VERSION ""

NS_ :

BS_:

BU_: Sound_A Ladegeraet_PAG_PF Motor_EDC17_Pirol PSM_Ant_Derivate GW_Routing_Derivate GW_Applikation_Derivate BMS_Hybrid Getriebe_Derivate LEH_Hybrid Motor_MED17_Hybrid Sound_I Tool Airbag Waehlhebel

BO_ 1445 OBC_CALID_CVN: 8 Ladegeraet_PAG_PF
 SG_ OBC_CVN_VLD : 7|1@1+ (1,0) [0|1] ""  BMS_Hybrid
 SG_ OBC_CALID_Index_01 m0 : 8|8@1+ (1,0) [0|255] ""  BMS_Hybrid
 SG_ OBC_CALID_Index_05 m1 : 8|8@1+ (1,0) [0|255] ""  BMS_Hybrid
 SG_ OBC_CALID_Index_09 m2 : 8|8@1+ (1,0) [0|255] ""  BMS_Hybrid
 SG_ OBC_CALID_Index_13 m3 : 8|8@1+ (1,0) [0|255] ""  BMS_Hybrid
 SG_ OBC_CALID_Index_02 m0 : 16|8@1+ (1,0) [0|255] ""  BMS_Hybrid
 SG_ OBC_CALID_Index_06 m1 : 16|8@1+ (1,0) [0|255] ""  BMS_Hybrid
 SG_ OBC_CALID_Index_10 m2 : 16|8@1+ (1,0) [0|255] ""  BMS_Hybrid
 SG_ OBC_CALID_Index_14 m3 : 16|8@1+ (1,0) [0|255] ""  BMS_Hybrid
 SG_ OBC_CALID_Index_03 m0 : 24|8@1+ (1,0) [0|255] ""  BMS_Hybrid
 SG_ OBC_CALID_Index_07 m1 : 24|8@1+ (1,0) [0|255] ""  BMS_Hybrid
 SG_ OBC_CALID_Index_11 m2 : 24|8@1+ (1,0) [0|255] ""  BMS_Hybrid
 SG_ OBC_CALID_Index_15 m3 : 24|8@1+ (1,0) [0|255] ""  BMS_Hybrid
 SG_ OBC_CALID_Index_04 m0 : 32|8@1+ (1,0) [0|255] ""  BMS_Hybrid
 SG_ OBC_CALID_Index_08 m1 : 32|8@1+ (1,0) [0|255] ""  BMS_Hybrid
 SG_ OBC_CALID_Index_12 m2 : 32|8@1+ (1,0) [0|255] ""  BMS_Hybrid
 SG_ OBC_CALID_Index_16 m3 : 32|8@1+ (1,0) [0|255] ""  BMS_Hybrid
 SG_ OBC_CVN_Byte_1 m0 : 40|8@1+ (1,0) [0|255] ""  BMS_Hybrid
 SG_ OBC_CVN_Byte_2 m1 : 40|8@1+ (1,0) [0|255] ""  BMS_Hybrid
 SG_ OBC_CVN_Byte_3 m2 : 40|8@1+ (1,0) [0|255] ""  BMS_Hybrid
 SG_ OBC_CALID_CVN_MUX M : 0|2@1+ (1,0) [0|3] ""  BMS_Hybrid
 SG_ OBC_CVN_Byte_4 m3 : 40|8@1+ (1,0) [0|255] ""  BMS_Hybrid

BO_ 1666 CCP_LE_CRO_01: 8 Tool
 SG_ CCP_LE_CRO_01_Data : 0|64@1+ (1,0) [0|1] ""  LEH_Hybrid

BO_ 2617239041 CCP_EMotor_01_DTO_01: 8 LEH_Hybrid
 SG_ CCP_LE_DTO_01_Data : 0|64@1+ (1,0) [0|1] ""  Tool

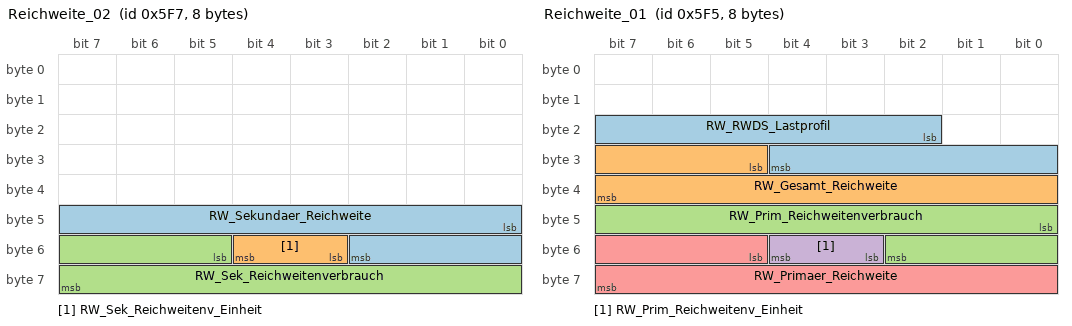
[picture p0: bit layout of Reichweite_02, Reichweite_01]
BO_ 1527 Reichweite_02: 8 BMS_Hybrid
 SG_ RW_Sekundaer_Reichweite : 40|11@1+ (1,0) [0|2044] "Unit_KiloMeter"  GW_Routing_Derivate
 SG_ RW_Sek_Reichweitenv_Einheit : 51|2@1+ (1,0) [0|3] ""  GW_Routing_Derivate
 SG_ RW_Sek_Reichweitenverbrauch : 53|11@1+ (0.1,0) [0|204.4] ""  GW_Routing_Derivate

BO_ 1525 Reichweite_01: 8 BMS_Hybrid
 SG_ RW_RWDS_Lastprofil : 18|11@1+ (1,0) [0|2045] "Unit_Amper"  GW_Routing_Derivate
 SG_ RW_Gesamt_Reichweite : 29|11@1+ (1,0) [0|2044] "Unit_KiloMeter"  GW_Routing_Derivate
 SG_ RW_Prim_Reichweitenverbrauch : 40|11@1+ (0.1,0) [0|204.4] ""  GW_Routing_Derivate
 SG_ RW_Prim_Reichweitenv_Einheit : 51|2@1+ (1,0) [0|3] ""  GW_Routing_Derivate
 SG_ RW_Primaer_Reichweite : 53|11@1+ (1,0) [0|2044] "Unit_KiloMeter"  GW_Routing_Derivate

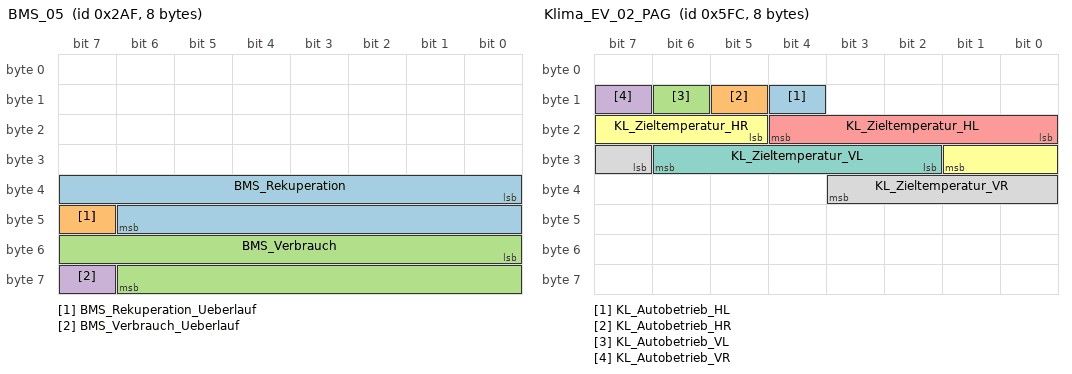
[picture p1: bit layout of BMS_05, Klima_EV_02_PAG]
BO_ 687 BMS_05: 8 BMS_Hybrid
 SG_ BMS_Rekuperation : 32|15@1+ (10,0) [0|327670] "Unit_WattSecond"  GW_Routing_Derivate
 SG_ BMS_Rekuperation_Ueberlauf : 47|1@1+ (1,0) [0|1] ""  GW_Routing_Derivate
 SG_ BMS_Verbrauch : 48|15@1+ (10,0) [0|327670] "Unit_WattSecond"  GW_Routing_Derivate
 SG_ BMS_Verbrauch_Ueberlauf : 63|1@1+ (1,0) [0|1] ""  GW_Routing_Derivate

BO_ 1532 Klima_EV_02_PAG: 8 GW_Routing_Derivate
 SG_ KL_Autobetrieb_HL : 12|1@1+ (1,0) [0|1] ""  BMS_Hybrid
 SG_ KL_Autobetrieb_HR : 13|1@1+ (1,0) [0|1] ""  BMS_Hybrid
 SG_ KL_Autobetrieb_VL : 14|1@1+ (1,0) [0|1] ""  BMS_Hybrid
 SG_ KL_Autobetrieb_VR : 15|1@1+ (1,0) [0|1] ""  BMS_Hybrid
 SG_ KL_Zieltemperatur_HL : 16|5@1+ (0.5,15.5) [16|29.5] "Unit_DegreCelsi"  BMS_Hybrid
 SG_ KL_Zieltemperatur_HR : 21|5@1+ (0.5,15.5) [16|29.5] "Unit_DegreCelsi"  BMS_Hybrid
 SG_ KL_Zieltemperatur_VL : 26|5@1+ (0.5,15.5) [16|29.5] "Unit_DegreCelsi"  BMS_Hybrid
 SG_ KL_Zieltemperatur_VR : 31|5@1+ (0.5,15.5) [16|29.5] "Unit_DegreCelsi"  BMS_Hybrid

BO_ 1788 NMH_Ladegeraet: 7 Ladegeraet_PAG_PF
 SG_ NMH_Ladegeraet_Start_1 : 0|1@1+ (1,0) [0|1] ""  Motor_MED17_Hybrid,GW_Applikation_Derivate,Getriebe_Derivate,LEH_Hybrid,BMS_Hybrid
 SG_ NMH_Ladegeraet_Start_2 : 1|1@1+ (1,0) [0|1] "" Vector__XXX
 SG_ NMH_Ladegeraet_Normal_Mode_1 : 2|1@1+ (1,0) [0|1] "" Vector__XXX
 SG_ NMH_Ladegeraet_Normal_Mode_2 : 3|1@1+ (1,0) [0|1] "" Vector__XXX
 SG_ NMH_Ladegeraet_Car_WakeUp : 6|1@1+ (1,0) [0|1] "" Vector__XXX
 SG_ NMH_Ladegeraet_Per_WakeUp : 8|5@1+ (1,0) [0|31] "" Vector__XXX
 SG_ NMH_Ladegeraet_Fkt_WakeUp : 13|3@1+ (1,0) [0|7] "" Vector__XXX
 SG_ NMH_Ladegeraet_Klemme_15 : 16|1@1+ (1,0) [0|1] "" Vector__XXX
 SG_ NMH_Ladegeraet_Diagnose : 17|1@1+ (1,0) [0|1] "" Vector__XXX
 SG_ NMH_Ladegeraet_MindestAktivZeit : 18|1@1+ (1,0) [0|1] "" Vector__XXX
 SG_ NMH_Ladegeraet_Signalfehler : 32|1@1+ (1,0) [0|1] "" Vector__XXX
 SG_ NMH_Ladegeraet_TimeOut_Fehler : 33|1@1+ (1,0) [0|1] "" Vector__XXX
 SG_ NMH_Ladegeraet_CAN_Diag_deaktiv : 34|1@1+ (1,0) [0|1] "" Vector__XXX
 SG_ NMH_Ladegeraet_KompSchutz : 35|1@1+ (1,0) [0|1] "" Vector__XXX
 SG_ NMH_Ladegeraet_Mute_Mode : 36|1@1+ (1,0) [0|1] "" Vector__XXX
 SG_ NMH_Ladegeraet_Transport_Mode : 37|1@1+ (1,0) [0|1] "" Vector__XXX
 SG_ NMH_Ladegeraet_Abschaltstufe_000 : 38|1@1+ (1,0) [0|1] "" Vector__XXX
 SG_ NMH_Ladegeraet_Eindraht_Fehler : 39|1@1+ (1,0) [0|1] "" Vector__XXX
 SG_ NMH_Ladegeraet_Lokalaktiv : 48|1@1+ (1,0) [0|1] "" Vector__XXX
 SG_ NMH_Ladegeraet_Subsystemaktiv : 49|1@1+ (1,0) [0|1] "" Vector__XXX

BO_ 1966 ISO_Ladegeraet_Resp: 8 Ladegeraet_PAG_PF
 SG_ ISO_Ladegeraet_Resp_Data : 0|64@1+ (1,0) [0|4294967295] ""  GW_Routing_Derivate

BO_ 1860 ISO_Ladegeraet_Req: 8 GW_Routing_Derivate
 SG_ ISO_Ladegeraet_Req_Data : 0|64@1+ (1,0) [0|4294967295] ""  Ladegeraet_PAG_PF

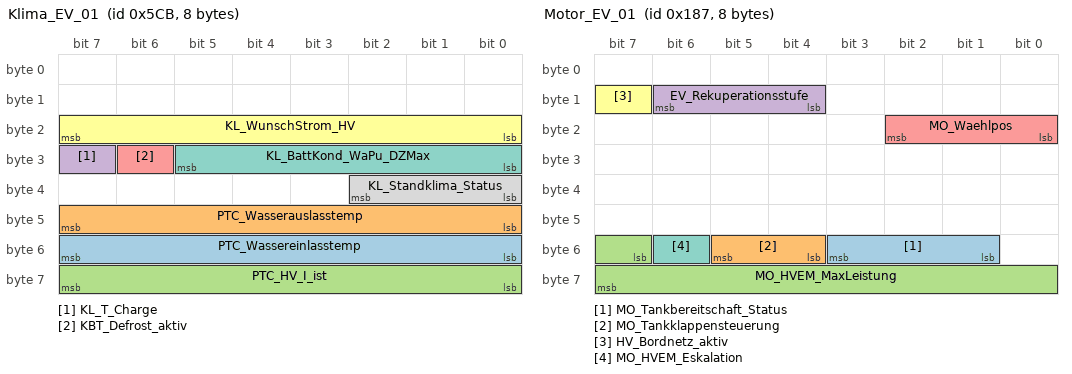
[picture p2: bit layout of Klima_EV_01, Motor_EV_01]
BO_ 1483 Klima_EV_01: 8 GW_Routing_Derivate
 SG_ PTC_Wassereinlasstemp : 48|8@1+ (1,-50) [-50|203] "Unit_DegreCelsi"  BMS_Hybrid
 SG_ PTC_Wasserauslasstemp : 40|8@1+ (1,-50) [-50|203] "Unit_DegreCelsi"  BMS_Hybrid
 SG_ PTC_HV_I_ist : 56|8@1+ (0.25,0) [0|63.25] "Unit_Amper"  Motor_MED17_Hybrid,BMS_Hybrid,Ladegeraet_PAG_PF
 SG_ KL_T_Charge : 31|1@1+ (1,0) [0|1] "" Vector__XXX
 SG_ KBT_Defrost_aktiv : 30|1@1+ (1,0) [0|1] ""  BMS_Hybrid
 SG_ KL_WunschStrom_HV : 16|8@1+ (0.25,0) [0|63.25] "Unit_Amper" Vector__XXX
 SG_ KL_BattKond_WaPu_DZMax : 24|6@1+ (2,0) [0|100] "Unit_PerCent"  BMS_Hybrid
 SG_ KL_Standklima_Status : 32|3@1+ (1,0) [0|7] ""  Ladegeraet_PAG_PF

BO_ 899 Charisma_05: 8 GW_Routing_Derivate
 SG_ CHA_Ziel_FahrPr_BMS : 12|3@1+ (1,0) [0|7] ""  BMS_Hybrid

BO_ 1518 Gateway_31_PAG: 8 GW_Routing_Derivate
 SG_ KL_T_STH : 28|1@1+ (1,0) [0|1] ""  Ladegeraet_PAG_PF
 SG_ Klima_08_PAG_alt : 3|1@1+ (1,0) [0|1] ""  Ladegeraet_PAG_PF

BO_ 391 Motor_EV_01: 8 Motor_MED17_Hybrid
 SG_ MO_Tankbereitschaft_Status : 49|3@1+ (1,0) [0|7] "" Vector__XXX
 SG_ MO_Tankklappensteuerung : 52|2@1+ (1,0) [0|3] "" Vector__XXX
 SG_ MO_HVEM_MaxLeistung : 55|9@1+ (50,0) [0|25450] "Unit_Watt"  GW_Applikation_Derivate
 SG_ EV_Rekuperationsstufe : 12|3@1+ (1,0) [0|7] "" Vector__XXX
 SG_ MO_Waehlpos : 16|3@1+ (1,0) [0|7] "" Vector__XXX
 SG_ HV_Bordnetz_aktiv : 15|1@1+ (1,0) [0|1] ""  Ladegeraet_PAG_PF,GW_Applikation_Derivate
 SG_ MO_HVEM_Eskalation : 54|1@1+ (1,0) [0|1] ""  GW_Applikation_Derivate

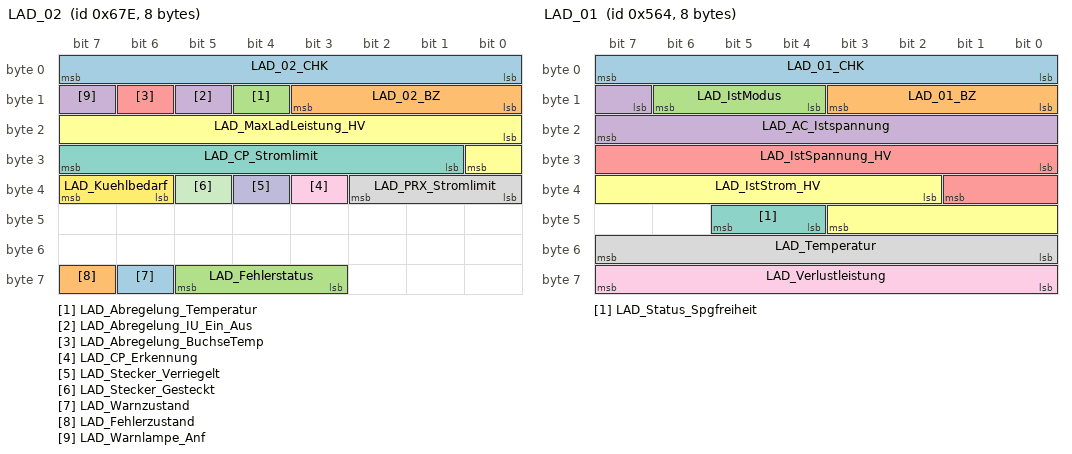
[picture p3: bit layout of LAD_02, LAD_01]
BO_ 1662 LAD_02: 8 Ladegeraet_PAG_PF
 SG_ LAD_02_CHK : 0|8@1+ (1,0) [0|255] ""  GW_Routing_Derivate
 SG_ LAD_02_BZ : 8|4@1+ (1,0) [0|15] ""  GW_Routing_Derivate
 SG_ LAD_Abregelung_Temperatur : 12|1@1+ (1,0) [0|1] ""  GW_Routing_Derivate
 SG_ LAD_Abregelung_IU_Ein_Aus : 13|1@1+ (1,0) [0|1] ""  GW_Routing_Derivate
 SG_ LAD_Abregelung_BuchseTemp : 14|1@1+ (1,0) [0|1] ""  GW_Routing_Derivate
 SG_ LAD_MaxLadLeistung_HV : 16|9@1+ (100,0) [0|50900] "Unit_Watt"  GW_Routing_Derivate,GW_Applikation_Derivate
 SG_ LAD_CP_Stromlimit : 25|7@1+ (0.5,0) [0|62.5] "Unit_Amper"  GW_Routing_Derivate
 SG_ LAD_PRX_Stromlimit : 32|3@1+ (1,0) [0|7] ""  GW_Routing_Derivate
 SG_ LAD_CP_Erkennung : 35|1@1+ (1,0) [0|1] ""  GW_Routing_Derivate
 SG_ LAD_Stecker_Verriegelt : 36|1@1+ (1,0) [0|1] ""  GW_Routing_Derivate
 SG_ LAD_Stecker_Gesteckt : 37|1@1+ (1,0) [0|1] ""  GW_Routing_Derivate
 SG_ LAD_Kuehlbedarf : 38|2@1+ (1,0) [0|3] ""  GW_Routing_Derivate
 SG_ LAD_Warnzustand : 62|1@1+ (1,0) [0|1] ""  GW_Routing_Derivate
 SG_ LAD_Fehlerzustand : 63|1@1+ (1,0) [0|1] ""  GW_Routing_Derivate
 SG_ LAD_Fehlerstatus : 59|3@1+ (1,0) [0|7] ""  GW_Routing_Derivate
 SG_ LAD_Warnlampe_Anf : 15|1@1+ (1,0) [0|1] ""  GW_Routing_Derivate

BO_ 1380 LAD_01: 8 Ladegeraet_PAG_PF
 SG_ LAD_01_CHK : 0|8@1+ (1,0) [0|255] ""  GW_Routing_Derivate
 SG_ LAD_01_BZ : 8|4@1+ (1,0) [0|15] ""  GW_Routing_Derivate
 SG_ LAD_IstModus : 12|3@1+ (1,0) [0|7] ""  GW_Applikation_Derivate,GW_Routing_Derivate
 SG_ LAD_AC_Istspannung : 15|9@1+ (1,0) [0|509] "Unit_Volt"  GW_Routing_Derivate,GW_Applikation_Derivate
 SG_ LAD_IstSpannung_HV : 24|10@1+ (1,0) [0|1021] "Unit_Volt"  GW_Routing_Derivate
 SG_ LAD_IstStrom_HV : 34|10@1+ (0.2,-102) [-102|102.2] "Unit_Amper"  GW_Applikation_Derivate,GW_Routing_Derivate
 SG_ LAD_Status_Spgfreiheit : 44|2@1+ (1,0) [0|3] ""  GW_Routing_Derivate
 SG_ LAD_Temperatur : 48|8@1+ (1,-40) [-40|213] "Unit_DegreCelsi"  GW_Routing_Derivate
 SG_ LAD_Verlustleistung : 56|8@1+ (20,0) [0|5060] "Unit_Watt"  GW_Routing_Derivate

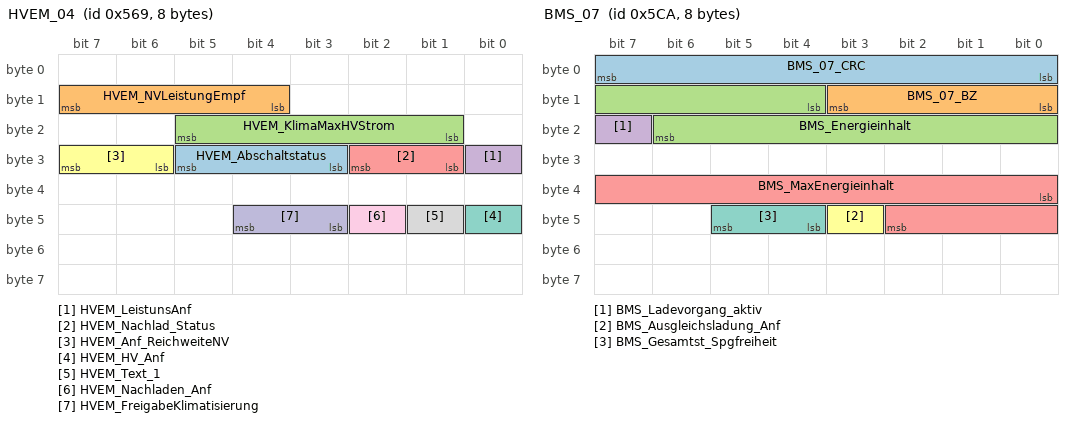
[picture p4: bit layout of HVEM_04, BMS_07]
BO_ 1385 HVEM_04: 8 GW_Applikation_Derivate
 SG_ HVEM_Abschaltstatus : 27|3@1+ (1,0) [0|7] ""  Ladegeraet_PAG_PF
 SG_ HVEM_NVLeistungEmpf : 12|4@1+ (100,0) [0|1500] "Unit_Watt" Vector__XXX
 SG_ HVEM_KlimaMaxHVStrom : 17|5@1+ (1,0) [0|31] "Unit_Amper" Vector__XXX
 SG_ HVEM_LeistunsAnf : 24|1@1+ (1,0) [0|1] "" Vector__XXX
 SG_ HVEM_Nachlad_Status : 25|2@1+ (1,0) [0|3] "" Vector__XXX
 SG_ HVEM_Anf_ReichweiteNV : 30|2@1+ (1,0) [0|3] "" Vector__XXX
 SG_ HVEM_HV_Anf : 40|1@1+ (1,0) [0|1] ""  Motor_MED17_Hybrid
 SG_ HVEM_Text_1 : 41|1@1+ (1,0) [0|1] "" Vector__XXX
 SG_ HVEM_Nachladen_Anf : 42|1@1+ (1,0) [0|1] ""  Ladegeraet_PAG_PF
 SG_ HVEM_FreigabeKlimatisierung : 43|2@1+ (1,0) [0|3] ""  BMS_Hybrid

BO_ 1482 BMS_07: 8 BMS_Hybrid
 SG_ BMS_07_CRC : 0|8@1+ (1,0) [0|255] ""  GW_Routing_Derivate
 SG_ BMS_07_BZ : 8|4@1+ (1,0) [0|15] ""  GW_Routing_Derivate
 SG_ BMS_Energieinhalt : 12|11@1+ (50,0) [0|102250] "Unit_WattHour"  GW_Routing_Derivate
 SG_ BMS_Ladevorgang_aktiv : 23|1@1+ (1,0) [0|1] ""  GW_Routing_Derivate
 SG_ BMS_MaxEnergieinhalt : 32|11@1+ (50,0) [0|102250] ""  GW_Routing_Derivate
 SG_ BMS_Ausgleichsladung_Anf : 43|1@1+ (1,0) [0|1] ""  GW_Routing_Derivate
 SG_ BMS_Gesamtst_Spgfreiheit : 44|2@1+ (1,0) [0|3] ""  GW_Routing_Derivate

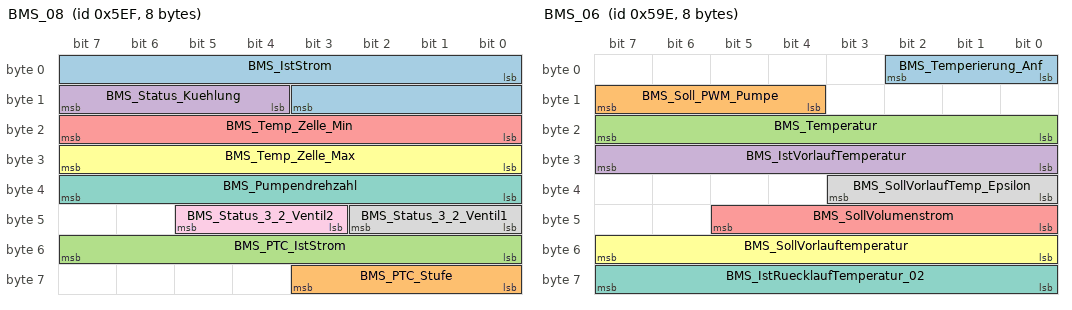
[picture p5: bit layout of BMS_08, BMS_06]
BO_ 1519 BMS_08: 8 BMS_Hybrid
 SG_ BMS_IstStrom : 0|12@1+ (0.25,-511) [-511|512.25] "Unit_Amper"  GW_Applikation_Derivate,GW_Routing_Derivate
 SG_ BMS_PTC_Stufe : 56|4@1+ (10,0) [0|100] "Unit_PerCent"  GW_Routing_Derivate
 SG_ BMS_PTC_IstStrom : 48|8@1+ (0.1,0) [0|25.2] "Unit_Amper"  Motor_MED17_Hybrid,GW_Applikation_Derivate,GW_Routing_Derivate
 SG_ BMS_Status_Kuehlung : 12|4@1+ (1,0) [0|15] ""  GW_Routing_Derivate,GW_Applikation_Derivate
 SG_ BMS_Temp_Zelle_Min : 16|8@1+ (0.5,-40) [-40|86.5] "Unit_DegreCelsi"  GW_Routing_Derivate
 SG_ BMS_Temp_Zelle_Max : 24|8@1+ (0.5,-40) [-40|86.5] "Unit_DegreCelsi"  GW_Routing_Derivate
 SG_ BMS_Pumpendrehzahl : 32|8@1+ (0.5,0) [0|100] "Unit_PerCent"  GW_Routing_Derivate
 SG_ BMS_Status_3_2_Ventil1 : 40|3@1+ (1,0) [0|7] ""  GW_Routing_Derivate
 SG_ BMS_Status_3_2_Ventil2 : 43|3@1+ (1,0) [0|7] ""  GW_Routing_Derivate

BO_ 1438 BMS_06: 8 BMS_Hybrid
 SG_ BMS_Temperierung_Anf : 0|3@1+ (1,0) [0|7] ""  GW_Routing_Derivate
 SG_ BMS_Soll_PWM_Pumpe : 12|4@1+ (10,0) [0|100] "Unit_PerCent"  GW_Routing_Derivate
 SG_ BMS_Temperatur : 16|8@1+ (0.5,-40) [-40|86.5] "Unit_DegreCelsi"  GW_Routing_Derivate
 SG_ BMS_IstVorlaufTemperatur : 24|8@1+ (0.5,-40) [-40|86.5] "Unit_DegreCelsi"  GW_Routing_Derivate
 SG_ BMS_SollVolumenstrom : 40|6@1+ (1,0) [0|61] ""  GW_Routing_Derivate
 SG_ BMS_SollVorlauftemperatur : 48|8@1+ (0.5,-40) [-40|86.5] "Unit_DegreCelsi"  GW_Routing_Derivate
 SG_ BMS_IstRuecklaufTemperatur_02 : 56|8@1+ (0.5,-40) [-40|86.5] "Unit_DegreCelsi"  GW_Routing_Derivate
 SG_ BMS_SollVorlaufTemp_Epsilon : 32|4@1+ (2,0) [0|30] "Unit_DegreCelsi"  GW_Routing_Derivate

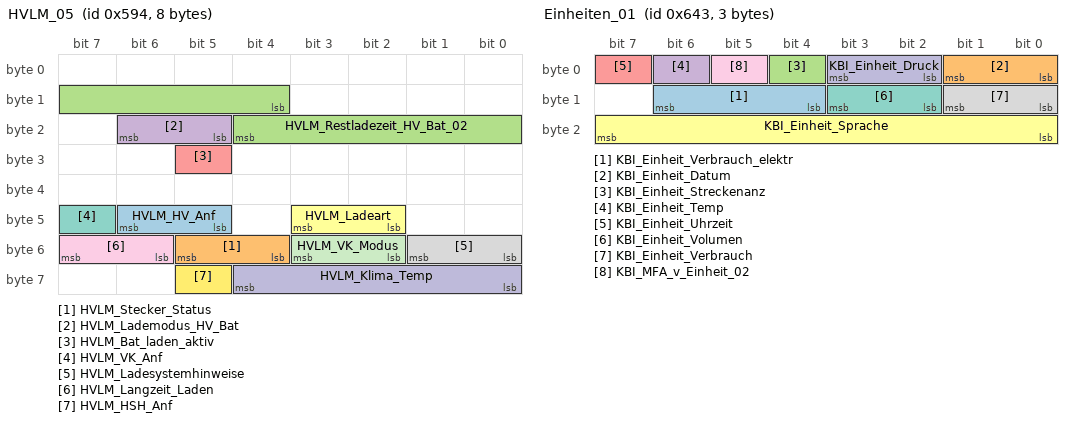
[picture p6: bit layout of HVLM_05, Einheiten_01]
BO_ 1428 HVLM_05: 8 Ladegeraet_PAG_PF
 SG_ HVLM_HV_Anf : 45|2@1+ (1,0) [0|3] ""  GW_Applikation_Derivate,GW_Routing_Derivate
 SG_ HVLM_Stecker_Status : 52|2@1+ (1,0) [0|3] ""  GW_Applikation_Derivate,BMS_Hybrid,GW_Routing_Derivate
 SG_ HVLM_Restladezeit_HV_Bat_02 : 12|9@1+ (5,0) [0|2545] "Unit_Minut"  GW_Routing_Derivate
 SG_ HVLM_Lademodus_HV_Bat : 21|2@1+ (1,0) [0|3] ""  GW_Routing_Derivate
 SG_ HVLM_Bat_laden_aktiv : 29|1@1+ (1,0) [0|1] ""  GW_Applikation_Derivate,GW_Routing_Derivate
 SG_ HVLM_Ladeart : 42|2@1+ (1,0) [0|3] ""  GW_Routing_Derivate
 SG_ HVLM_VK_Anf : 47|1@1+ (1,0) [0|1] ""  GW_Applikation_Derivate,GW_Routing_Derivate
 SG_ HVLM_Ladesystemhinweise : 48|2@1+ (1,0) [0|3] ""  GW_Routing_Derivate
 SG_ HVLM_Langzeit_Laden : 54|2@1+ (1,0) [0|3] ""  GW_Routing_Derivate,BMS_Hybrid
 SG_ HVLM_Klima_Temp : 56|5@1+ (0.5,15.5) [15.5|29.5] "Unit_DegreCelsi"  GW_Routing_Derivate
 SG_ HVLM_VK_Modus : 50|2@1+ (1,0) [0|3] ""  GW_Routing_Derivate
 SG_ HVLM_HSH_Anf : 61|1@1+ (1,0) [0|1] ""  GW_Routing_Derivate

BO_ 24 WFS_MSG4_IMS: 8 LEH_Hybrid
 SG_ WFS_MSG4_IMS : 0|64@1+ (1,0) [0|1.84467440737096E+019] ""  GW_Routing_Derivate

BO_ 25 WFS_IMS_MSG4: 8 GW_Routing_Derivate
 SG_ WFS_IMS_MSG4 : 0|64@1+ (1,0) [0|1.84467440737096E+019] ""  LEH_Hybrid

BO_ 1603 Einheiten_01: 3 GW_Routing_Derivate
 SG_ KBI_Einheit_Verbrauch_elektr : 12|3@1+ (1,0) [0|7] "" Vector__XXX
 SG_ KBI_Einheit_Datum : 0|2@1+ (1,0) [0|3] "" Vector__XXX
 SG_ KBI_Einheit_Streckenanz : 4|1@1+ (1,0) [0|1] ""  Motor_EDC17_Pirol
 SG_ KBI_Einheit_Temp : 6|1@1+ (1,0) [0|1] "" Vector__XXX
 SG_ KBI_Einheit_Uhrzeit : 7|1@1+ (1,0) [0|1] "" Vector__XXX
 SG_ KBI_Einheit_Sprache : 16|8@1+ (1,0) [0|255] "" Vector__XXX
 SG_ KBI_Einheit_Volumen : 10|2@1+ (1,0) [0|3] "" Vector__XXX
 SG_ KBI_Einheit_Verbrauch : 8|2@1+ (1,0) [0|3] "" Vector__XXX
 SG_ KBI_MFA_v_Einheit_02 : 5|1@1+ (1,0) [0|1] "" Vector__XXX
 SG_ KBI_Einheit_Druck : 2|2@1+ (1,0) [0|3] "" Vector__XXX

BO_ 267 LS_01_Derivate: 4 GW_Routing_Derivate
 SG_ MFL_Tip_Up : 23|1@1+ (1,0) [0|1] ""  Getriebe_Derivate
 SG_ MFL_Tip_Down : 22|1@1+ (1,0) [0|1] ""  Getriebe_Derivate
 SG_ LS_Verstellung_Zeitluecke : 20|2@1+ (1,0) [0|3] "" Vector__XXX
 SG_ LS_Typ_Hauptschalter : 14|1@1+ (1,0) [0|1] ""  Motor_EDC17_Pirol,Motor_MED17_Hybrid
 SG_ LS_Tiptronic_Fehler : 24|1@1+ (1,0) [0|1] ""  Getriebe_Derivate
 SG_ LS_Tip_Wiederaufnahme : 19|1@1+ (1,0) [0|1] ""  Motor_EDC17_Pirol,Motor_MED17_Hybrid
 SG_ LS_Tip_Setzen : 16|1@1+ (1,0) [0|1] ""  Motor_EDC17_Pirol,Motor_MED17_Hybrid
 SG_ LS_Tip_Runter : 18|1@1+ (1,0) [0|1] ""  Motor_EDC17_Pirol,Motor_MED17_Hybrid
 SG_ LS_Tip_Hoch : 17|1@1+ (1,0) [0|1] ""  Motor_EDC17_Pirol,Motor_MED17_Hybrid
 SG_ LS_Limiter : 15|1@1+ (1,0) [0|1] ""  Motor_EDC17_Pirol,Motor_MED17_Hybrid
 SG_ LS_Hauptschalter : 12|1@1+ (1,0) [0|1] ""  Motor_EDC17_Pirol,Motor_MED17_Hybrid
 SG_ LS_Fehler : 25|1@1+ (1,0) [0|1] ""  Motor_EDC17_Pirol,Motor_MED17_Hybrid
 SG_ LS_Codierung : 26|3@1+ (1,0) [0|7] ""  Motor_EDC17_Pirol,Motor_MED17_Hybrid
 SG_ LS_Abbrechen : 13|1@1+ (1,0) [0|1] ""  Motor_EDC17_Pirol,Motor_MED17_Hybrid
 SG_ LS_01_CHK : 0|8@1+ (1,0) [0|255] ""  Motor_EDC17_Pirol,Motor_MED17_Hybrid,Getriebe_Derivate
 SG_ LS_01_BZ : 8|4@1+ (1,0) [0|15] ""  Motor_EDC17_Pirol,Motor_MED17_Hybrid,Getriebe_Derivate
 SG_ MFL_M_Taste : 31|1@1+ (1,0) [0|1] ""  Getriebe_Derivate
 SG_ LS_Tip_Stufe_2 : 29|1@1+ (1,0) [0|1] ""  Motor_EDC17_Pirol,Motor_MED17_Hybrid
 SG_ LS_GRA_ACC_2stufig : 30|1@1+ (1,0) [0|1] ""  Motor_EDC17_Pirol,Motor_MED17_Hybrid

BO_ 260 EPB_01: 8 GW_Routing_Derivate
 SG_ EPB_Konsistenz_ACC : 55|1@1+ (1,0) [0|1] "" Vector__XXX
 SG_ EPB_Anfahrwunsch_erkannt : 48|1@1+ (1,0) [0|1] "" Vector__XXX
 SG_ EPB_Pedalweg_Kuppl : 32|8@1+ (0.4,0) [8|92] "%"  Motor_EDC17_Pirol,Motor_MED17_Hybrid
 SG_ EPB_Fehlerstatus : 50|2@1+ (1,0) [0|3] ""  Motor_MED17_Hybrid
 SG_ EPB_Schalterposition : 52|2@1+ (1,0) [0|3] ""  Motor_EDC17_Pirol,Motor_MED17_Hybrid
 SG_ EPB_QBit_Schalterpos : 54|1@1+ (1,0) [0|1] ""  Motor_EDC17_Pirol,Motor_MED17_Hybrid
 SG_ EPB_Spannkraft : 56|5@1+ (1,0) [0|29] "kN" Vector__XXX
 SG_ EPB_Status : 61|2@1+ (1,0) [0|3] ""  Motor_EDC17_Pirol,Getriebe_Derivate,Motor_MED17_Hybrid
 SG_ EPB_KD_Fehler : 63|1@1+ (1,0) [0|1] "" Vector__XXX
 SG_ EPB_01_CHK : 0|8@1+ (1,0) [0|255] ""  Getriebe_Derivate,Motor_EDC17_Pirol,Motor_MED17_Hybrid
 SG_ EPB_01_BZ : 8|4@1+ (1,0) [0|15] ""  Getriebe_Derivate,Motor_EDC17_Pirol,Motor_MED17_Hybrid
 SG_ EPB_QBit_Laengsbeschleunigung : 12|1@1+ (1,0) [0|1] "" Vector__XXX
 SG_ EPB_QBit_Pedalweg_Kuppl : 13|1@1+ (1,0) [0|1] ""  Motor_EDC17_Pirol,Motor_MED17_Hybrid
 SG_ EPB_BCM2_Motor_Wakeup : 14|1@1+ (1,0) [0|1] "" Vector__XXX
 SG_ EPB_Freig_Verzoeg_Anf : 15|1@1+ (1,0) [0|1] ""  Motor_EDC17_Pirol,Motor_MED17_Hybrid
 SG_ EPB_Verzoeg_Anf : 16|8@1+ (0.048,-7.968) [-7.968|4.224] "m/s2" Vector__XXX
 SG_ EPB_Laengsbeschleunigung : 24|8@1+ (1,-128) [-128|126] "%g" Vector__XXX

BO_ 64 Airbag_01: 8 Airbag
 SG_ AB_Deaktivierung_HV : 42|3@1+ (1,0) [0|7] ""  GW_Routing_Derivate
 SG_ AB_RGS_Anst : 12|4@1+ (1,0) [0|15] ""  GW_Routing_Derivate
 SG_ AB_Texte_AKS : 36|2@1+ (1,0) [0|3] ""  GW_Routing_Derivate
 SG_ Airbag_01_CHK : 0|8@1+ (1,0) [0|255] ""  GW_Routing_Derivate,Motor_EDC17_Pirol,Getriebe_Derivate,Motor_MED17_Hybrid,LEH_Hybrid,BMS_Hybrid
 SG_ Airbag_01_BZ : 8|4@1+ (1,0) [0|15] ""  GW_Routing_Derivate,Motor_EDC17_Pirol,Getriebe_Derivate,Motor_MED17_Hybrid,LEH_Hybrid,BMS_Hybrid
 SG_ AB_Front_Crash : 16|1@1+ (1,0) [0|1] ""  GW_Routing_Derivate,GW_Applikation_Derivate
 SG_ AB_Heck_Crash : 17|1@1+ (1,0) [0|1] ""  GW_Routing_Derivate,GW_Applikation_Derivate
 SG_ AB_SF_Crash : 18|1@1+ (1,0) [0|1] ""  GW_Routing_Derivate,GW_Applikation_Derivate
 SG_ AB_SB_Crash : 19|1@1+ (1,0) [0|1] ""  GW_Routing_Derivate,GW_Applikation_Derivate
 SG_ AB_Rollover_Crash : 20|1@1+ (1,0) [0|1] ""  GW_Routing_Derivate,GW_Applikation_Derivate
 SG_ AB_Crash_Int : 21|3@1+ (1,0) [0|7] ""  GW_Routing_Derivate,Motor_EDC17_Pirol,Getriebe_Derivate,Motor_MED17_Hybrid,LEH_Hybrid,BMS_Hybrid
 SG_ AB_Lampe : 24|1@1+ (1,0) [0|1] ""  GW_Routing_Derivate
 SG_ AB_Deaktiviert : 25|1@1+ (1,0) [0|1] ""  GW_Routing_Derivate
 SG_ AB_VB_deaktiviert : 26|1@1+ (1,0) [0|1] ""  GW_Routing_Derivate
 SG_ AB_Systemfehler : 27|1@1+ (1,0) [0|1] ""  GW_Routing_Derivate,LEH_Hybrid,BMS_Hybrid
 SG_ AB_Diagnose : 28|1@1+ (1,0) [0|1] ""  GW_Routing_Derivate
 SG_ AB_Anzeige_Fussg : 34|2@1+ (1,0) [0|3] ""  GW_Routing_Derivate
 SG_ AB_PAO_Leuchte_Anf : 38|1@1+ (1,0) [0|1] ""  GW_Routing_Derivate
 SG_ AB_Stellgliedtest : 29|1@1+ (1,0) [0|1] ""  LEH_Hybrid,GW_Routing_Derivate,Motor_EDC17_Pirol,BMS_Hybrid,Motor_MED17_Hybrid
 SG_ AB_Erh_Auf_VB : 30|2@1+ (1,0) [0|3] ""  GW_Routing_Derivate
 SG_ AB_Gurtwarn_VF : 32|1@1+ (1,0) [0|1] ""  GW_Routing_Derivate
 SG_ AB_Gurtwarn_VB : 33|1@1+ (1,0) [0|1] ""  GW_Routing_Derivate
 SG_ void_Byte_02 : 48|8@1+ (1,0) [0|255] ""  GW_Routing_Derivate
 SG_ void_Byte_03 : 56|7@1+ (1,0) [0|127] ""  GW_Routing_Derivate
 SG_ AB_KD_Fehler : 63|1@1+ (1,0) [0|1] ""  GW_Routing_Derivate,GW_Applikation_Derivate

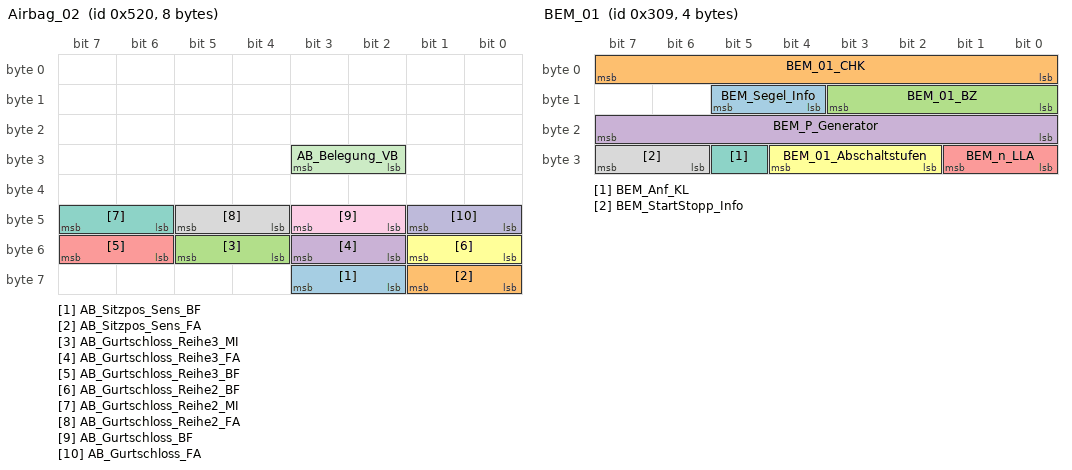
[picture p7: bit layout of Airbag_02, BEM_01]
BO_ 1312 Airbag_02: 8 Airbag
 SG_ AB_Sitzpos_Sens_BF : 58|2@1+ (1,0) [0|3] "" Vector__XXX
 SG_ AB_Sitzpos_Sens_FA : 56|2@1+ (1,0) [0|3] "" Vector__XXX
 SG_ AB_Gurtschloss_Reihe3_MI : 52|2@1+ (1,0) [0|3] "" Vector__XXX
 SG_ AB_Gurtschloss_Reihe3_FA : 50|2@1+ (1,0) [0|3] "" Vector__XXX
 SG_ AB_Gurtschloss_Reihe3_BF : 54|2@1+ (1,0) [0|3] "" Vector__XXX
 SG_ AB_Gurtschloss_Reihe2_BF : 48|2@1+ (1,0) [0|3] "" Vector__XXX
 SG_ AB_Gurtschloss_Reihe2_MI : 46|2@1+ (1,0) [0|3] "" Vector__XXX
 SG_ AB_Gurtschloss_Reihe2_FA : 44|2@1+ (1,0) [0|3] "" Vector__XXX
 SG_ AB_Gurtschloss_BF : 42|2@1+ (1,0) [0|3] "" Vector__XXX
 SG_ AB_Gurtschloss_FA : 40|2@1+ (1,0) [0|3] ""  GW_Routing_Derivate,Motor_EDC17_Pirol,Motor_MED17_Hybrid
 SG_ AB_Belegung_VB : 26|2@1+ (1,0) [0|3] "" Vector__XXX

BO_ 777 BEM_01: 4 GW_Applikation_Derivate
 SG_ BEM_Segel_Info : 12|2@1+ (1,0) [0|3] "" Vector__XXX
 SG_ BEM_01_CHK : 0|8@1+ (1,0) [0|255] ""  Motor_EDC17_Pirol,Motor_MED17_Hybrid
 SG_ BEM_01_BZ : 8|4@1+ (1,0) [0|15] ""  Motor_EDC17_Pirol,Motor_MED17_Hybrid
 SG_ BEM_P_Generator : 16|8@1+ (50,0) [0|12750] "W"  Motor_EDC17_Pirol
 SG_ BEM_n_LLA : 24|2@1+ (1,0) [0|3] ""  Motor_EDC17_Pirol
 SG_ BEM_01_Abschaltstufen : 26|3@1+ (1,0) [0|7] "" Vector__XXX
 SG_ BEM_Anf_KL : 29|1@1+ (1,0) [0|1] ""  Motor_EDC17_Pirol,Motor_MED17_Hybrid
 SG_ BEM_StartStopp_Info : 30|2@1+ (1,0) [0|3] ""  Motor_EDC17_Pirol,Motor_MED17_Hybrid

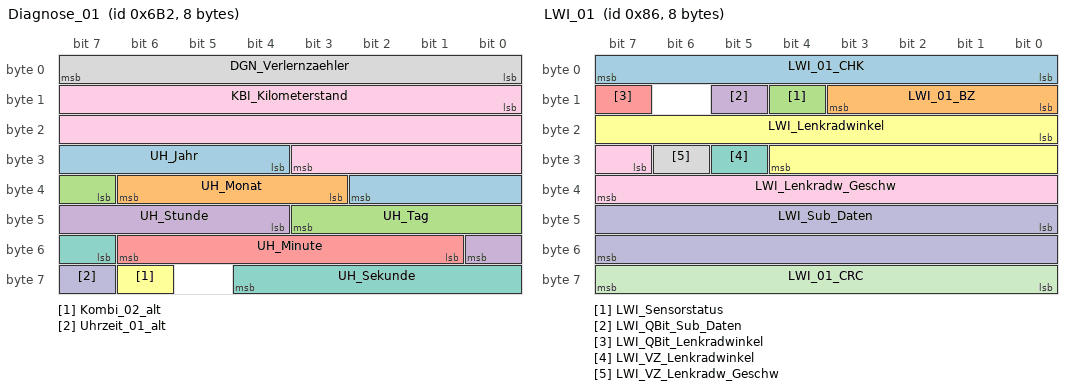
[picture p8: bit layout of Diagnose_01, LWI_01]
BO_ 1714 Diagnose_01: 8 GW_Applikation_Derivate
 SG_ UH_Jahr : 28|7@1+ (1,2000) [2000|2127] "Jahr"  Ladegeraet_PAG_PF,Motor_EDC17_Pirol,PSM_Ant_Derivate,Waehlhebel,Motor_MED17_Hybrid,LEH_Hybrid,Getriebe_Derivate,BMS_Hybrid,Airbag
 SG_ UH_Monat : 35|4@1+ (1,0) [1|12] "Monat"  Ladegeraet_PAG_PF,Motor_EDC17_Pirol,PSM_Ant_Derivate,Waehlhebel,Getriebe_Derivate,Motor_MED17_Hybrid,LEH_Hybrid,BMS_Hybrid,Airbag
 SG_ UH_Tag : 39|5@1+ (1,0) [1|31] "Tag"  Ladegeraet_PAG_PF,Motor_EDC17_Pirol,PSM_Ant_Derivate,Waehlhebel,Getriebe_Derivate,Motor_MED17_Hybrid,LEH_Hybrid,BMS_Hybrid,Airbag
 SG_ UH_Stunde : 44|5@1+ (1,0) [0|23] "h"  Ladegeraet_PAG_PF,Motor_EDC17_Pirol,PSM_Ant_Derivate,Waehlhebel,Getriebe_Derivate,Motor_MED17_Hybrid,LEH_Hybrid,BMS_Hybrid,Airbag
 SG_ UH_Minute : 49|6@1+ (1,0) [0|59] "min"  Ladegeraet_PAG_PF,Motor_EDC17_Pirol,PSM_Ant_Derivate,Waehlhebel,Getriebe_Derivate,Motor_MED17_Hybrid,LEH_Hybrid,BMS_Hybrid,Airbag
 SG_ Kombi_02_alt : 62|1@1+ (1,0) [0|1] ""  Airbag,BMS_Hybrid,LEH_Hybrid,Waehlhebel
 SG_ UH_Sekunde : 55|6@1+ (1,0) [0|59] "s"  Ladegeraet_PAG_PF,Motor_EDC17_Pirol,PSM_Ant_Derivate,Waehlhebel,Getriebe_Derivate,Motor_MED17_Hybrid,LEH_Hybrid,BMS_Hybrid,Airbag
 SG_ DGN_Verlernzaehler : 0|8@1+ (1,0) [0|254] ""  Ladegeraet_PAG_PF,Waehlhebel,LEH_Hybrid,BMS_Hybrid,Airbag
 SG_ KBI_Kilometerstand : 8|20@1+ (1,0) [0|1048573] "km"  Ladegeraet_PAG_PF,Motor_EDC17_Pirol,PSM_Ant_Derivate,Waehlhebel,Motor_MED17_Hybrid,LEH_Hybrid,BMS_Hybrid,Getriebe_Derivate,Airbag
 SG_ Uhrzeit_01_alt : 63|1@1+ (1,0) [0|1] ""  PSM_Ant_Derivate,Airbag,BMS_Hybrid,LEH_Hybrid,Waehlhebel,Ladegeraet_PAG_PF

BO_ 1313 STH_01: 8 GW_Routing_Derivate
 SG_ STH_Funk_ein : 0|1@1+ (1,0) [0|1] "" Vector__XXX
 SG_ STH_Funk_aus : 1|1@1+ (1,0) [0|1] "" Vector__XXX
 SG_ STH_Zusatzheizung : 2|1@1+ (1,0) [0|1] "" Vector__XXX
 SG_ STH_LED : 3|1@1+ (1,0) [0|1] ""  Motor_EDC17_Pirol
 SG_ STH_Pumpe_ein : 4|1@1+ (1,0) [0|1] "" Vector__XXX
 SG_ STH_Geblaese : 5|1@1+ (1,0) [0|1] "" Vector__XXX
 SG_ STH_EKP_Anst : 6|1@1+ (1,0) [0|1] ""  Motor_EDC17_Pirol
 SG_ STH_Ventiloeffnungszeit : 8|6@1+ (1,0) [0|63] "min" Vector__XXX
 SG_ STH_Waermeeintrag : 16|6@1+ (1,0) [0|63] "" Vector__XXX
 SG_ STH_KVS : 24|13@1+ (1,0) [0|8191] "ml" Vector__XXX
 SG_ STH_Fehlerstatus : 37|3@1+ (1,0) [0|7] "" Vector__XXX
 SG_ STH_Heizleistung : 40|8@1+ (1,0) [0|255] "" Vector__XXX
 SG_ STH_Wassertemp : 48|8@1+ (0.75,-40) [-40|142.5] "°C" Vector__XXX
 SG_ STH_Motorvorwaermung : 59|1@1+ (1,0) [0|1] ""  Motor_EDC17_Pirol
 SG_ STH_Servicemode : 60|1@1+ (1,0) [0|1] "" Vector__XXX
 SG_ STH_war_aktiv : 61|1@1+ (1,0) [0|1] ""  Motor_EDC17_Pirol
 SG_ STH_KVS_Ueberlauf : 62|1@1+ (1,0) [0|1] "" Vector__XXX
 SG_ STH_Start_folgt : 7|1@1+ (1,0) [0|1] "" Vector__XXX
 SG_ STH_KD_Fehler : 63|1@1+ (1,0) [0|1] "" Vector__XXX

BO_ 134 LWI_01: 8 GW_Routing_Derivate
 SG_ LWI_01_CHK : 0|8@1+ (1,0) [0|255] ""  Motor_EDC17_Pirol,Motor_MED17_Hybrid
 SG_ LWI_01_BZ : 8|4@1+ (1,0) [0|15] ""  Motor_EDC17_Pirol,Motor_MED17_Hybrid
 SG_ LWI_Sensorstatus : 12|1@1+ (1,0) [0|1] ""  Motor_EDC17_Pirol,Motor_MED17_Hybrid
 SG_ LWI_QBit_Sub_Daten : 13|1@1+ (1,0) [0|1] "" Vector__XXX
 SG_ LWI_QBit_Lenkradwinkel : 15|1@1+ (1,0) [0|1] ""  Motor_EDC17_Pirol,Motor_MED17_Hybrid
 SG_ LWI_Lenkradwinkel : 16|13@1+ (0.1,0) [0|818.8] "Grad"  Motor_EDC17_Pirol,Motor_MED17_Hybrid
 SG_ LWI_VZ_Lenkradwinkel : 29|1@1+ (1,0) [0|1] ""  Motor_EDC17_Pirol,Motor_MED17_Hybrid
 SG_ LWI_VZ_Lenkradw_Geschw : 30|1@1+ (1,0) [0|1] "" Vector__XXX
 SG_ LWI_Lenkradw_Geschw : 31|9@1+ (5,0) [0|2555] "Grad/s" Vector__XXX
 SG_ LWI_Sub_Daten : 40|16@1+ (1,0) [0|65535] "" Vector__XXX
 SG_ LWI_01_CRC : 56|8@1+ (1,0) [0|255] "" Vector__XXX

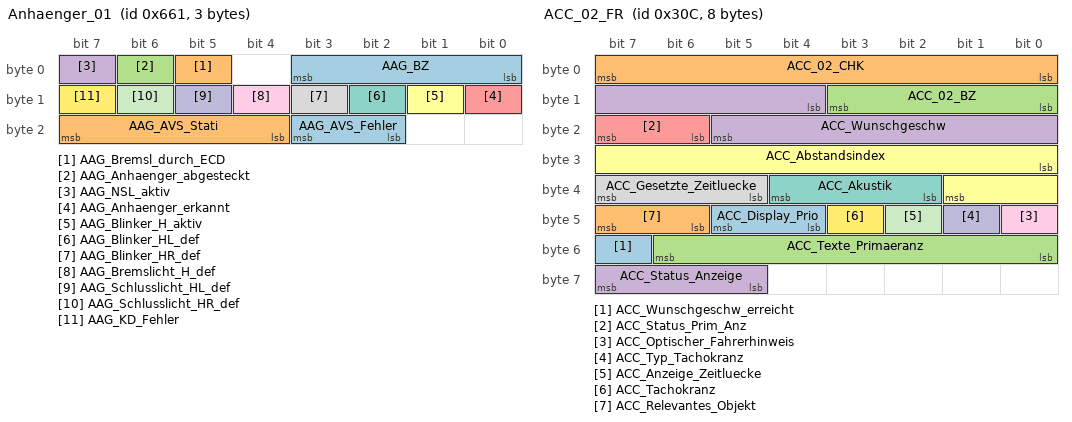
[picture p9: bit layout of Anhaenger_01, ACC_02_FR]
BO_ 1633 Anhaenger_01: 3 GW_Routing_Derivate
 SG_ AAG_BZ : 0|4@1+ (1,0) [0|15] ""  Motor_EDC17_Pirol,Motor_MED17_Hybrid
 SG_ AAG_Bremsl_durch_ECD : 5|1@1+ (1,0) [0|1] ""  Motor_EDC17_Pirol,Motor_MED17_Hybrid
 SG_ AAG_Anhaenger_abgesteckt : 6|1@1+ (1,0) [0|1] "" Vector__XXX
 SG_ AAG_NSL_aktiv : 7|1@1+ (1,0) [0|1] "" Vector__XXX
 SG_ AAG_Anhaenger_erkannt : 8|1@1+ (1,0) [0|1] ""  Motor_EDC17_Pirol,Motor_MED17_Hybrid
 SG_ AAG_Blinker_H_aktiv : 9|1@1+ (1,0) [0|1] "" Vector__XXX
 SG_ AAG_Blinker_HL_def : 10|1@1+ (1,0) [0|1] "" Vector__XXX
 SG_ AAG_Blinker_HR_def : 11|1@1+ (1,0) [0|1] "" Vector__XXX
 SG_ AAG_Bremslicht_H_def : 12|1@1+ (1,0) [0|1] ""  Motor_EDC17_Pirol,Motor_MED17_Hybrid
 SG_ AAG_Schlusslicht_HL_def : 13|1@1+ (1,0) [0|1] "" Vector__XXX
 SG_ AAG_Schlusslicht_HR_def : 14|1@1+ (1,0) [0|1] "" Vector__XXX
 SG_ AAG_KD_Fehler : 15|1@1+ (1,0) [0|1] "" Vector__XXX
 SG_ AAG_AVS_Fehler : 18|2@1+ (1,0) [0|3] "" Vector__XXX
 SG_ AAG_AVS_Stati : 20|4@1+ (1,0) [0|15] "" Vector__XXX

BO_ 780 ACC_02_FR: 8 GW_Routing_Derivate
 SG_ ACC_Wunschgeschw_erreicht : 55|1@1+ (1,0) [0|1] "" Vector__XXX
 SG_ ACC_02_CHK : 0|8@1+ (1,0) [0|255] ""  Getriebe_Derivate
 SG_ ACC_02_BZ : 8|4@1+ (1,0) [0|15] ""  Getriebe_Derivate
 SG_ ACC_Wunschgeschw : 12|10@1+ (0.32,0) [0|326.72] "km/h"  Getriebe_Derivate
 SG_ ACC_Status_Prim_Anz : 22|2@1+ (1,0) [0|3] "" Vector__XXX
 SG_ ACC_Abstandsindex : 24|10@1+ (1,0) [1|1021] "" Vector__XXX
 SG_ ACC_Akustik : 34|3@1+ (1,0) [0|7] "" Vector__XXX
 SG_ ACC_Gesetzte_Zeitluecke : 37|3@1+ (1,0) [0|7] "" Vector__XXX
 SG_ ACC_Optischer_Fahrerhinweis : 40|1@1+ (1,0) [0|1] "" Vector__XXX
 SG_ ACC_Typ_Tachokranz : 41|1@1+ (1,0) [0|1] "" Vector__XXX
 SG_ ACC_Anzeige_Zeitluecke : 42|1@1+ (1,0) [0|1] "" Vector__XXX
 SG_ ACC_Tachokranz : 43|1@1+ (1,0) [0|1] "" Vector__XXX
 SG_ ACC_Display_Prio : 44|2@1+ (1,0) [0|3] "" Vector__XXX
 SG_ ACC_Relevantes_Objekt : 46|2@1+ (1,0) [0|3] "" Vector__XXX
 SG_ ACC_Texte_Primaeranz : 48|7@1+ (1,0) [0|127] "" Vector__XXX
 SG_ ACC_Status_Anzeige : 61|3@1+ (1,0) [0|7] "" Vector__XXX

BO_ 1743 NMH_EM: 7 LEH_Hybrid
 SG_ NMH_EM_keine_HV_Entl : 19|1@1+ (1,0) [0|1] "" Vector__XXX
 SG_ NMH_EM_Start_1 : 0|1@1+ (1,0) [0|1] ""  Getriebe_Derivate,BMS_Hybrid,Motor_MED17_Hybrid,Ladegeraet_PAG_PF
 SG_ NMH_EM_Start_2 : 1|1@1+ (1,0) [0|1] "" Vector__XXX
 SG_ NMH_EM_Normal_Mode_1 : 2|1@1+ (1,0) [0|1] "" Vector__XXX
 SG_ NMH_EM_Normal_Mode_2 : 3|1@1+ (1,0) [0|1] "" Vector__XXX
 SG_ NMH_EM_Car_WakeUp : 6|1@1+ (1,0) [0|1] "" Vector__XXX
 SG_ NMH_EM_Per_WakeUp : 8|5@1+ (1,0) [0|31] "" Vector__XXX
 SG_ NMH_EM_Fkt_WakeUp : 13|3@1+ (1,0) [0|7] "" Vector__XXX
 SG_ NMH_EM_Klemme_15 : 16|1@1+ (1,0) [0|1] "" Vector__XXX
 SG_ NMH_EM_Diagnose : 17|1@1+ (1,0) [0|1] "" Vector__XXX
 SG_ NMH_EM_MindestAktivZeit : 18|1@1+ (1,0) [0|1] "" Vector__XXX
 SG_ NMH_EM_NL_Datem_EEPROM : 24|1@1+ (1,0) [0|1] "" Vector__XXX
 SG_ NMH_EM_Signalfehler : 32|1@1+ (1,0) [0|1] "" Vector__XXX
 SG_ NMH_EM_TimeOut_Fehler : 33|1@1+ (1,0) [0|1] "" Vector__XXX
 SG_ NMH_EM_CAN_Diag_deaktiv : 34|1@1+ (1,0) [0|1] "" Vector__XXX
 SG_ NMH_EM_KompSchutz : 35|1@1+ (1,0) [0|1] "" Vector__XXX
 SG_ NMH_EM_Mute_Mode : 36|1@1+ (1,0) [0|1] "" Vector__XXX
 SG_ NMH_EM_Transport_Mode : 37|1@1+ (1,0) [0|1] "" Vector__XXX
 SG_ NMH_EM_Abschaltstufe_aktiv : 38|1@1+ (1,0) [0|1] "" Vector__XXX
 SG_ NMH_EM_Busfehler : 39|1@1+ (1,0) [0|1] "" Vector__XXX
 SG_ NMH_EM_Lokalaktiv : 48|1@1+ (1,0) [0|1] "" Vector__XXX
 SG_ NMH_EM_Subsystemaktiv : 49|1@1+ (1,0) [0|1] "" Vector__XXX

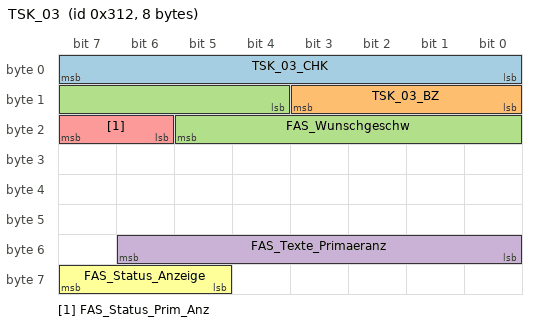
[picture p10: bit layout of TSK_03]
BO_ 786 TSK_03: 8 Motor_MED17_Hybrid
 SG_ TSK_03_CHK : 0|8@1+ (1,0) [0|255] ""  GW_Routing_Derivate,Getriebe_Derivate
 SG_ TSK_03_BZ : 8|4@1+ (1,0) [0|15] ""  GW_Routing_Derivate,Getriebe_Derivate
 SG_ FAS_Wunschgeschw : 12|10@1+ (0.32,0) [0|326.72] "Unit_KiloMeterPerHour"  GW_Routing_Derivate,Getriebe_Derivate
 SG_ FAS_Texte_Primaeranz : 48|7@1+ (1,0) [0|127] ""  GW_Routing_Derivate
 SG_ FAS_Status_Prim_Anz : 22|2@1+ (1,0) [0|3] ""  GW_Routing_Derivate
 SG_ FAS_Status_Anzeige : 61|3@1+ (1,0) [0|7] ""  GW_Routing_Derivate

BO_ 16 WFS_MSG1_IMS: 8 Motor_MED17_Hybrid
 SG_ WFS_MSG1_IMS : 0|64@1+ (1,0) [0|1.84467440737096E+019] ""  GW_Routing_Derivate

BO_TX_BU_ 786 : Motor_EDC17_Pirol,Motor_MED17_Hybrid;
BO_TX_BU_ 16 : Motor_EDC17_Pirol,Motor_MED17_Hybrid;
CM_ SG_ 1445 OBC_CVN_VLD "Valid-Bit der Calibration-Verification-Number (CVN bzw. Checksumme)";
CM_ SG_ 1445 OBC_CALID_Index_01 "Software-Calibration-Identification (CALID) im ASCII-Zeichenformat; 
für Ausgabe an das Generic Scan-Tool für OBD in NAR

0x30 entspricht ASCII '0'";
CM_ SG_ 1445 OBC_CALID_Index_05 "Software-Calibration-Identification (CALID) im ASCII-Zeichenformat; 
für Ausgabe an das Generic Scan-Tool für OBD in NAR

0x30 entspricht ASCII '0'";
CM_ SG_ 1445 OBC_CALID_Index_09 "Software-Calibration-Identification (CALID) im ASCII-Zeichenformat; 
für Ausgabe an das Generic Scan-Tool für OBD in NAR

0x30 entspricht ASCII '0'";
CM_ SG_ 1445 OBC_CALID_Index_13 "Software-Calibration-Identification (CALID) im ASCII-Zeichenformat; 
für Ausgabe an das Generic Scan-Tool für OBD in NAR

0x30 entspricht ASCII '0'";
CM_ SG_ 1445 OBC_CALID_Index_02 "Software-Calibration-Identification (CALID) im ASCII-Zeichenformat; 
für Ausgabe an das Generic Scan-Tool für OBD in NAR

0x30 entspricht ASCII '0'";
CM_ SG_ 1445 OBC_CALID_Index_06 "Software-Calibration-Identification (CALID) im ASCII-Zeichenformat; 
für Ausgabe an das Generic Scan-Tool für OBD in NAR

0x30 entspricht ASCII '0'";
CM_ SG_ 1445 OBC_CALID_Index_10 "Software-Calibration-Identification (CALID) im ASCII-Zeichenformat; 
für Ausgabe an das Generic Scan-Tool für OBD in NAR

0x30 entspricht ASCII '0'";
CM_ SG_ 1445 OBC_CALID_Index_14 "Software-Calibration-Identification (CALID) im ASCII-Zeichenformat; 
für Ausgabe an das Generic Scan-Tool für OBD in NAR

0x30 entspricht ASCII '0'";
CM_ SG_ 1445 OBC_CALID_Index_03 "Software-Calibration-Identification (CALID) im ASCII-Zeichenformat; 
für Ausgabe an das Generic Scan-Tool für OBD in NAR

0x30 entspricht ASCII '0'";
CM_ SG_ 1445 OBC_CALID_Index_07 "Software-Calibration-Identification (CALID) im ASCII-Zeichenformat; 
für Ausgabe an das Generic Scan-Tool für OBD in NAR

0x30 entspricht ASCII '0'";
CM_ SG_ 1445 OBC_CALID_Index_11 "Software-Calibration-Identification (CALID) im ASCII-Zeichenformat; 
für Ausgabe an das Generic Scan-Tool für OBD in NAR

0x30 entspricht ASCII '0'";
CM_ SG_ 1445 OBC_CALID_Index_15 "Software-Calibration-Identification (CALID) im ASCII-Zeichenformat; 
für Ausgabe an das Generic Scan-Tool für OBD in NAR

0x30 entspricht ASCII '0'";
CM_ SG_ 1445 OBC_CALID_Index_04 "Software-Calibration-Identification (CALID) im ASCII-Zeichenformat; 
für Ausgabe an das Generic Scan-Tool für OBD in NAR

0x30 entspricht ASCII '0'";
CM_ SG_ 1445 OBC_CALID_Index_08 "Software-Calibration-Identification (CALID) im ASCII-Zeichenformat; 
für Ausgabe an das Generic Scan-Tool für OBD in NAR

0x30 entspricht ASCII '0'";
CM_ SG_ 1445 OBC_CALID_Index_12 "Software-Calibration-Identification (CALID) im ASCII-Zeichenformat; 
für Ausgabe an das Generic Scan-Tool für OBD in NAR

0x30 entspricht ASCII '0'";
CM_ SG_ 1445 OBC_CALID_Index_16 "Software-Calibration-Identification (CALID) im ASCII-Zeichenformat; 
für Ausgabe an das Generic Scan-Tool für OBD in NAR

0x30 entspricht ASCII '0'";
CM_ SG_ 1445 OBC_CVN_Byte_1 "Calibration Verification Number (CVN bzw. Checksumme) des SW- und Datenstandes; 
für Ausgabe an das Generic Scan-Tool für OBD in NAR";
CM_ SG_ 1445 OBC_CVN_Byte_2 "Calibration Verification Number (CVN bzw. Checksumme) des SW- und Datenstandes; 
für Ausgabe an das Generic Scan-Tool für OBD in NAR";
CM_ SG_ 1445 OBC_CVN_Byte_3 "Calibration Verification Number (CVN bzw. Checksumme) des SW- und Datenstandes; 
für Ausgabe an das Generic Scan-Tool für OBD in NAR";
CM_ SG_ 1445 OBC_CALID_CVN_MUX "Node1_CAL_ID_CVN_MUX
Alle CALID-Indizes bilden zusammen die CALID";
CM_ SG_ 1445 OBC_CVN_Byte_4 "Calibration Verification Number (CVN bzw. Checksumme) des SW- und Datenstandes; 
für Ausgabe an das Generic Scan-Tool für OBD in NAR";
CM_ BO_ 1666 "CCP in Serie mit 11Bit - Empfangskanal";
CM_ SG_ 1527 RW_Sekundaer_Reichweite "Reichweite der sekundaeren Antriebsart";
CM_ SG_ 1527 RW_Sek_Reichweitenv_Einheit "Für sekundäre Reichweitenberechnung (KBI_Sek_Reichweitenverbrauch) zugrunde gelegte Einheit";
CM_ SG_ 1527 RW_Sek_Reichweitenverbrauch "Für sekundäre Reichweitenberechnung zugrunde gelegter Verbrauch";
CM_ SG_ 1525 RW_RWDS_Lastprofil "Lastprofil zur Bestimmung der notwendigen Nachladeenergie (Reichweitendurchschnittstrom)";
CM_ SG_ 1525 RW_Gesamt_Reichweite "Reichweite für primär und sekundär Reichweite (eventuell Gewichtet)";
CM_ SG_ 1525 RW_Prim_Reichweitenverbrauch "Für primäre Reichweitenberechnung zugrunde gelegter Verbrauch";
CM_ SG_ 1525 RW_Prim_Reichweitenv_Einheit "Für primäre  Reichweitenberechnung (KBI_Prim_Reichweitenverbrauch) zugrunde gelegte Einheit";
CM_ SG_ 1525 RW_Primaer_Reichweite "Reichweite der primären Antriebsart";
CM_ SG_ 687 BMS_Rekuperation "Zähler: Anzeigesignal: Energiezufuhr in die HV-Batterie (Reku). Darf nicht durch Laden der Batterie bedatet werden";
CM_ SG_ 687 BMS_Rekuperation_Ueberlauf "Rekuperationleistungssignal BMS_Rekuperation mindest 1x übergelaufen";
CM_ SG_ 687 BMS_Verbrauch "Zähler: Energieentnahme aus der HV-Batterie";
CM_ SG_ 687 BMS_Verbrauch_Ueberlauf "Verbrauchssignal mindest 1x übergelaufen";
CM_ SG_ 1532 KL_Autobetrieb_HL "Status, ob Klimatisierung in Autobetrieb in Klimazone hinten links";
CM_ SG_ 1532 KL_Autobetrieb_HR "Status, ob Klimatisierung in Autobetrieb in Klimazone hinten rechts";
CM_ SG_ 1532 KL_Autobetrieb_VL "Status, ob Klimatisierung in Autobetrieb in Klimazone vorne links";
CM_ SG_ 1532 KL_Autobetrieb_VR "Status, ob Klimatisierung in Autobetrieb in Klimazone vorne rechts";
CM_ SG_ 1532 KL_Zieltemperatur_HL "einzuregelnde (d.h. die interne berechnete, nicht die an der BKE eingestellte) Zieltemperatur für die Klimazone hinten links";
CM_ SG_ 1532 KL_Zieltemperatur_HR "einzuregelnde (d.h. die interne berechnete, nicht die an der BKE eingestellte) Zieltemperatur für die Klimazone hinten rechts";
CM_ SG_ 1532 KL_Zieltemperatur_VL "einzuregelnde (d.h. die interne berechnete, nicht die an der BKE eingestellte) Zieltemperatur für die Klimazone vorne links";
CM_ SG_ 1532 KL_Zieltemperatur_VR "einzuregelnde (d.h. die interne berechnete, nicht die an der BKE eingestellte) Zieltemperatur für die Klimazone vorne rechts";
CM_ BO_ 1788 "200ms";
CM_ SG_ 1788 NMH_Ladegeraet_Start_1 "Zustand Start (<--Sleep)";
CM_ SG_ 1788 NMH_Ladegeraet_Start_2 "Zustand Start (<--Prepare to Sleep)";
CM_ SG_ 1788 NMH_Ladegeraet_Normal_Mode_1 "Zustand Normal Mode (<-- Start)";
CM_ SG_ 1788 NMH_Ladegeraet_Normal_Mode_2 "Zustand Normal Mode (<-- Ready to Sleep)";
CM_ SG_ 1788 NMH_Ladegeraet_Car_WakeUp "Car WakeUp optional, wird vom AAG nicht bedient
";
CM_ SG_ 1788 NMH_Ladegeraet_Per_WakeUp "Weckursache Peripherie
";
CM_ SG_ 1788 NMH_Ladegeraet_Fkt_WakeUp "Weckursache Funktion
";
CM_ SG_ 1788 NMH_Ladegeraet_Klemme_15 "Kl.15 EIN (Nachlaufursache, SG nicht im NM-Zustand 'Ready to Sleep')
";
CM_ SG_ 1788 NMH_Ladegeraet_Diagnose "Diagnose bei Kl 15 aus (Nachlaufursache, SG nicht im NM-Zustand 'Ready to Sleep')
";
CM_ SG_ 1788 NMH_Ladegeraet_MindestAktivZeit "Mindestaktivzeit Taktiv_min (Nachlaufursache, SG nicht im NM-Zustand 'Ready to Sleep') / nSTART
";
CM_ SG_ 1788 NMH_Ladegeraet_Signalfehler "Bei der Speicherung eines CAN-Signalfehlers muss dieser mindestens einmal in der NM-Botschaft angezeigt werden.";
CM_ SG_ 1788 NMH_Ladegeraet_TimeOut_Fehler "Aktiver Timeout Fehlerspeichereintrag";
CM_ SG_ 1788 NMH_Ladegeraet_CAN_Diag_deaktiv "CAN-Diagnose deaktiv (Überspannung, Unterspannung, Hochlaufphase, ...) ";
CM_ SG_ 1788 NMH_Ladegeraet_KompSchutz "Funktionseinschränung aufgrund Komponentenschutz aktiv";
CM_ SG_ 1788 NMH_Ladegeraet_Mute_Mode "Funktionseinschränung aufgrund Mute Mode aktiv, nur VW";
CM_ SG_ 1788 NMH_Ladegeraet_Transport_Mode "Funktionseinschränung aufgrund Transport Mode aktiv";
CM_ SG_ 1788 NMH_Ladegeraet_Abschaltstufe_000 "Funktionsabschaltung wegen Abschaltschaltstufe";
CM_ SG_ 1788 NMH_Ladegeraet_Eindraht_Fehler "Erkennung Eindrahtfehler";
CM_ SG_ 1788 NMH_Ladegeraet_Lokalaktiv "Zeigt an ob Steuergerät lokal aktiv war";
CM_ SG_ 1788 NMH_Ladegeraet_Subsystemaktiv "Zeigt an ob ein Subsystem des SGs nach Klemme15 AUS und nach entsprechender MAX Aktivzeit noch aktiv war";
CM_ SG_ 1483 PTC_Wassereinlasstemp "Gemessene Wassereinlasstemperatur";
CM_ SG_ 1483 PTC_Wasserauslasstemp "Gemessene Wasserauslasstemperatur";
CM_ SG_ 1483 PTC_HV_I_ist "PTC Stromverbrauch (max. 120A)";
CM_ SG_ 1483 KL_T_Charge "Signal für Tastenbetätigung Charge-Taste (SOC Increasing)";
CM_ SG_ 1483 KBT_Defrost_aktiv "Defrostmodus im KBT aktiv";
CM_ SG_ 1483 KL_WunschStrom_HV "Von Klima gewünschter HV-Strom, der dann nach Freigabe des HV-eEM auf HV-EKK und HV-PTC aufgeteilt wird";
CM_ SG_ 1483 KL_BattKond_WaPu_DZMax "Maximal-Drehzahl der Wasserpumpe im Batteriekühlkreislauf als Vorgabe für BMS";
CM_ SG_ 1483 KL_Standklima_Status "Info, dass Standklimatisierung nicht gestartet werden konnte oder abgebrochen wurde.";
CM_ SG_ 899 CHA_Ziel_FahrPr_BMS "Anforderung Ziel-Fahrprogramm BMS (nähere Spezifikation siehe Charisma-LH PAG)";
CM_ SG_ 1518 KL_T_STH "Taster Standheizung (Wasserzusatzheizung)";
CM_ SG_ 1518 Klima_08_PAG_alt "Veraltet Bit für die Signale:
KL_Segel_Anf_deaktivieren";
CM_ SG_ 391 MO_Tankbereitschaft_Status "Meldung der Tankbereitschaft";
CM_ SG_ 391 MO_Tankklappensteuerung "Ansteuerungsanforderung der Tankklappe";
CM_ SG_ 391 MO_HVEM_MaxLeistung "Maximal zulässige Leistung, die das HVEM einzustellen hat. 
Ohne Eskalationsbit ist diese Anforderung >= der Minimal benötigten Leistung des HVEM";
CM_ SG_ 391 EV_Rekuperationsstufe "Im Kombi anzuzeigende Rekuperationsstufe";
CM_ SG_ 391 MO_Waehlpos "Wählhebelposition (im VW120/7 und MQB Omega ist der Wählhebel am HCAN mit Master Motor-SG angeschlossen)

(wenn Signal in MSG_HYB_03: Signal nur in der CAN-Welt PQ35/25 zu verwenden, da dort am ACAN die Wählhebelposition nicht abgesichert übertragen wir";
CM_ SG_ 391 HV_Bordnetz_aktiv "Signalisiert ein aktives Hochvoltbordnetz. HV-Schütze geschlossen. Im Fehlerfall wird das Bit nicht gesetzt.(Klemmende Schütze)";
CM_ SG_ 391 MO_HVEM_Eskalation "Eskalationsbit, mit diesem zusammen darf MO_HVEM_MaxLeistung < der minimal angeforderten Leistung sein und ist durch das HVEM durch Ergreifung aller Eskalationsmaßnahmen umzusetzen (Bei neg. Ladebilanz z.B. im Leerlauf nötig, um die HVBatt vor Entladung e";
CM_ SG_ 1662 LAD_02_CHK "Berechnung siehe Konzern-Lastenheft A-CAN V4.2a
Checksummenendwert = 0x00";
CM_ SG_ 1662 LAD_02_BZ "freilaufender Botschaftszähler";
CM_ SG_ 1662 LAD_Abregelung_Temperatur "Abregelung aufgrund interner Übertemperatur im Ladegerät";
CM_ SG_ 1662 LAD_Abregelung_IU_Ein_Aus "Abregelung aufgrund Strom oder Spannung am Eingang oder Ausgang";
CM_ SG_ 1662 LAD_Abregelung_BuchseTemp "Reduzierung aufgrund zu hoher Temperatur der Ladebuchse";
CM_ SG_ 1662 LAD_MaxLadLeistung_HV "Maximale Leistung Ladegerät bezogen auf die maximale Leistung Infrastruktur (Kabel, Ladestation) und Berücksichtigung des Ladegerät-Wirkungsgrades";
CM_ SG_ 1662 LAD_CP_Stromlimit "AC-Stromlimit aufgrund des CP Duty Cycles";
CM_ SG_ 1662 LAD_PRX_Stromlimit "AC-Stromlimit aufgrund der PRX Kabelkodierung";
CM_ SG_ 1662 LAD_CP_Erkennung "Status Control Pilot Überwachung (Erkennung des Control Pilot Duty-Cycles)";
CM_ SG_ 1662 LAD_Stecker_Verriegelt "Status Steckerverriegelung (Rücklesekontakt des Verrieglungsaktors)";
CM_ SG_ 1662 LAD_Stecker_Gesteckt "Status Steckererkennung";
CM_ SG_ 1662 LAD_Kuehlbedarf "Kühlbedarf des Ladegerätes";
CM_ SG_ 1662 LAD_Warnzustand "Sammelwarnung Ladegerät
0 keine Warnbedingung aktiv
1 Warnbedingung aktiv, evtl. eingeschränkte Leistungsfähigkeit";
CM_ SG_ 1662 LAD_Fehlerzustand "Sammelfehler Ladegerät - kein Laden möglich";
CM_ SG_ 1662 LAD_Fehlerstatus "aktueller Fehlerstatus des Ladegerätes
0: Komponente IO (keine HVK relevanter Fehler)
1: Eingeschränkte_Komponentenfunktion AC Laden nicht möglich
2: Eingeschränkte_Komponentenfunktion DC Laden nicht möglich
3: Eingeschr_Komponentenfunktion aufgrund H";
CM_ SG_ 1662 LAD_Warnlampe_Anf "Anforderung der gelben Hybrid-Warnlampe im Kombi (Motorsteuergerät reicht diese Info an Kombi weiter).";
CM_ SG_ 1380 LAD_01_CHK "Berechnung siehe Konzern-Lastenheft A-CAN V4.2a
Checksummenendwert = 0x00";
CM_ SG_ 1380 LAD_01_BZ "freilaufender Botschaftszähler";
CM_ SG_ 1380 LAD_IstModus "Betriebsmodus:
0: Standby: Kommunikaton aktiv
1: NetzLade-Modus (gesteuert durch EV-Lademanagement)
2: externe Steuerung (gesteuert durch Netzbetreiber)
3: vorgehalten
4: vorgehalten
5: interner Fehler Lader, angeforderter Sollmodus kann nicht einge";
CM_ SG_ 1380 LAD_AC_Istspannung "Istwert AC-Netzspannung (RMS) ";
CM_ SG_ 1380 LAD_IstSpannung_HV "Ausgangsspannung Lader";
CM_ SG_ 1380 LAD_IstStrom_HV "Ausgangsstrom Lader";
CM_ SG_ 1380 LAD_Status_Spgfreiheit "0 = Init (ohne Funktion)
1 = Ladegerät HV-Komponenten spannungsfrei (U_Zwkr < 20V)
2 = Ladegerät HV_Komponenten nicht spannungsfrei (U_Zwkr >= 20V)
3 = Fehler (z. B. Fehler in der Sensorik)";
CM_ SG_ 1380 LAD_Temperatur "Momentanwert: Temperatur Ladegerät";
CM_ SG_ 1380 LAD_Verlustleistung "Momentanwert: Verlustleistung Ladegerät";
CM_ SG_ 1385 HVEM_Abschaltstatus "Status der Reduzierungsstufen der Klimakomponenten beim Laden

0 = 100% (keine Reduzierung)
1 = 75%
2 = 50%
3 = 25%
7 = Init";
CM_ SG_ 1385 HVEM_NVLeistungEmpf "Maximaler Sollwert der aktuellen Leistung der NV-Seite des DCDC-Wandlers.";
CM_ SG_ 1385 HVEM_KlimaMaxHVStrom "Kommuniziert dem Klimasteuergerät den max. Aufnahmestrom";
CM_ SG_ 1385 HVEM_LeistunsAnf "Anforderung an NV-EM zur Erhöhung der Performance den Energieverbrauch auf der NV-Seite zu reduzieren.";
CM_ SG_ 1385 HVEM_Nachlad_Status "Status der Umsetzung der Nachladeanforderung der NV-Seite.";
CM_ SG_ 1385 HVEM_Anf_ReichweiteNV "Anforderung an NV-EM zur Erhöhung der Reichweite den Energieverbrauch auf der NV-Seite zu reduzieren.";
CM_ SG_ 1385 HVEM_HV_Anf "HV Anforderung des HV Energiemanagements an das MSG";
CM_ SG_ 1385 HVEM_Text_1 "Meldung bei einem Anzeige SOC<10% ('Achtung Batterie laden. Funktionen eingeschränkt')";
CM_ SG_ 1385 HVEM_Nachladen_Anf "Anforderung für HV Laden bei gestecktem Stecker und deaktivierter Ladeanforderung";
CM_ SG_ 1385 HVEM_FreigabeKlimatisierung "Klimatisierung freigeben";
CM_ SG_ 1482 BMS_07_CRC "Für MLB:
'Berechnung siehe Lastenheft 'Kommunikationsabsicherung für FlexRay und CAN''

Ab MQB und MLBevo:
'Berechnung siehe Lastenheft 'End-to-End Kommunikationsabsicherung''

Endwerte siehe Begleitdokument 'S-PDU Kennungsfolgen'";
CM_ SG_ 1482 BMS_Energieinhalt "aktuell nutzbarer Energieinhalt der HV-Batterie
(bezogen auf ein definiertes mittleres Belastungsprofil)";
CM_ SG_ 1482 BMS_Ladevorgang_aktiv "Signalisiert aktiven Ladevorgang, Ladegerät und DC/DC aktiv.
Signal bleibt nach Kl.15 ein aktiv, bis ESP_Stillstandsflag gelöscht.

Abhängigkeit zu BMS_Energieinhalt";
CM_ SG_ 1482 BMS_MaxEnergieinhalt "maximaler nutzbarer Energieinhalt der HV-Batterie (bezogen auf Last KBI_RWDS_Lastprofil bei SOC=100%)
Abhängig von KBI_RWDS_Lastprofil";
CM_ SG_ 1482 BMS_Ausgleichsladung_Anf "BMS wünscht eine Ausgleichsladung
Flag derzeit ungenutzt, da BalancingModus im Detail noch nicht geklärt.";
CM_ SG_ 1482 BMS_Gesamtst_Spgfreiheit "0 = Funktion nicht aktiviert
1 = HV-System spannungsfrei (U_Zwkr von BMS, LE und Ladegerät < 20V, DCLadestecker nicht gesteckt und Service Disconnect entriegelt)
2 = HV-System nicht spannungsfrei (U_Zwkr von BMS, LE und Ladegerät >= 20V, Ladestecker ges";
CM_ SG_ 1519 BMS_IstStrom "actual current of the battery / Momentanwert: Batteriestrom
Stromrichtung: ein Ladestrom wird mit positiven, ein Entladestrom mit negativen Werten angegeben";
CM_ SG_ 1519 BMS_PTC_Stufe "aktulle Stufe des PTC Zuheizers für den Batteriekühlkreislauf";
CM_ SG_ 1519 BMS_PTC_IstStrom "Ist Strom des PTC Zuheizers für den Batteriekühlkreislauf";
CM_ SG_ 1519 BMS_Status_Kuehlung "Rueckmeldung BMS Kuehlstufe";
CM_ SG_ 1519 BMS_Temp_Zelle_Min "Minimale Temperatur einer Zelle in der HVB";
CM_ SG_ 1519 BMS_Temp_Zelle_Max "Maximale Temperatur einer Zelle in der HVB";
CM_ SG_ 1519 BMS_Pumpendrehzahl "Rueckmeldung der CWA50 ueber aktuelle Pumpendrehzahl in % im Kuehlkreislauf HV-Batterie";
CM_ SG_ 1519 BMS_Status_3_2_Ventil1 "Status 3/2 Wegeventil Kuehlkreislauf HV-Batterie";
CM_ SG_ 1519 BMS_Status_3_2_Ventil2 "Status 3/2 Wegeventil Kuehlkreislauf HV-Batterie";
CM_ SG_ 1438 BMS_Temperierung_Anf "Temperierungsbedarf der HV-Batterie";
CM_ SG_ 1438 BMS_Temperatur "battery temperature / Momentanwert: Temperatur der Traktionsbatterie";
CM_ SG_ 1438 BMS_IstVorlaufTemperatur "Aktuelle Vorlauftemperatur der Batterie";
CM_ SG_ 1438 BMS_SollVolumenstrom "Soll Volumenstrom für Kühlkreislauf Batterie";
CM_ SG_ 1438 BMS_SollVorlauftemperatur "Soll_Vorlauftemperatur_Kühlmedium in °C";
CM_ SG_ 1438 BMS_IstRuecklaufTemperatur_02 "Aktuelle Ruecklauftemperatur der Batterie";
CM_ SG_ 1438 BMS_SollVorlaufTemp_Epsilon "¿Dieses Signal beschreibt die zulässige Abweichung oberhalb und unterhalb von der Sollvorlauftemperatur in Kelvin, die von der HV-Batterie akzeptiert wird. Bei einer SollVorlaufTemperatur von 30°C und einem Wert von SollVorlaufTemperaturEpsilon von 5K wer";
CM_ SG_ 1428 HVLM_HV_Anf "HV-Aktivierung Anforderung und Grund der Anforderung";
CM_ SG_ 1428 HVLM_Stecker_Status "Status der Steckererkennung unabhängig vom Lademodus (AC oder DC)";
CM_ SG_ 1428 HVLM_Restladezeit_HV_Bat_02 "Zeit, bis HV-Batterie vollständig geladen ist. Angabe in 5 Minuten Schritten. Maximum 42h 25Min";
CM_ SG_ 1428 HVLM_Lademodus_HV_Bat "Gibt den aktuell eingestellten Lademodus an.";
CM_ SG_ 1428 HVLM_Ladeart "Anzeige des ausgewählten Lademodus";
CM_ SG_ 1428 HVLM_VK_Anf "Anforderung des Konditionierungsmanagers (im Lademanager) zur Aktivierung der Vorkonditionierung Innenraum";
CM_ SG_ 1428 HVLM_Ladesystemhinweise "Anzeigen von Hinweisen zum Ladesystem.
Anzeigen, dass das Ladesystem defekt ist.";
CM_ SG_ 1428 HVLM_Langzeit_Laden "Anforderung den Ladezustand der HV-Batterie bis langen Standzeiten zu reduzieren";
CM_ SG_ 1428 HVLM_Klima_Temp "MLBevo: Gewünschte Innenraumtemperatur, auf die bei der Standklimatisierung geregelt werden soll.
MQB: Temperatur die vom Nutzer vorgewählt wurde (VW: low=15,5 °C/ high=30,0°C)";
CM_ SG_ 1428 HVLM_VK_Modus "Übermittlung des aktuellen Konditionierungs-Status für HMI, Mobile Online Dienste";
CM_ SG_ 1428 HVLM_HSH_Anf "Heckscheibenheizung anfordern";
CM_ BO_ 24 "Wegfahrsperrenbotschaft";
CM_ SG_ 24 WFS_MSG4_IMS "Wegfahrsperre";
CM_ BO_ 25 "Wegfahrsperrenbotschaft";
CM_ SG_ 25 WFS_IMS_MSG4 "Wegfahrsperre (Vorhalt Hybrid)";
CM_ BO_ 1603 "Einheitenbotschaft";
CM_ SG_ 1603 KBI_Einheit_Verbrauch_elektr "Einheit elektrischer Verbrauch";
CM_ SG_ 1603 KBI_Einheit_Datum "Anzeigevariante des Datums";
CM_ SG_ 1603 KBI_Einheit_Streckenanz "Einheit der Streckenanzeige";
CM_ SG_ 1603 KBI_Einheit_Temp "Einheit der Temperatur";
CM_ SG_ 1603 KBI_Einheit_Uhrzeit "Anzeigevariante der Uhrzeit
";
CM_ SG_ 1603 KBI_Einheit_Sprache "Einheit Sprache";
CM_ SG_ 1603 KBI_Einheit_Volumen "Einheit des Volumens";
CM_ SG_ 1603 KBI_Einheit_Verbrauch "Einheit der Verbrauchs";
CM_ SG_ 1603 KBI_MFA_v_Einheit_02 "Einheit der Geschwindigkeit, die vom Fahrer im Car-Menü gewählt wurde. Veränderliche Grösse, im Gegensatz zur Einheit des Tachokranzes.
Redundant in der Einheiten_01 Botschaft definiert, um Konsistenz zur BAP-Festlegung zu haben.";
CM_ SG_ 1603 KBI_Einheit_Druck "Einheit des Druckes";
CM_ BO_ 267 "Botschaft vom Lenkstockschalter, enthält Information zur Bedienung der GRA und ACC, sowie MFL-Tasten zum Getriebe für TipTronic.
Unterschied zu Ursprungs-Botschaft: Signalpos. 28+29 (LS_Tip_Stufe_2, LS_GRA_ACC_2stufig)";
CM_ SG_ 267 MFL_Tip_Up "Tiptronic Tasten vom MFL für Getriebe
    0x0 = kein Tip_Up
    0x1 = Tip_Up";
CM_ SG_ 267 MFL_Tip_Down "Tiptronic Tasten vom MFL für Getriebe
    0x0 = kein Tip_Down
    0x1 = Tip_Down";
CM_ SG_ 267 LS_Verstellung_Zeitluecke "Verstellung der Zeitlücke für ACC

0x0 = Taste nicht betaetigt
0x1 = Dist -1
0x2 = Dist +1
0x3 = nicht belegt

DIST -1 = Zeitluecke um 1 Stufe kleiner
DIST +1 = Zeitluecke um 1 Stufe groeßer";
CM_ SG_ 267 LS_Typ_Hauptschalter "Typ Hauptschalter";
CM_ SG_ 267 LS_Tiptronic_Fehler "Tiptronic Fehler";
CM_ SG_ 267 LS_Tip_Wiederaufnahme "ACC : Tippschalter Wiederaufnahme";
CM_ SG_ 267 LS_Tip_Setzen "ACC : Tippschalter Set";
CM_ SG_ 267 LS_Tip_Runter "GRA : Tip Down 
ACC : Tip Down";
CM_ SG_ 267 LS_Tip_Hoch "GRA : Tip Up 
ACC : Tip Up";
CM_ SG_ 267 LS_Limiter "Limiter setzen";
CM_ SG_ 267 LS_Hauptschalter "Tempomat aktiviert/deaktiviert";
CM_ SG_ 267 LS_Fehler "0 = in Ordnung
1 = Fehler Bedienteil";
CM_ SG_ 267 LS_Abbrechen "GRA : aus mit speichern
ACC : Soft aus";
CM_ SG_ 267 LS_01_CHK "Bildung der Checksumme
Checksumme = Byte2 XOR Byte 3 ... XOR Byte n  XOR CHK-Endwert
Wobei 'CHK-Endwert' abhängig ist vom CAN-ID: CHK-Endwert = MSB XOR LSB
MSB: High-Byte des Identifiers der CAN-Botschaft LSB: Low-Byte des Identifiers der CAN-Botschaft";
CM_ SG_ 267 LS_01_BZ "4bit Botschaftszähler, wird in jeder Sendebotschaft inkrementiert";
CM_ SG_ 267 MFL_M_Taste "Gilt nicht für PAG Panamera.
Taster für Umschaltung Automatik/manuelles Schalten (Tiptronic)

";
CM_ SG_ 267 LS_Tip_Stufe_2 "Signal zeigt an, dass der zweistufige GRA/ACC-Hebel in der 2. Tip-Stufe betätigt wird. Das Signal wird nur gleichzeitig mit dem Signal LS_Tip_Hoch oder LS_Tip_Runter gesetzt, wobei die Bits LS_Tip_Hoch bzw. LS_Tip_Runter die Richtung der Hebelbetätigung a";
CM_ SG_ 267 LS_GRA_ACC_2stufig "Verbau-Information zum zweistufigen GRA/ACC-Hebel; 
Übergangslösung für MLB1, soll ab MQB durch ein Signal ersetzt werden, dass weitere Bedienteilvarianten (z.B. 4-Positions-Hebel) kennzeichnen kann.";
CM_ BO_ 260 "EPB-Botschaft (Status, Beschl., Pedalweg, etc.) wie Audi B8";
CM_ SG_ 260 EPB_Konsistenz_ACC "Signal wird im Panamera nicht unterstützt. Es wird konstant '1' (Fehler erkannt) gesendet.
Signalanforderung aus ColNF.";
CM_ SG_ 260 EPB_Anfahrwunsch_erkannt "Anfahrwunsch erkannt
Aktuell kein Empfänger. Vorhalt für E2.";
CM_ SG_ 260 EPB_Pedalweg_Kuppl "Signal entspricht Tastverhältnis des PWM. Gesamtweg Kupplungspedal 10% bis 90%, damit zu erwartende Werte 25 bis 225. 25 bei Kupplungspedal nicht getreten, 225 bei Kupplungspedal voll durchgetreten.
2% Toleranz wird im Wertebereich ermöglicht (8%-92%).
";
CM_ SG_ 260 EPB_Fehlerstatus "EPB Fehlerstatus";
CM_ SG_ 260 EPB_Schalterposition "Spiegelt die Schalterstellung wieder.

";
CM_ SG_ 260 EPB_QBit_Schalterpos "QBit für Signal 'EPB_Schalterposition'";
CM_ SG_ 260 EPB_Spannkraft "Erzeugte Spannkraft. Bezieht sich auf die Aktuatoren.

0x1F = Fehler
0x1E = Init";
CM_ SG_ 260 EPB_Status "Gibt den Zustand der EPB-Aktuatoren an.";
CM_ SG_ 260 EPB_KD_Fehler "Kundedienstfehler";
CM_ SG_ 260 EPB_01_CHK "Bildung der Checksumme
Checksumme = Byte2 XOR Byte 3 ... XOR Byte n  XOR CHK-Endwert
Wobei 'CHK-Endwert' abhängig ist vom CAN-ID: CHK-Endwert = MSB XOR LSB
MSB: High-Byte des Identifiers der CAN-Botschaft LSB: Low-Byte des Identifiers der CAN-Botschaft";
CM_ SG_ 260 EPB_01_BZ "Überlaufender Botschaftszähler zur Erkennung von fehlenden oder alten Botschaften.";
CM_ SG_ 260 EPB_QBit_Laengsbeschleunigung "Mitteilung z.Zt. für ACC, um unter bestimmten Umständen mitzuteilen, daß Längsbeschleunigung temporär ungültig ist. Bsp.Selbsttest Längsbeschleunigungssensor.";
CM_ SG_ 260 EPB_QBit_Pedalweg_Kuppl "QBit für Signal 'EPB_Pedalweg_Kuppl'";
CM_ SG_ 260 EPB_BCM2_Motor_Wakeup "EPB setzt dieses Bit, wenn EPB ein Nachwecken des ACAN fordert.
Die Wakeup-Ursache des CAR-Wakeup wird im NMH von den SG nicht ausgewertet,
weswegen die Car-Wakeup-Information in einer konventionellen Applikationsbotschaft zum BCM2 gesendet werden.";
CM_ SG_ 260 EPB_Freig_Verzoeg_Anf "Freigabe Verzögerungsanforderung";
CM_ SG_ 260 EPB_Verzoeg_Anf "Steuerungsanforderung an andere Systeme (z.B. ESP), um während der Fahrt, durch den Handbremsschalter ausgelöst, zu bremsen (ECD-Funktion)";
CM_ SG_ 260 EPB_Laengsbeschleunigung "Längsbeschleunigungssignal.
Achtung! Misst auch die Erdbeschleunigung (steht am Hang Wert != 0)

Entspricht bei kleinen Winkeln dem Neigungswinkelsignal (<30%).

0x00 = Init
0xFF = Fehler";
CM_ BO_ 64 "Airbagbotschaft (CrashInt, Front-, Heck-, Rollovercrash, Gurte)";
CM_ SG_ 64 AB_Deaktivierung_HV "Deaktivierung der HV-Teilnehmer im Hybrid nach Crash
(Signal wird im Panamera nicht bedient!)";
CM_ SG_ 64 AB_RGS_Anst "PreCrash-Ansteuerung reversibler Gurtstraffer (Aktivierung und Kraftniveau)
Gilt nicht fuer PAG Panamera.";
CM_ SG_ 64 AB_Texte_AKS "Textanzeige für pyrotechnische Auslösung der aktiven Kopfstütze (AKS).
Gilt nicht für PAG Panamera.";
CM_ SG_ 64 Airbag_01_CHK "Bildung der Checksumme
Checksumme = Byte2 XOR Byte 3 ... XOR Byte n  XOR CHK-Endwert
Wobei 'CHK-Endwert' abhängig ist vom CAN-ID: CHK-Endwert = MSB XOR LSB
MSB: High-Byte des Identifiers der CAN-Botschaft LSB: Low-Byte des Identifiers der CAN-Botschaft";
CM_ SG_ 64 Airbag_01_BZ "Botschaftszähler";
CM_ SG_ 64 AB_Front_Crash "Bit wird bei Überschreitung der Gurtstraffer-, US- und RdW-Schwelle gesetzt";
CM_ SG_ 64 AB_Heck_Crash "Heck-Crash";
CM_ SG_ 64 AB_SF_Crash "Z.Zt. nur in Verbindung mit Crash-Intensität >= 100b (Kraftstoffpumpenabschaltung) verwendet.";
CM_ SG_ 64 AB_SB_Crash "Z.Zt. nur in Verbindung mit Crash-Intensität >= 100b (Kraftstoffpumpenabschaltung) verwendet.";
CM_ SG_ 64 AB_Rollover_Crash "Rollover Crash";
CM_ SG_ 64 AB_Crash_Int "Crash-Intensität";
CM_ SG_ 64 AB_Lampe "Sicherheitswarnlampe im Kombi wird vom Airbag-SG angesteuert; Zustand der Lampe wird auf dem CAN-Bus ausgegeben (auch Blinkinformation).";
CM_ SG_ 64 AB_Deaktiviert "Airbag oder Gurtstraffer wurden per Anpassung deaktiviert: Aktualisierung erst nach Selbsttest
Bei Porsche konstant '0'";
CM_ SG_ 64 AB_VB_deaktiviert "Als Option vorgehalten, Beifahrerairbag wurden per Schlüsselschalter oder Insassenerkennung deaktiviert
Auswertung bei Porsche:
0x0: Airbag BF aktiv, PAO-Leuchte aus
0x1: Airbag BF deaktiviert, PAO-Leuchte ein";
CM_ SG_ 64 AB_Systemfehler "Ggf. wird Warnlampe dauernd eingeschaltet.";
CM_ SG_ 64 AB_Diagnose "Airbag in Diagnose";
CM_ SG_ 64 AB_Anzeige_Fussg "Anzeige für den Kunden, ob Reversierung der Motorhaube erfolgt ist";
CM_ SG_ 64 AB_PAO_Leuchte_Anf "Anforderung an die PAO-Leuchte in der Dachkonsole an/aus";
CM_ SG_ 64 AB_Stellgliedtest "Information, ob Airbag im Stellgliedtest ist, um eine Notrufauflösung beim Stellgliedtest zu verhindern";
CM_ SG_ 64 AB_Erh_Auf_VB "Der Fahrer soll bei einem Statuswechsel des Beifahrerairbags (ausgelöst durch die Beifahrerinsassenerk. oder den Schlüsselschloßschalter) aufmerksam gemacht werden durch eine Anz. im Kombi. 
Wird bei Porsche nicht genutzt.Es wird konstant 0x3 gesendet.";
CM_ SG_ 64 AB_Gurtwarn_VF "Fahrer hat Gurt nicht gesteckt, Anzeige im Kombi";
CM_ SG_ 64 AB_Gurtwarn_VB "Beifahrer hat Gurt nicht gesteckt, Anzeige im Kombi";
CM_ SG_ 64 AB_KD_Fehler "Status Kundendienstfehlerspeichereinträge
";
CM_ BO_ 1312 "Airbagbotschaft (Belegungserkennung)";
CM_ SG_ 1312 AB_Sitzpos_Sens_BF "Ausgabe Sitzposition Beifahrer";
CM_ SG_ 1312 AB_Sitzpos_Sens_FA "Ausgabe Sitzposition Fahrer";
CM_ SG_ 1312 AB_Gurtschloss_Reihe3_MI "Gurtschlossstatus 3. Reihe Mitte";
CM_ SG_ 1312 AB_Gurtschloss_Reihe3_FA "Gurtschlossstatus 3. Reihe Fahrerseite";
CM_ SG_ 1312 AB_Gurtschloss_Reihe3_BF "Gurtschlossstatus 3. Reihe Beifahrerseite";
CM_ SG_ 1312 AB_Gurtschloss_Reihe2_BF "Gurtschlossstatus 2. Reihe Beifahrerseite";
CM_ SG_ 1312 AB_Gurtschloss_Reihe2_MI "Gurtschlossstatus 2. Reihe Mitte";
CM_ SG_ 1312 AB_Gurtschloss_Reihe2_FA "Gurtschlossstatus 2. Reihe Fahrerseite";
CM_ SG_ 1312 AB_Gurtschloss_BF "Gurtschlossstatus Beifahrerseite";
CM_ SG_ 1312 AB_Gurtschloss_FA "Gurtschlosstatatus Fahrerseite";
CM_ SG_ 1312 AB_Belegung_VB "AB Belegung VB
Wird bei Porsche nicht genutzt.Es wird konstant 0x0 gesendet.";
CM_ BO_ 777 "Batterie Energie Management";
CM_ SG_ 777 BEM_Segel_Info "0: keine Anforderung 
(Segeln ist ohne Einschänkung erlaubt)
1: Mindestdrehzahl 1 
(Segeln ist mit Einschänkung erlaubt)
2: Mindestdrehzahl 2
(Segeln ist mit Einschänkung erlaubt)
3: Segelveto
(Segeln ist nicht  erlaubt)";
CM_ SG_ 777 BEM_01_CHK "Bildung der CHK:

XOR Byte2 XOR Byte 3 ... XOR Byte n  XOR CHK-Endwert  = CHK

Ab B8 ist CHK-Endwert abhängig vom CAN-ID: CHK-Endwert = MSB XOR LSB
MSB: High-Byte des Identifiers der CAN-Botschaft
LSB: Low-Byte des Identifiers der CAN-Botschaft";
CM_ SG_ 777 BEM_P_Generator "Es gilt: Signalspec BEM_P_Generator v1.0

Mechanische Generatorleistung dient dem Motorsteuergerät zur Berechnung der Motorlast; Genauigkeit ca. +/- (500W + 20% vom Messwert)";
CM_ SG_ 777 BEM_n_LLA "Es gilt: Signalspec BEM_n_LLA v1.0

Anforderung einer Leerlaufdrehzahlanhebung in drei Stufen. Die Höhe der jeweiligen LL-Drehzahlstufe ist im Motorsteuergerät appliziert.";
CM_ SG_ 777 BEM_01_Abschaltstufen "Signal inhaltlich identisch mit BEM_02_Abschaltstufen. Namentliche Umbenennung wegen Standard-SW im Gateway-BEM im B8 (Handling gleicher Signalnamen im Source-Code).";
CM_ SG_ 777 BEM_Anf_KL "Es gilt: Signalspec BEM_Anf_KL v1.1

Das BEM fordert über das MSG den Kühlerlüfter-Betrieb an; hierzu wird ein minimaler Leistungswert im MSG appliziert. 
Szenario: bei erkannter abgetrennten Batterie soll durch Ansteuerung des Kühlerlüfters das Energi";
CM_ SG_ 777 BEM_StartStopp_Info "Start/Stop-Info, Veto";
CM_ BO_ 1714 "Zentrale GW-Botschaft für Datum, Uhrzeit, etc.";
CM_ SG_ 1714 UH_Jahr "Jahr
Hinweis: keine Überwachung auf CAN-Signalfehler notwendig";
CM_ SG_ 1714 UH_Monat "Monat; Wertebereich 1-12, alle anderen Werte ungültig
Hinweis: Es ist ein CAN-Signalfehler 'Kombi' (nicht Gateway) einzutragen.";
CM_ SG_ 1714 UH_Tag "Monat; Wertebereich 1-31, alle anderen Werte ungültig
Hinweis: Es ist ein CAN-Signalfehler 'Kombi' (nicht Gateway) einzutragen.";
CM_ SG_ 1714 UH_Stunde "Stunde; Wertebereich 0-23, alle anderen Werte ungültig
Hinweis: Es ist ein CAN-Signalfehler 'Kombi' (nicht Gateway) einzutragen.";
CM_ SG_ 1714 UH_Minute "Minute; Wertebereich 0-59, alle anderen Werte ungültig
Hinweis: Es ist ein CAN-Signalfehler 'Kombi' (nicht Gateway) einzutragen.";
CM_ SG_ 1714 Kombi_02_alt "Veraltet-Bit für die Signale: KBI_Kilometerstand
Hinweis: bei gesetztem Bit ist ein CAN-Timeoutfehler 'Kombi' einzutragen.";
CM_ SG_ 1714 UH_Sekunde "Sekunde; Wertebereich 0-59, alle anderen Werte ungültig
Hinweis: Es ist ein CAN-Signalfehler 'Kombi' (nicht Gateway) einzutragen.";
CM_ SG_ 1714 DGN_Verlernzaehler "Binär, wrap around";
CM_ SG_ 1714 KBI_Kilometerstand "Fehler wird ausgegeben, falls Kilometerstand nicht restaurierbar
Hinweis. Bei Fehlerwert muss ein CAN-Signalfehler 'Kombi' eingetragen werden.";
CM_ SG_ 1714 Uhrzeit_01_alt "Veraltet-Bit wird vom GW nach einem Klemme 30-Reset gesetzt.
Über Uhrzeit_01-Botschaft vom Kombi wird im GW die Zeit neu gesetzt und das Veraltet-Bit zurückgenommen.
Hinweis: bei gesetztem Bit ist ein CAN-Timeoutfehler 'Kombi' einzutragen.
";
CM_ BO_ 1313 "Standheizung";
CM_ SG_ 1313 STH_Funk_ein "0x1 = Funkbefehl zum Einschalten erhalten";
CM_ SG_ 1313 STH_Funk_aus "0x1 = Funkbefehl zum Ausschalten erhalten";
CM_ SG_ 1313 STH_Zusatzheizung "Zusatzheizung";
CM_ SG_ 1313 STH_LED "Funktionslampe";
CM_ SG_ 1313 STH_Geblaese "0=kein Befehl an die Klimanlage; 1 = Befehl an die an Klimaanlage: Gebläse ein";
CM_ SG_ 1313 STH_EKP_Anst "STH sendet die Anforderung zur Ansteuerung der EKP an den Motor, um Kraftstoffbehälter der STH zu befüllen.";
CM_ SG_ 1313 STH_Ventiloeffnungszeit "Die Standheizung sendet an den Motor die Information darüber wie lange das Magnetventil die Wasserkreisläufe von 'klein' aus 'gross' geschaltet hat. ";
CM_ SG_ 1313 STH_Waermeeintrag "Signal enthält die Brenndauer in 1min-Schritten, über welche die Standheizung gelaufen ist";
CM_ SG_ 1313 STH_KVS "Kraftstoffverbrauch";
CM_ SG_ 1313 STH_Fehlerstatus "0 = kein Fehler;
1 = Batterie Low;
2 = Fuel Low;
3 = Hardware defekt;
4 = Heizgerät verriegelt:
5...7 = nicht definiert";
CM_ SG_ 1313 STH_Heizleistung "Heizleistung in %";
CM_ SG_ 1313 STH_Wassertemp "0xFE = Init
0xFF  = Fehler";
CM_ SG_ 1313 STH_Motorvorwaermung "Info an der Motor, dass der Aufheizvorgang mit Motorvorwärmung erfolgt ist

0x0 = keine Motorvorwärmung erfolgt
0x1 = Aufheizung mit Motorvorwärmung erfolgt";
CM_ SG_ 1313 STH_war_aktiv "Bit beeinhaltet die Info, dass die Standheizung während der letzten halbe Stunde aktiv war.

0x0 = war inaktiv
0x1 = Standheizung war letzte halbe Stunde aktiv";
CM_ SG_ 1313 STH_KVS_Ueberlauf "1 = Kraftstoffverbrauchssignal, mindestens ein Überlauf hat stattgefunden";
CM_ SG_ 1313 STH_Start_folgt "Thema Start/Stop: Im Stop-Modus muß das KBT einen Wiederstart anfordern, da ein STH-Start notwendig ist.";
CM_ BO_ 134 "Lenkwinkelsensor-Botschaft";
CM_ SG_ 134 LWI_01_CHK "Bildung der Checksumme
Checksumme = Byte2 XOR Byte 3 ... XOR Byte n  XOR CHK-Endwert
Wobei 'CHK-Endwert' abhängig ist vom CAN-ID: CHK-Endwert = MSB XOR LSB
MSB: High-Byte des Identifiers der CAN-Botschaft LSB: Low-Byte des Identifiers der CAN-Botschaft";
CM_ SG_ 134 LWI_Sensorstatus "0x0 = iO
0x1 = nicht kalibriert";
CM_ SG_ 134 LWI_QBit_Sub_Daten "0x0 = LWS-Subinfo 'real' (Lenkradwinkelinformation ADS-tauglich) 

0x1 = LWS-Subinfo 'simuliert' (Lenkradwinkelinformation nicht ADS-tauglich )

Im B8 gilt die Signalspezifikation: LAH 8K0953B";
CM_ SG_ 134 LWI_QBit_Lenkradwinkel "Ab B8 wird es möglich sein ungenaue Werte des Lenkradwinkels zu detektieren, und dem Empfänger mitzuteilen. Das QBit wird auch bei nicht abgeglichenem Lenkradwinkelsensor gesetzt

0x0 = gültiger Wert
0x1 = ausserhalb der Spezifikation";
CM_ SG_ 134 LWI_Lenkradwinkel "Wertebereich = +/- 800 Grad
Auflösung = 0,1 Grad
ACHTUNG: spezifizierte Interne Auflösung des Sensors beträgt aber nur Schrittweite 0,5 Grad!";
CM_ SG_ 134 LWI_VZ_Lenkradwinkel "Vorzeichen Lenkradwinkel gemäss DIN70000; 
Nullstellung = +0";
CM_ SG_ 134 LWI_VZ_Lenkradw_Geschw "Vorzeichen Lenkradwinkelgeschwindigkeit gemäss DIN70000; 

0x0 = positiv (links von der Nullstellung)
0x1 = negativ";
CM_ SG_ 134 LWI_Lenkradw_Geschw "Wertebereich = +/- 2500 Grad/s
Auflösung = 5 Grad/s

0x1FF = Fehler
0x1FE = Init

Im B8 gilt die Signalspezifikation: LAH 8K0953B ";
CM_ SG_ 134 LWI_Sub_Daten "Verschlüsseltes Datenpaket vom Sub-Rechner des LWS, Verwendung nur durch SCU und ESP_ADS
Verwendung gemäß 'Sicherheitsanforderungen an Empfängersteuergeräte'

Im B8 gilt die Signalspezifikation: LAH 8K0953B";
CM_ SG_ 134 LWI_01_CRC "CRC8 nach Polynom C2";
CM_ SG_ 1633 AAG_BZ "4bit-Botschaftszaehler, wird in jeder Sendebotschaft inkrementiert
";
CM_ SG_ 1633 AAG_Bremsl_durch_ECD "Bremslicht durch ECD aktiv";
CM_ SG_ 1633 AAG_Anhaenger_abgesteckt "Anhaenger wurde bei Kl. 15 aus abgesteckt";
CM_ SG_ 1633 AAG_NSL_aktiv "Anhaenger Nebelschlusslicht aktiv";
CM_ SG_ 1633 AAG_Anhaenger_erkannt "Erkennung Anhaenger";
CM_ SG_ 1633 AAG_Blinker_H_aktiv "Anhaenger Blinker aktiv";
CM_ SG_ 1633 AAG_Blinker_HL_def "Anhaenger Blinker links defekt";
CM_ SG_ 1633 AAG_Blinker_HR_def "Anhaenger Blinker rechts defekt";
CM_ SG_ 1633 AAG_Bremslicht_H_def "Anhaenger Bremslicht defekt";
CM_ SG_ 1633 AAG_Schlusslicht_HL_def "Anhaenger Schlußlicht links defekt";
CM_ SG_ 1633 AAG_Schlusslicht_HR_def "Anhaenger Schlußlicht rechts defekt";
CM_ SG_ 1633 AAG_KD_Fehler "Status Kundendienstfehlerspeichereinträge";
CM_ SG_ 1633 AAG_AVS_Fehler "Fehler AVS";
CM_ SG_ 1633 AAG_AVS_Stati "Status AVS (bei abnehmbarer oder mech.schwenkbarer Anhängerkupplung ist der Status immer 0)";
CM_ BO_ 780 "ACC-Botschaft";
CM_ SG_ 780 ACC_Wunschgeschw_erreicht "Signal for Bentley BY83x: ACC_set_speed_achieved

Mit diesem Signal wird im Kombi eine Anzeige angesteuert, wenn das Fahrzeug die gesetzte Wunschgeschwindigkeit erreicht hat.

This signal illuminates the set speed icon a different colour  in the Kombi";
CM_ SG_ 780 ACC_02_CHK "Bildung der Checksumme
Checksumme = Byte2 XOR Byte 3 ... XOR Byte n  XOR CHK-Endwert
Wobei 'CHK-Endwert' abhängig ist vom CAN-ID: CHK-Endwert = MSB XOR LSB
MSB: High-Byte des Identifiers der CAN-Botschaft LSB: Low-Byte des Identifiers der CAN-Botschaft";
CM_ SG_ 780 ACC_Wunschgeschw "Zur Anzeige der Wunschgeschwindigkeit im Kombiinstrument

0x3FE = keine Anzeige
0x3FF = nicht definiert";
CM_ SG_ 780 ACC_Status_Prim_Anz "Ansteuerung einer primären Statusanzeige für ACC/GRA in verschiedenen Farben

0x0 = Symbol nicht beleuchtet
0x1 = Farbe 1 (typisch 'grün')
0x2 = Farbe 2 (typisch 'rot')
0x3 = Farbe 3 (typisch 'gelb')";
CM_ SG_ 780 ACC_Abstandsindex "Für die optionale Anzeige einer einheitenlosen Abstandsreserve oder einer gemessenen Zeitlücke in der Zusatzanzeige";
CM_ SG_ 780 ACC_Akustik "Im Audi-ACC-Projekt:

Ansteuerung der zugehörigen Gongvariante im Kombiinstrument, solange die entsprechende Bitkombination gesetzt ist.

0x0 = keine Gongansteuerung
0x1 = Gong 1 laut
0x2 = Gong 2 laut
0x3 = Gong 1 mittel
0x4 = Gong 2 mittel
0x5 ";
CM_ SG_ 780 ACC_Gesetzte_Zeitluecke "Nur in ADR/ACC-Fahrzeugen: ACC Zusatzanzeige: 0 = aus / ungleich 0 = ein; angezeigte ADR-Zeitlücke wird auf 3 Bits begrenzt

0x0 = keine Anzeige
0x1 = Zeitlücke 1
...
0x7 = Zeitlücke 7
";
CM_ SG_ 780 ACC_Optischer_Fahrerhinweis "Fahrerübernahmeaufforderung; z.B. bei Erreichen der Systemgrenzen oder beim Auftreten von Fehlern in kritischen Situationen (VW).

0x0 = optischer Fahrerhinweis AUS
0x1 = optischer Fahrerhinweis EIN
";
CM_ SG_ 780 ACC_Typ_Tachokranz "Abhängig von der ACC-Codierung ¿Land¿ ist der Bereich der einstellbaren Wunschgeschwindigkeit und damit die Länge des schwach beleuchteten Tachokranzes begrenzt. Das Bit steuert im Kombi die Ausleuchtung des Tachokranzes an.
Der auszuleuchtende Bereich i";
CM_ SG_ 780 ACC_Anzeige_Zeitluecke "Anforderung zur Umschaltung zwischen dem Anzeigemodus 'Keine Änderung Zeitlücke' und 'Änderung Zeitlücke' (z.B. Pfeildarstellung in Zusatzanzeige)

0x0 = Anzeige Zeitlücke nicht angefordert
0x1 = Anzeige Zeitlücke angefordert
";
CM_ SG_ 780 ACC_Tachokranz "Für zusätzliche Status- und Einstellbereichsanzeige im Tacho. (z.B. Tachokranz)

0x0 = Tachokranz nicht beleuchtet
0x1 = Tachokranz beleuchtet
";
CM_ SG_ 780 ACC_Display_Prio "Zur situationsabhängigen Prioritätensteuerung von ACC Anzeigen im nicht permanenten Anzeigebereich. Im Kombiinstrument ist jeder Prioritätsstufe eine adäquate Prio-Definition zugeordnet.

0x0 = höchste Priorität
0x1 = mittlere Priorität
0x2 = geringe ";
CM_ SG_ 780 ACC_Relevantes_Objekt "Ansteuerung einer primären Anzeige 'Relevantes Objekt' für ACC in verschiedenen Farben.
";
CM_ SG_ 780 ACC_Texte_Primaeranz "Textdefinitionen im DBC-File!";
CM_ SG_ 780 ACC_Status_Anzeige "Status nur zur Defintion von Anzeige im Kombi. Hinweis: Wird für die spez. VW-Anzeige (überlappende Anzeigebereiche) verwendet. Vom AUDI-ACC im Rahmen der Modulstrategie zu bedienen.

0x0 = ACC/GRA Hauptschalter aus
0x1 = ACC in Init (nicht bei GRA)
0";
CM_ BO_ 1743 "Elektrischer Motor";
CM_ SG_ 1743 NMH_EM_keine_HV_Entl "HV-Entladung nicht möglich (NM-Nachlaufursache, nicht 'Ready To Sleep')";
CM_ SG_ 1743 NMH_EM_Start_1 "Transition in NMH-Statemachine: 'Bus-Sleep' ==> 'Start'
Das Bit wird von der Standard-SW bedient.";
CM_ SG_ 1743 NMH_EM_Start_2 "Transition in NMH-Statemachine: 'Prepare To Sleep' ==> 'Start'
Das Bit wird von der Standard-SW bedient.";
CM_ SG_ 1743 NMH_EM_Normal_Mode_1 "Transition in NMH-Statemachine: 'Start' ==> 'Normal Mode'
Das Bit wird von der Standard-SW bedient.";
CM_ SG_ 1743 NMH_EM_Normal_Mode_2 "Transition in NMH-Statemachine: 'Ready To Sleep' ==> 'Normal'
Das Bit wird von der Standard-SW bedient.";
CM_ SG_ 1743 NMH_EM_Car_WakeUp "Das Bit wird vom SG nicht bedient. Die Car Wakeup-Funktionalität ist im SG nicht umgesetzt.
";
CM_ SG_ 1743 NMH_EM_Per_WakeUp "Peripherie-Wakeup (Peripherie inkl. CAN hat geweckt):
1 = CAN

";
CM_ SG_ 1743 NMH_EM_Fkt_WakeUp "Funktions-Wakeup (Softwarefunktion hat geweckt):
0x0 Peripherie-Wakeup


";
CM_ SG_ 1743 NMH_EM_Klemme_15 "NM-Nachlaufursache: Das SG sendet noch NM-high Botschaften (befindet sich nicht im Zustand 'Ready To Sleep') aufgrund einer eingeschalteten Kl.15. In diesem Fall wird das Bit vom SG gesetzt.";
CM_ SG_ 1743 NMH_EM_Diagnose "NM-Nachlaufursache: Das SG sendet noch NM-high Botschaften (befindet sich nicht im Zustand 'Ready To Sleep') bei Kl.15 AUS und aktiver Diagnosesession. In diesem Fall wird das Bit vom SG gesetzt.";
CM_ SG_ 1743 NMH_EM_MindestAktivZeit "NM-Nachlaufursache: Das SG sendet noch NM-high Botschaften (befindet sich nicht im Zustand 'Ready To Sleep') aufgrund der Mindestaktivzeit von 4s. In diesem Fall wird das Bit vom SG gesetzt.";
CM_ SG_ 1743 NMH_EM_NL_Datem_EEPROM "EEPROM Datenspeicherung (lokaler / SG interner Nachlauf vor Wakeup)";
CM_ SG_ 1743 NMH_EM_Signalfehler "Bei der Speicherung eines CAN-Signalfehlers muss dieser mindestens einmal in der NM-Botschaft angezeigt werden.";
CM_ SG_ 1743 NMH_EM_TimeOut_Fehler "Das SG hat einen aktiven Timeout-Fehler zu einem anderen SG erkannt und setzt dieses Bit. Der FSP-Eintrag ist aktiv. Sobald wieder Botschaften des anderen Teilnehmers empfangen werden (FSP-Eintrag passiv), wird das Bit zurückgesetzt.";
CM_ SG_ 1743 NMH_EM_CAN_Diag_deaktiv "Das Bit wird vom SG in folgenden Fällen gesetzt (CAN-Diagnose ist deaktiv):
- Hochlauf des Steuergeräts nach CAN-Wakeup (t_diag_start ist noch nicht abgelaufen)
- Retriggerung von t_diag_start bei Kl.15 EIN
- Unterspannung (U < 9V)
- Überspannung (U >";
CM_ SG_ 1743 NMH_EM_KompSchutz "Das Bit wird vom SG immer mit 0 gesendet";
CM_ SG_ 1743 NMH_EM_Mute_Mode "Das Bit wird vom SG wie folgt bedient: wenn über den UDS-Service 'Communication Control' ein Abschalten der Applikationsbotschaften gefordert wird und gleichzeitig noch NWM-Botschaften gesendet werden dürfen, dann wird das Bit gesetzt
";
CM_ SG_ 1743 NMH_EM_Transport_Mode "Funktionseinschränkung aufgrund Transportmodus aktiv:
Das Bit wird vom SG gesetzt, wenn das Signal 'BEM_02_Abschaltstufen' in der Botschaft BEM_02 den Wert 4 
(= Transportmodus) annimmt. Die Ambientebeleuchtung wird vom SG abgeschaltet bzw. nicht einges";
CM_ SG_ 1743 NMH_EM_Abschaltstufe_aktiv "Funktionseinschränkung aufgrund Abschaltstufe aktiv:
Das Bit wird vom SG gesetzt, wenn das Signal 'BEM_02_Abschaltstufen' in der Botschaft BEM_02 den Wert 2 (= Stufe 2), den Wert 3 (= Stufe 3) oder den Wert 7 (= Ruhestrommessmodus) annimmt. Die Ambienteb";
CM_ SG_ 1743 NMH_EM_Busfehler "Das Bit wird vom SG gesetzt, wenn der ERROR-Pin des CAN-Transceivers dem µController einen Fehler signalisiert.";
CM_ SG_ 1743 NMH_EM_Lokalaktiv "Zeigt an ob Steuergerät lokal aktiv war";
CM_ SG_ 1743 NMH_EM_Subsystemaktiv "Zeigt an ob ein Subsystem des SGs nach Klemme15 AUS und nach entsprechender MAX Aktivzeit noch aktiv war";
CM_ BO_ 786 "Triebstrangkoordinator (TSK) Botschaft";
CM_ SG_ 786 TSK_03_CHK "Berechnung siehe Lastenheft 'Kommunikationsabsicherung für FlexRay und CAN'
Endwerte siehe 'Kommunikationsabsicherung für FlexRay und CAN / Anhang C: Tabelle S-PDU Kennungen'";
CM_ SG_ 786 TSK_03_BZ "Botschaftszähler";
CM_ SG_ 786 FAS_Wunschgeschw "Zur Anzeige der Wunschgeschwindigkeit im Kombiinstrument.";
CM_ SG_ 786 FAS_Texte_Primaeranz "0x43-7F = tbd.";
CM_ SG_ 786 FAS_Status_Prim_Anz "Ansteuerung einer primären Statusanzeige für ACC/GRA in verschiedenen Farben";
CM_ SG_ 786 FAS_Status_Anzeige "Analog zum Status nur zur Defintion von Anzeige im Kombi. Hinweis: Wird für die spez. VW-Anzeige (überlappende Anzeigebereiche) verwendet. Vom AUDI-ACC im Rahmen der Modulstrategie zu bedienen.";
CM_ BO_ 16 "Wegfahrsperrenbotschaft (entspricht der Botschaft 'MSG1_WFS_Anfrage' im MLB)";
CM_ SG_ 16 WFS_MSG1_IMS "Wegfahrsperre";
BA_DEF_ SG_  "DERIVATE_Pruefung" ENUM  "offen","geprüft";
BA_DEF_ SG_  "HYB_Rx_Baureihe" ENUM  "G1+Derivate","nur G1","nur Derivate";
BA_DEF_ SG_  "HYB_Rx_Verwendung" ENUM  "DERIV_Rout","DERIV_Calc","DERIV_Rout+DERIV_Calc";
BA_DEF_ SG_  "GenSigSwitchedByIgnition" ENUM  "No","Yes";
BA_DEF_ SG_  "GenSigEnvVarType" ENUM  "int","float","undef";
BA_DEF_ SG_  "GenSigAutoGenSnd" ENUM  "No","Yes";
BA_DEF_ SG_  "GenSigAutoGenDsp" ENUM  "No","Yes";
BA_DEF_ SG_  "GenSigActiveRepetitions" INT -2147483648 2147483647;
BA_DEF_ SG_  "GenSigFuncType" ENUM  "NoFunction","MsgCounter","CRC-8","XOR","XOR-2","DatedBit","SW-Kl15","CHK","Constant","Protocol";
BA_DEF_ SG_  "Info_BCM_HutHut_Kommunikation" ENUM  "Nein","Ja";
BA_DEF_ SG_  "NWM-WakeupAllowed" ENUM  "No","Yes";
BA_DEF_ SG_  "GenSigInactiveValue" STRING ;
BA_DEF_ SG_  "GenSigMissingSourceValue" INT 0 2147483647;
BA_DEF_ SG_  "GenSigStartValue" INT 0 0;
BA_DEF_ SG_  "Fehlerwert" HEX 0 2147483647;
BA_DEF_ SG_  "Bemerkung" STRING ;
BA_DEF_ SG_  "GenSigSendType" ENUM  "Cyclic","OnWrite","OnWriteWithRepetition","OnChange","OnChangeWithRepetition","IfActive","IfActiveWithRepetition","NoSigSendType";
BA_DEF_ BO_  "NmMessage" ENUM  "No","Yes";
BA_DEF_ BO_  "GenMsgAutoGenSnd" ENUM  "No","Yes";
BA_DEF_ BO_  "GenMsgAutoGenDsp" ENUM  "No","Yes";
BA_DEF_ BO_  "MsgType" ENUM  "Broadcast","Event","NM ","NMH","TP2.0","ISO-TP ","BAP","EID";
BA_DEF_ BO_  "GenMsgChkConstant" HEX 0 4095;
BA_DEF_ BO_  "sim_GenMsgILSupport" ENUM  "No","Yes";
BA_DEF_ BO_  "NWM-Botschaft" ENUM  "No","Yes";
BA_DEF_ BO_  "VAGTP20_StatConnection" ENUM  "No","Yes";
BA_DEF_ BO_  "VAGTP20_DynSetup" ENUM  "No","Yes";
BA_DEF_ BO_  "VAGTP20_DynConnection" ENUM  "No","Yes";
BA_DEF_ BO_  "VAGTP20_API" HEX 0 255;
BA_DEF_ BO_  "Direkt_1zu1" ENUM  "Nein","Ja";
BA_DEF_ BO_  "GenMsgSendType" ENUM  "Cyclic","NotUsed","NotUsed","NotUsed","NotUsed","NotUsed","NotUsed","IfActive","NoMsgSendType","NotUsed";
BA_DEF_ BO_  "DiagResponse" ENUM  "No","Yes";
BA_DEF_ BO_  "DiagRequest" ENUM  "No","Yes";
BA_DEF_ BO_  "GenMsgDelayTime" INT 0 65535;
BA_DEF_ BO_  "GenMsgStartDelayTime" INT 0 65535;
BA_DEF_ BO_  "GenMsgILSupport" ENUM  "No","Yes";
BA_DEF_ BO_  "NmhMessage" ENUM  "No","Yes";
BA_DEF_ BO_  "GenMsgNrOfRepetition" INT 0 65535;
BA_DEF_ BO_  "GenMsgCycleTimeFast" INT 0 65535;
BA_DEF_ BO_  "DiagState" ENUM  "No","Yes";
BA_DEF_ BO_  "GenMsgCycleTime" INT 0 65535;
BA_DEF_REL_ BU_BO_REL_  "HYB_Tx_Verwendung" ENUM  "Rout","Calc";
BA_DEF_REL_ BU_BO_REL_  "HYB_Tx_Baureihe" ENUM  "G1+Derivate","G1","Derivate","vector_leerstring";
BA_DEF_REL_ BU_SG_REL_  "GenSigTimeoutTime" INT 0 65535;
BA_DEF_DEF_  "DERIVATE_Pruefung" "offen";
BA_DEF_DEF_  "HYB_Rx_Baureihe" "G1+Derivate";
BA_DEF_DEF_  "HYB_Rx_Verwendung" "DERIV_Rout";
BA_DEF_DEF_  "GenSigSwitchedByIgnition" "No";
BA_DEF_DEF_  "GenSigEnvVarType" "undef";
BA_DEF_DEF_  "GenSigAutoGenSnd" "No";
BA_DEF_DEF_  "GenSigAutoGenDsp" "No";
BA_DEF_DEF_  "GenSigActiveRepetitions" 0;
BA_DEF_DEF_  "GenSigFuncType" "NoFunction";
BA_DEF_DEF_  "Info_BCM_HutHut_Kommunikation" "Nein";
BA_DEF_DEF_  "NWM-WakeupAllowed" "Yes";
BA_DEF_DEF_  "GenSigInactiveValue" "0";
BA_DEF_DEF_  "GenSigMissingSourceValue" 0;
BA_DEF_DEF_  "GenSigStartValue" 0;
BA_DEF_DEF_  "Fehlerwert" 0;
BA_DEF_DEF_  "Bemerkung" "";
BA_DEF_DEF_  "GenSigSendType" "Cyclic";
BA_DEF_DEF_  "NmMessage" "No";
BA_DEF_DEF_  "GenMsgAutoGenSnd" "Yes";
BA_DEF_DEF_  "GenMsgAutoGenDsp" "Yes";
BA_DEF_DEF_  "MsgType" "Broadcast";
BA_DEF_DEF_  "GenMsgChkConstant" 0;
BA_DEF_DEF_  "sim_GenMsgILSupport" "No";
BA_DEF_DEF_  "NWM-Botschaft" "No";
BA_DEF_DEF_  "VAGTP20_StatConnection" "No";
BA_DEF_DEF_  "VAGTP20_DynSetup" "No";
BA_DEF_DEF_  "VAGTP20_DynConnection" "No";
BA_DEF_DEF_  "VAGTP20_API" 1;
BA_DEF_DEF_  "Direkt_1zu1" "Nein";
BA_DEF_DEF_  "GenMsgSendType" "Cyclic";
BA_DEF_DEF_  "DiagResponse" "No";
BA_DEF_DEF_  "DiagRequest" "No";
BA_DEF_DEF_  "GenMsgDelayTime" 0;
BA_DEF_DEF_  "GenMsgStartDelayTime" 0;
BA_DEF_DEF_  "GenMsgILSupport" "No";
BA_DEF_DEF_  "NmhMessage" "No";
BA_DEF_DEF_  "GenMsgNrOfRepetition" 0;
BA_DEF_DEF_  "GenMsgCycleTimeFast" 0;
BA_DEF_DEF_  "DiagState" "No";
BA_DEF_DEF_  "GenMsgCycleTime" 0;
BA_DEF_DEF_REL_ "HYB_Tx_Verwendung" "Rout";
BA_DEF_DEF_REL_ "HYB_Tx_Baureihe" "G1+Derivate";
BA_DEF_DEF_REL_ "GenSigTimeoutTime" 0;
BA_ "GenMsgCycleTime" BO_ 1445 2000;
BA_ "GenMsgILSupport" BO_ 1445 1;
BA_ "VAGTP20_API" BO_ 1445 0;
BA_ "GenMsgSendType" BO_ 1666 8;
BA_ "VAGTP20_API" BO_ 1666 0;
BA_ "GenMsgSendType" BO_ 2617239041 8;
BA_ "VAGTP20_API" BO_ 2617239041 0;
BA_ "GenMsgCycleTime" BO_ 1527 1000;
BA_ "GenMsgILSupport" BO_ 1527 1;
BA_ "VAGTP20_API" BO_ 1527 0;
BA_ "GenMsgCycleTime" BO_ 1525 1000;
BA_ "GenMsgILSupport" BO_ 1525 1;
BA_ "VAGTP20_API" BO_ 1525 0;
BA_ "GenMsgCycleTime" BO_ 687 50;
BA_ "GenMsgILSupport" BO_ 687 1;
BA_ "VAGTP20_API" BO_ 687 0;
BA_ "GenMsgCycleTime" BO_ 1532 500;
BA_ "GenMsgILSupport" BO_ 1532 1;
BA_ "VAGTP20_API" BO_ 1532 0;
BA_ "GenMsgCycleTime" BO_ 1788 200;
BA_ "NmhMessage" BO_ 1788 1;
BA_ "GenMsgSendType" BO_ 1788 8;
BA_ "VAGTP20_API" BO_ 1788 0;
BA_ "MsgType" BO_ 1788 3;
BA_ "DiagResponse" BO_ 1966 1;
BA_ "GenMsgSendType" BO_ 1966 8;
BA_ "VAGTP20_API" BO_ 1966 0;
BA_ "MsgType" BO_ 1966 5;
BA_ "GenMsgAutoGenDsp" BO_ 1966 0;
BA_ "GenMsgAutoGenSnd" BO_ 1966 0;
BA_ "DiagRequest" BO_ 1860 1;
BA_ "GenMsgSendType" BO_ 1860 8;
BA_ "VAGTP20_API" BO_ 1860 0;
BA_ "MsgType" BO_ 1860 5;
BA_ "GenMsgAutoGenDsp" BO_ 1860 0;
BA_ "GenMsgAutoGenSnd" BO_ 1860 0;
BA_ "GenMsgCycleTime" BO_ 1483 500;
BA_ "GenMsgILSupport" BO_ 1483 1;
BA_ "GenMsgDelayTime" BO_ 1483 100;
BA_ "VAGTP20_API" BO_ 1483 0;
BA_ "GenMsgCycleTime" BO_ 899 100;
BA_ "GenMsgILSupport" BO_ 899 1;
BA_ "VAGTP20_API" BO_ 899 0;
BA_ "GenMsgCycleTime" BO_ 1518 1000;
BA_ "GenMsgILSupport" BO_ 1518 1;
BA_ "VAGTP20_API" BO_ 1518 0;
BA_ "GenMsgCycleTime" BO_ 391 100;
BA_ "GenMsgILSupport" BO_ 391 1;
BA_ "GenMsgDelayTime" BO_ 391 40;
BA_ "VAGTP20_API" BO_ 391 0;
BA_ "GenMsgCycleTime" BO_ 1662 1000;
BA_ "GenMsgILSupport" BO_ 1662 1;
BA_ "GenMsgDelayTime" BO_ 1662 50;
BA_ "VAGTP20_API" BO_ 1662 0;
BA_ "GenMsgCycleTime" BO_ 1380 1000;
BA_ "GenMsgCycleTimeFast" BO_ 1380 100;
BA_ "GenMsgNrOfRepetition" BO_ 1380 5;
BA_ "GenMsgILSupport" BO_ 1380 1;
BA_ "GenMsgDelayTime" BO_ 1380 100;
BA_ "VAGTP20_API" BO_ 1380 0;
BA_ "GenMsgCycleTime" BO_ 1385 500;
BA_ "GenMsgILSupport" BO_ 1385 1;
BA_ "GenMsgDelayTime" BO_ 1385 50;
BA_ "VAGTP20_API" BO_ 1385 0;
BA_ "GenMsgCycleTime" BO_ 1482 500;
BA_ "GenMsgILSupport" BO_ 1482 1;
BA_ "GenMsgDelayTime" BO_ 1482 50;
BA_ "VAGTP20_API" BO_ 1482 0;
BA_ "GenMsgChkConstant" BO_ 1482 67;
BA_ "GenMsgCycleTime" BO_ 1519 500;
BA_ "GenMsgILSupport" BO_ 1519 1;
BA_ "VAGTP20_API" BO_ 1519 0;
BA_ "GenMsgCycleTime" BO_ 1438 500;
BA_ "GenMsgILSupport" BO_ 1438 1;
BA_ "VAGTP20_API" BO_ 1438 0;
BA_ "GenMsgCycleTime" BO_ 1428 500;
BA_ "GenMsgILSupport" BO_ 1428 1;
BA_ "GenMsgDelayTime" BO_ 1428 50;
BA_ "VAGTP20_API" BO_ 1428 0;
BA_ "GenMsgILSupport" BO_ 24 1;
BA_ "GenMsgSendType" BO_ 24 8;
BA_ "Direkt_1zu1" BO_ 24 1;
BA_ "VAGTP20_API" BO_ 24 0;
BA_ "sim_GenMsgILSupport" BO_ 24 1;
BA_ "MsgType" BO_ 24 1;
BA_ "GenMsgILSupport" BO_ 25 1;
BA_ "GenMsgSendType" BO_ 25 8;
BA_ "Direkt_1zu1" BO_ 25 1;
BA_ "VAGTP20_API" BO_ 25 0;
BA_ "MsgType" BO_ 25 1;
BA_ "GenMsgCycleTime" BO_ 1603 1000;
BA_ "GenMsgILSupport" BO_ 1603 1;
BA_ "GenMsgDelayTime" BO_ 1603 100;
BA_ "VAGTP20_API" BO_ 1603 0;
BA_ "sim_GenMsgILSupport" BO_ 1603 1;
BA_ "GenMsgCycleTime" BO_ 267 100;
BA_ "GenMsgCycleTimeFast" BO_ 267 20;
BA_ "GenMsgNrOfRepetition" BO_ 267 1;
BA_ "GenMsgILSupport" BO_ 267 1;
BA_ "GenMsgDelayTime" BO_ 267 20;
BA_ "Direkt_1zu1" BO_ 267 1;
BA_ "VAGTP20_API" BO_ 267 0;
BA_ "sim_GenMsgILSupport" BO_ 267 1;
BA_ "GenMsgChkConstant" BO_ 267 10;
BA_ "GenMsgCycleTime" BO_ 260 20;
BA_ "GenMsgILSupport" BO_ 260 1;
BA_ "Direkt_1zu1" BO_ 260 1;
BA_ "VAGTP20_API" BO_ 260 0;
BA_ "sim_GenMsgILSupport" BO_ 260 1;
BA_ "GenMsgChkConstant" BO_ 260 5;
BA_ "GenMsgCycleTime" BO_ 64 50;
BA_ "GenMsgILSupport" BO_ 64 1;
BA_ "GenMsgDelayTime" BO_ 64 10;
BA_ "Direkt_1zu1" BO_ 64 1;
BA_ "VAGTP20_API" BO_ 64 0;
BA_ "sim_GenMsgILSupport" BO_ 64 1;
BA_ "GenMsgChkConstant" BO_ 64 64;
BA_ "GenMsgCycleTime" BO_ 1312 200;
BA_ "GenMsgILSupport" BO_ 1312 1;
BA_ "VAGTP20_API" BO_ 1312 0;
BA_ "sim_GenMsgILSupport" BO_ 1312 1;
BA_ "GenMsgCycleTime" BO_ 777 50;
BA_ "GenMsgILSupport" BO_ 777 1;
BA_ "VAGTP20_API" BO_ 777 0;
BA_ "sim_GenMsgILSupport" BO_ 777 1;
BA_ "GenMsgChkConstant" BO_ 777 10;
BA_ "GenMsgCycleTime" BO_ 1714 1000;
BA_ "GenMsgILSupport" BO_ 1714 1;
BA_ "VAGTP20_API" BO_ 1714 0;
BA_ "sim_GenMsgILSupport" BO_ 1714 1;
BA_ "GenMsgCycleTime" BO_ 1313 200;
BA_ "GenMsgILSupport" BO_ 1313 1;
BA_ "VAGTP20_API" BO_ 1313 0;
BA_ "sim_GenMsgILSupport" BO_ 1313 1;
BA_ "GenMsgCycleTime" BO_ 134 10;
BA_ "GenMsgILSupport" BO_ 134 1;
BA_ "Direkt_1zu1" BO_ 134 1;
BA_ "VAGTP20_API" BO_ 134 0;
BA_ "sim_GenMsgILSupport" BO_ 134 1;
BA_ "GenMsgChkConstant" BO_ 134 134;
BA_ "GenMsgCycleTime" BO_ 1633 100;
BA_ "GenMsgILSupport" BO_ 1633 1;
BA_ "Direkt_1zu1" BO_ 1633 1;
BA_ "VAGTP20_API" BO_ 1633 0;
BA_ "sim_GenMsgILSupport" BO_ 1633 1;
BA_ "GenMsgCycleTime" BO_ 780 40;
BA_ "GenMsgILSupport" BO_ 780 1;
BA_ "Direkt_1zu1" BO_ 780 1;
BA_ "VAGTP20_API" BO_ 780 0;
BA_ "sim_GenMsgILSupport" BO_ 780 1;
BA_ "GenMsgChkConstant" BO_ 780 15;
BA_ "GenMsgCycleTime" BO_ 1743 200;
BA_ "NmhMessage" BO_ 1743 1;
BA_ "GenMsgSendType" BO_ 1743 8;
BA_ "VAGTP20_API" BO_ 1743 0;
BA_ "MsgType" BO_ 1743 3;
BA_ "GenMsgCycleTime" BO_ 786 50;
BA_ "GenMsgILSupport" BO_ 786 1;
BA_ "GenMsgDelayTime" BO_ 786 10;
BA_ "Direkt_1zu1" BO_ 786 1;
BA_ "sim_GenMsgILSupport" BO_ 786 1;
BA_ "GenMsgChkConstant" BO_ 786 17;
BA_ "GenMsgILSupport" BO_ 16 1;
BA_ "GenMsgSendType" BO_ 16 8;
BA_ "Direkt_1zu1" BO_ 16 1;
BA_ "VAGTP20_API" BO_ 16 0;
BA_ "sim_GenMsgILSupport" BO_ 16 1;
BA_ "MsgType" BO_ 16 1;
BA_ "NWM-WakeupAllowed" SG_ 1445 OBC_CVN_VLD 0;
BA_ "GenSigSwitchedByIgnition" SG_ 1445 OBC_CVN_VLD 1;
BA_ "GenSigSendType" SG_ 1445 OBC_CVN_VLD 7;
BA_ "GenSigStartValue" SG_ 1445 OBC_CALID_Index_01 48;
BA_ "NWM-WakeupAllowed" SG_ 1445 OBC_CALID_Index_01 0;
BA_ "GenSigSwitchedByIgnition" SG_ 1445 OBC_CALID_Index_01 1;
BA_ "GenSigSendType" SG_ 1445 OBC_CALID_Index_01 7;
BA_ "GenSigStartValue" SG_ 1445 OBC_CALID_Index_05 48;
BA_ "NWM-WakeupAllowed" SG_ 1445 OBC_CALID_Index_05 0;
BA_ "GenSigSwitchedByIgnition" SG_ 1445 OBC_CALID_Index_05 1;
BA_ "GenSigSendType" SG_ 1445 OBC_CALID_Index_05 7;
BA_ "GenSigStartValue" SG_ 1445 OBC_CALID_Index_09 48;
BA_ "NWM-WakeupAllowed" SG_ 1445 OBC_CALID_Index_09 0;
BA_ "GenSigSwitchedByIgnition" SG_ 1445 OBC_CALID_Index_09 1;
BA_ "GenSigSendType" SG_ 1445 OBC_CALID_Index_09 7;
BA_ "GenSigStartValue" SG_ 1445 OBC_CALID_Index_13 48;
BA_ "NWM-WakeupAllowed" SG_ 1445 OBC_CALID_Index_13 0;
BA_ "GenSigSwitchedByIgnition" SG_ 1445 OBC_CALID_Index_13 1;
BA_ "GenSigSendType" SG_ 1445 OBC_CALID_Index_13 7;
BA_ "GenSigStartValue" SG_ 1445 OBC_CALID_Index_02 48;
BA_ "NWM-WakeupAllowed" SG_ 1445 OBC_CALID_Index_02 0;
BA_ "GenSigSwitchedByIgnition" SG_ 1445 OBC_CALID_Index_02 1;
BA_ "GenSigSendType" SG_ 1445 OBC_CALID_Index_02 7;
BA_ "GenSigStartValue" SG_ 1445 OBC_CALID_Index_06 48;
BA_ "NWM-WakeupAllowed" SG_ 1445 OBC_CALID_Index_06 0;
BA_ "GenSigSwitchedByIgnition" SG_ 1445 OBC_CALID_Index_06 1;
BA_ "GenSigSendType" SG_ 1445 OBC_CALID_Index_06 7;
BA_ "GenSigStartValue" SG_ 1445 OBC_CALID_Index_10 48;
BA_ "NWM-WakeupAllowed" SG_ 1445 OBC_CALID_Index_10 0;
BA_ "GenSigSwitchedByIgnition" SG_ 1445 OBC_CALID_Index_10 1;
BA_ "GenSigSendType" SG_ 1445 OBC_CALID_Index_10 7;
BA_ "GenSigStartValue" SG_ 1445 OBC_CALID_Index_14 48;
BA_ "NWM-WakeupAllowed" SG_ 1445 OBC_CALID_Index_14 0;
BA_ "GenSigSwitchedByIgnition" SG_ 1445 OBC_CALID_Index_14 1;
BA_ "GenSigSendType" SG_ 1445 OBC_CALID_Index_14 7;
BA_ "GenSigStartValue" SG_ 1445 OBC_CALID_Index_03 48;
BA_ "NWM-WakeupAllowed" SG_ 1445 OBC_CALID_Index_03 0;
BA_ "GenSigSwitchedByIgnition" SG_ 1445 OBC_CALID_Index_03 1;
BA_ "GenSigSendType" SG_ 1445 OBC_CALID_Index_03 7;
BA_ "GenSigStartValue" SG_ 1445 OBC_CALID_Index_07 48;
BA_ "NWM-WakeupAllowed" SG_ 1445 OBC_CALID_Index_07 0;
BA_ "GenSigSwitchedByIgnition" SG_ 1445 OBC_CALID_Index_07 1;
BA_ "GenSigSendType" SG_ 1445 OBC_CALID_Index_07 7;
BA_ "GenSigStartValue" SG_ 1445 OBC_CALID_Index_11 48;
BA_ "NWM-WakeupAllowed" SG_ 1445 OBC_CALID_Index_11 0;
BA_ "GenSigSwitchedByIgnition" SG_ 1445 OBC_CALID_Index_11 1;
BA_ "GenSigSendType" SG_ 1445 OBC_CALID_Index_11 7;
BA_ "GenSigStartValue" SG_ 1445 OBC_CALID_Index_15 48;
BA_ "NWM-WakeupAllowed" SG_ 1445 OBC_CALID_Index_15 0;
BA_ "GenSigSwitchedByIgnition" SG_ 1445 OBC_CALID_Index_15 1;
BA_ "GenSigSendType" SG_ 1445 OBC_CALID_Index_15 7;
BA_ "GenSigStartValue" SG_ 1445 OBC_CALID_Index_04 48;
BA_ "NWM-WakeupAllowed" SG_ 1445 OBC_CALID_Index_04 0;
BA_ "GenSigSwitchedByIgnition" SG_ 1445 OBC_CALID_Index_04 1;
BA_ "GenSigSendType" SG_ 1445 OBC_CALID_Index_04 7;
BA_ "GenSigStartValue" SG_ 1445 OBC_CALID_Index_08 48;
BA_ "NWM-WakeupAllowed" SG_ 1445 OBC_CALID_Index_08 0;
BA_ "GenSigSwitchedByIgnition" SG_ 1445 OBC_CALID_Index_08 1;
BA_ "GenSigSendType" SG_ 1445 OBC_CALID_Index_08 7;
BA_ "GenSigStartValue" SG_ 1445 OBC_CALID_Index_12 48;
BA_ "NWM-WakeupAllowed" SG_ 1445 OBC_CALID_Index_12 0;
BA_ "GenSigSwitchedByIgnition" SG_ 1445 OBC_CALID_Index_12 1;
BA_ "GenSigSendType" SG_ 1445 OBC_CALID_Index_12 7;
BA_ "GenSigStartValue" SG_ 1445 OBC_CALID_Index_16 48;
BA_ "NWM-WakeupAllowed" SG_ 1445 OBC_CALID_Index_16 0;
BA_ "GenSigSwitchedByIgnition" SG_ 1445 OBC_CALID_Index_16 1;
BA_ "GenSigSendType" SG_ 1445 OBC_CALID_Index_16 7;
BA_ "NWM-WakeupAllowed" SG_ 1445 OBC_CVN_Byte_1 0;
BA_ "GenSigSwitchedByIgnition" SG_ 1445 OBC_CVN_Byte_1 1;
BA_ "GenSigSendType" SG_ 1445 OBC_CVN_Byte_1 7;
BA_ "NWM-WakeupAllowed" SG_ 1445 OBC_CVN_Byte_2 0;
BA_ "GenSigSwitchedByIgnition" SG_ 1445 OBC_CVN_Byte_2 1;
BA_ "GenSigSendType" SG_ 1445 OBC_CVN_Byte_2 7;
BA_ "NWM-WakeupAllowed" SG_ 1445 OBC_CVN_Byte_3 0;
BA_ "GenSigSwitchedByIgnition" SG_ 1445 OBC_CVN_Byte_3 1;
BA_ "GenSigSendType" SG_ 1445 OBC_CVN_Byte_3 7;
BA_ "NWM-WakeupAllowed" SG_ 1445 OBC_CALID_CVN_MUX 0;
BA_ "GenSigSwitchedByIgnition" SG_ 1445 OBC_CALID_CVN_MUX 1;
BA_ "NWM-WakeupAllowed" SG_ 1445 OBC_CVN_Byte_4 0;
BA_ "GenSigSwitchedByIgnition" SG_ 1445 OBC_CVN_Byte_4 1;
BA_ "GenSigSendType" SG_ 1445 OBC_CVN_Byte_4 7;
BA_ "NWM-WakeupAllowed" SG_ 1666 CCP_LE_CRO_01_Data 0;
BA_ "NWM-WakeupAllowed" SG_ 2617239041 CCP_LE_DTO_01_Data 0;
BA_ "Fehlerwert" SG_ 1527 RW_Sekundaer_Reichweite 2047;
BA_ "GenSigStartValue" SG_ 1527 RW_Sekundaer_Reichweite 2046;
BA_ "NWM-WakeupAllowed" SG_ 1527 RW_Sekundaer_Reichweite 0;
BA_ "GenSigStartValue" SG_ 1527 RW_Sek_Reichweitenv_Einheit 3;
BA_ "NWM-WakeupAllowed" SG_ 1527 RW_Sek_Reichweitenv_Einheit 0;
BA_ "GenSigStartValue" SG_ 1527 RW_Sek_Reichweitenverbrauch 2047;
BA_ "NWM-WakeupAllowed" SG_ 1527 RW_Sek_Reichweitenverbrauch 0;
BA_ "Fehlerwert" SG_ 1525 RW_RWDS_Lastprofil 2047;
BA_ "NWM-WakeupAllowed" SG_ 1525 RW_RWDS_Lastprofil 0;
BA_ "GenSigAutoGenDsp" SG_ 1525 RW_RWDS_Lastprofil 1;
BA_ "GenSigAutoGenSnd" SG_ 1525 RW_RWDS_Lastprofil 1;
BA_ "GenSigEnvVarType" SG_ 1525 RW_RWDS_Lastprofil 0;
BA_ "Fehlerwert" SG_ 1525 RW_Gesamt_Reichweite 2047;
BA_ "GenSigStartValue" SG_ 1525 RW_Gesamt_Reichweite 2046;
BA_ "NWM-WakeupAllowed" SG_ 1525 RW_Gesamt_Reichweite 0;
BA_ "GenSigStartValue" SG_ 1525 RW_Prim_Reichweitenverbrauch 2047;
BA_ "NWM-WakeupAllowed" SG_ 1525 RW_Prim_Reichweitenverbrauch 0;
BA_ "GenSigStartValue" SG_ 1525 RW_Prim_Reichweitenv_Einheit 3;
BA_ "NWM-WakeupAllowed" SG_ 1525 RW_Prim_Reichweitenv_Einheit 0;
BA_ "Fehlerwert" SG_ 1525 RW_Primaer_Reichweite 2047;
BA_ "GenSigStartValue" SG_ 1525 RW_Primaer_Reichweite 2046;
BA_ "NWM-WakeupAllowed" SG_ 1525 RW_Primaer_Reichweite 0;
BA_ "NWM-WakeupAllowed" SG_ 687 BMS_Rekuperation 0;
BA_ "GenSigAutoGenDsp" SG_ 687 BMS_Rekuperation 1;
BA_ "GenSigAutoGenSnd" SG_ 687 BMS_Rekuperation 1;
BA_ "GenSigEnvVarType" SG_ 687 BMS_Rekuperation 0;
BA_ "NWM-WakeupAllowed" SG_ 687 BMS_Rekuperation_Ueberlauf 0;
BA_ "GenSigAutoGenDsp" SG_ 687 BMS_Rekuperation_Ueberlauf 1;
BA_ "GenSigAutoGenSnd" SG_ 687 BMS_Rekuperation_Ueberlauf 1;
BA_ "GenSigEnvVarType" SG_ 687 BMS_Rekuperation_Ueberlauf 0;
BA_ "NWM-WakeupAllowed" SG_ 687 BMS_Verbrauch 0;
BA_ "GenSigAutoGenDsp" SG_ 687 BMS_Verbrauch 1;
BA_ "GenSigAutoGenSnd" SG_ 687 BMS_Verbrauch 1;
BA_ "GenSigEnvVarType" SG_ 687 BMS_Verbrauch 0;
BA_ "NWM-WakeupAllowed" SG_ 687 BMS_Verbrauch_Ueberlauf 0;
BA_ "GenSigAutoGenDsp" SG_ 687 BMS_Verbrauch_Ueberlauf 1;
BA_ "GenSigAutoGenSnd" SG_ 687 BMS_Verbrauch_Ueberlauf 1;
BA_ "GenSigEnvVarType" SG_ 687 BMS_Verbrauch_Ueberlauf 0;
BA_ "NWM-WakeupAllowed" SG_ 1532 KL_Autobetrieb_HL 0;
BA_ "GenSigAutoGenDsp" SG_ 1532 KL_Autobetrieb_HL 1;
BA_ "GenSigAutoGenSnd" SG_ 1532 KL_Autobetrieb_HL 1;
BA_ "NWM-WakeupAllowed" SG_ 1532 KL_Autobetrieb_HR 0;
BA_ "GenSigAutoGenDsp" SG_ 1532 KL_Autobetrieb_HR 1;
BA_ "GenSigAutoGenSnd" SG_ 1532 KL_Autobetrieb_HR 1;
BA_ "NWM-WakeupAllowed" SG_ 1532 KL_Autobetrieb_VL 0;
BA_ "GenSigAutoGenDsp" SG_ 1532 KL_Autobetrieb_VL 1;
BA_ "GenSigAutoGenSnd" SG_ 1532 KL_Autobetrieb_VL 1;
BA_ "NWM-WakeupAllowed" SG_ 1532 KL_Autobetrieb_VR 0;
BA_ "GenSigAutoGenDsp" SG_ 1532 KL_Autobetrieb_VR 1;
BA_ "GenSigAutoGenSnd" SG_ 1532 KL_Autobetrieb_VR 1;
BA_ "Fehlerwert" SG_ 1532 KL_Zieltemperatur_HL 31;
BA_ "GenSigStartValue" SG_ 1532 KL_Zieltemperatur_HL 30;
BA_ "NWM-WakeupAllowed" SG_ 1532 KL_Zieltemperatur_HL 0;
BA_ "GenSigAutoGenDsp" SG_ 1532 KL_Zieltemperatur_HL 1;
BA_ "GenSigAutoGenSnd" SG_ 1532 KL_Zieltemperatur_HL 1;
BA_ "Fehlerwert" SG_ 1532 KL_Zieltemperatur_HR 31;
BA_ "GenSigStartValue" SG_ 1532 KL_Zieltemperatur_HR 30;
BA_ "NWM-WakeupAllowed" SG_ 1532 KL_Zieltemperatur_HR 0;
BA_ "GenSigAutoGenDsp" SG_ 1532 KL_Zieltemperatur_HR 1;
BA_ "GenSigAutoGenSnd" SG_ 1532 KL_Zieltemperatur_HR 1;
BA_ "Fehlerwert" SG_ 1532 KL_Zieltemperatur_VL 31;
BA_ "GenSigStartValue" SG_ 1532 KL_Zieltemperatur_VL 30;
BA_ "NWM-WakeupAllowed" SG_ 1532 KL_Zieltemperatur_VL 0;
BA_ "GenSigAutoGenDsp" SG_ 1532 KL_Zieltemperatur_VL 1;
BA_ "GenSigAutoGenSnd" SG_ 1532 KL_Zieltemperatur_VL 1;
BA_ "Fehlerwert" SG_ 1532 KL_Zieltemperatur_VR 31;
BA_ "GenSigStartValue" SG_ 1532 KL_Zieltemperatur_VR 30;
BA_ "NWM-WakeupAllowed" SG_ 1532 KL_Zieltemperatur_VR 0;
BA_ "GenSigAutoGenDsp" SG_ 1532 KL_Zieltemperatur_VR 1;
BA_ "GenSigAutoGenSnd" SG_ 1532 KL_Zieltemperatur_VR 1;
BA_ "NWM-WakeupAllowed" SG_ 1788 NMH_Ladegeraet_Start_1 0;
BA_ "GenSigAutoGenDsp" SG_ 1788 NMH_Ladegeraet_Start_1 1;
BA_ "GenSigAutoGenSnd" SG_ 1788 NMH_Ladegeraet_Start_1 1;
BA_ "NWM-WakeupAllowed" SG_ 1788 NMH_Ladegeraet_Start_2 0;
BA_ "GenSigAutoGenDsp" SG_ 1788 NMH_Ladegeraet_Start_2 1;
BA_ "GenSigAutoGenSnd" SG_ 1788 NMH_Ladegeraet_Start_2 1;
BA_ "NWM-WakeupAllowed" SG_ 1788 NMH_Ladegeraet_Normal_Mode_1 0;
BA_ "GenSigAutoGenDsp" SG_ 1788 NMH_Ladegeraet_Normal_Mode_1 1;
BA_ "GenSigAutoGenSnd" SG_ 1788 NMH_Ladegeraet_Normal_Mode_1 1;
BA_ "NWM-WakeupAllowed" SG_ 1788 NMH_Ladegeraet_Normal_Mode_2 0;
BA_ "GenSigAutoGenDsp" SG_ 1788 NMH_Ladegeraet_Normal_Mode_2 1;
BA_ "GenSigAutoGenSnd" SG_ 1788 NMH_Ladegeraet_Normal_Mode_2 1;
BA_ "NWM-WakeupAllowed" SG_ 1788 NMH_Ladegeraet_Car_WakeUp 0;
BA_ "GenSigEnvVarType" SG_ 1788 NMH_Ladegeraet_Car_WakeUp 0;
BA_ "GenSigEnvVarType" SG_ 1788 NMH_Ladegeraet_Per_WakeUp 0;
BA_ "GenSigEnvVarType" SG_ 1788 NMH_Ladegeraet_Fkt_WakeUp 0;
BA_ "NWM-WakeupAllowed" SG_ 1788 NMH_Ladegeraet_Klemme_15 0;
BA_ "GenSigEnvVarType" SG_ 1788 NMH_Ladegeraet_Klemme_15 0;
BA_ "NWM-WakeupAllowed" SG_ 1788 NMH_Ladegeraet_Diagnose 0;
BA_ "GenSigEnvVarType" SG_ 1788 NMH_Ladegeraet_Diagnose 0;
BA_ "NWM-WakeupAllowed" SG_ 1788 NMH_Ladegeraet_MindestAktivZeit 0;
BA_ "GenSigEnvVarType" SG_ 1788 NMH_Ladegeraet_MindestAktivZeit 0;
BA_ "NWM-WakeupAllowed" SG_ 1788 NMH_Ladegeraet_Signalfehler 0;
BA_ "GenSigAutoGenDsp" SG_ 1788 NMH_Ladegeraet_Signalfehler 1;
BA_ "GenSigAutoGenSnd" SG_ 1788 NMH_Ladegeraet_Signalfehler 1;
BA_ "NWM-WakeupAllowed" SG_ 1788 NMH_Ladegeraet_TimeOut_Fehler 0;
BA_ "GenSigEnvVarType" SG_ 1788 NMH_Ladegeraet_TimeOut_Fehler 0;
BA_ "NWM-WakeupAllowed" SG_ 1788 NMH_Ladegeraet_CAN_Diag_deaktiv 0;
BA_ "GenSigEnvVarType" SG_ 1788 NMH_Ladegeraet_CAN_Diag_deaktiv 0;
BA_ "NWM-WakeupAllowed" SG_ 1788 NMH_Ladegeraet_KompSchutz 0;
BA_ "GenSigEnvVarType" SG_ 1788 NMH_Ladegeraet_KompSchutz 0;
BA_ "NWM-WakeupAllowed" SG_ 1788 NMH_Ladegeraet_Mute_Mode 0;
BA_ "GenSigEnvVarType" SG_ 1788 NMH_Ladegeraet_Mute_Mode 0;
BA_ "NWM-WakeupAllowed" SG_ 1788 NMH_Ladegeraet_Transport_Mode 0;
BA_ "GenSigEnvVarType" SG_ 1788 NMH_Ladegeraet_Transport_Mode 0;
BA_ "NWM-WakeupAllowed" SG_ 1788 NMH_Ladegeraet_Abschaltstufe_000 0;
BA_ "GenSigEnvVarType" SG_ 1788 NMH_Ladegeraet_Abschaltstufe_000 0;
BA_ "NWM-WakeupAllowed" SG_ 1788 NMH_Ladegeraet_Eindraht_Fehler 0;
BA_ "GenSigEnvVarType" SG_ 1788 NMH_Ladegeraet_Eindraht_Fehler 0;
BA_ "NWM-WakeupAllowed" SG_ 1788 NMH_Ladegeraet_Lokalaktiv 0;
BA_ "GenSigAutoGenDsp" SG_ 1788 NMH_Ladegeraet_Lokalaktiv 1;
BA_ "GenSigAutoGenSnd" SG_ 1788 NMH_Ladegeraet_Lokalaktiv 1;
BA_ "NWM-WakeupAllowed" SG_ 1788 NMH_Ladegeraet_Subsystemaktiv 0;
BA_ "GenSigEnvVarType" SG_ 1788 NMH_Ladegeraet_Subsystemaktiv 0;
BA_ "NWM-WakeupAllowed" SG_ 1966 ISO_Ladegeraet_Resp_Data 0;
BA_ "GenSigAutoGenDsp" SG_ 1966 ISO_Ladegeraet_Resp_Data 1;
BA_ "GenSigAutoGenSnd" SG_ 1966 ISO_Ladegeraet_Resp_Data 1;
BA_ "NWM-WakeupAllowed" SG_ 1860 ISO_Ladegeraet_Req_Data 0;
BA_ "GenSigAutoGenDsp" SG_ 1860 ISO_Ladegeraet_Req_Data 1;
BA_ "GenSigAutoGenSnd" SG_ 1860 ISO_Ladegeraet_Req_Data 1;
BA_ "GenSigStartValue" SG_ 1483 PTC_Wassereinlasstemp 254;
BA_ "NWM-WakeupAllowed" SG_ 1483 PTC_Wassereinlasstemp 0;
BA_ "GenSigStartValue" SG_ 1483 PTC_Wasserauslasstemp 254;
BA_ "NWM-WakeupAllowed" SG_ 1483 PTC_Wasserauslasstemp 0;
BA_ "GenSigStartValue" SG_ 1483 PTC_HV_I_ist 254;
BA_ "NWM-WakeupAllowed" SG_ 1483 PTC_HV_I_ist 0;
BA_ "GenSigAutoGenDsp" SG_ 1483 PTC_HV_I_ist 1;
BA_ "GenSigAutoGenSnd" SG_ 1483 PTC_HV_I_ist 1;
BA_ "NWM-WakeupAllowed" SG_ 1483 KL_T_Charge 0;
BA_ "GenSigAutoGenDsp" SG_ 1483 KL_T_Charge 1;
BA_ "GenSigAutoGenSnd" SG_ 1483 KL_T_Charge 1;
BA_ "GenSigSendType" SG_ 1483 KL_T_Charge 3;
BA_ "NWM-WakeupAllowed" SG_ 1483 KBT_Defrost_aktiv 0;
BA_ "GenSigAutoGenDsp" SG_ 1483 KBT_Defrost_aktiv 1;
BA_ "GenSigAutoGenSnd" SG_ 1483 KBT_Defrost_aktiv 1;
BA_ "Fehlerwert" SG_ 1483 KL_WunschStrom_HV 255;
BA_ "GenSigStartValue" SG_ 1483 KL_WunschStrom_HV 254;
BA_ "NWM-WakeupAllowed" SG_ 1483 KL_WunschStrom_HV 0;
BA_ "GenSigAutoGenDsp" SG_ 1483 KL_WunschStrom_HV 1;
BA_ "GenSigAutoGenSnd" SG_ 1483 KL_WunschStrom_HV 1;
BA_ "Fehlerwert" SG_ 1483 KL_BattKond_WaPu_DZMax 63;
BA_ "GenSigStartValue" SG_ 1483 KL_BattKond_WaPu_DZMax 62;
BA_ "NWM-WakeupAllowed" SG_ 1483 KL_BattKond_WaPu_DZMax 0;
BA_ "GenSigAutoGenDsp" SG_ 1483 KL_BattKond_WaPu_DZMax 1;
BA_ "GenSigAutoGenSnd" SG_ 1483 KL_BattKond_WaPu_DZMax 1;
BA_ "NWM-WakeupAllowed" SG_ 1483 KL_Standklima_Status 0;
BA_ "GenSigAutoGenDsp" SG_ 1483 KL_Standklima_Status 1;
BA_ "GenSigAutoGenSnd" SG_ 1483 KL_Standklima_Status 1;
BA_ "NWM-WakeupAllowed" SG_ 899 CHA_Ziel_FahrPr_BMS 0;
BA_ "GenSigActiveRepetitions" SG_ 899 CHA_Ziel_FahrPr_BMS 5;
BA_ "GenSigAutoGenDsp" SG_ 899 CHA_Ziel_FahrPr_BMS 1;
BA_ "GenSigAutoGenSnd" SG_ 899 CHA_Ziel_FahrPr_BMS 1;
BA_ "GenSigEnvVarType" SG_ 899 CHA_Ziel_FahrPr_BMS 0;
BA_ "GenSigSendType" SG_ 1518 KL_T_STH 3;
BA_ "GenSigStartValue" SG_ 1518 Klima_08_PAG_alt 1;
BA_ "NWM-WakeupAllowed" SG_ 1518 Klima_08_PAG_alt 0;
BA_ "GenSigAutoGenDsp" SG_ 1518 Klima_08_PAG_alt 1;
BA_ "GenSigAutoGenSnd" SG_ 1518 Klima_08_PAG_alt 1;
BA_ "GenSigEnvVarType" SG_ 1518 Klima_08_PAG_alt 0;
BA_ "NWM-WakeupAllowed" SG_ 391 MO_Tankbereitschaft_Status 0;
BA_ "NWM-WakeupAllowed" SG_ 391 MO_Tankklappensteuerung 0;
BA_ "Fehlerwert" SG_ 391 MO_HVEM_MaxLeistung 511;
BA_ "GenSigStartValue" SG_ 391 MO_HVEM_MaxLeistung 510;
BA_ "NWM-WakeupAllowed" SG_ 391 MO_HVEM_MaxLeistung 0;
BA_ "GenSigAutoGenDsp" SG_ 391 MO_HVEM_MaxLeistung 1;
BA_ "GenSigAutoGenSnd" SG_ 391 MO_HVEM_MaxLeistung 1;
BA_ "NWM-WakeupAllowed" SG_ 391 EV_Rekuperationsstufe 0;
BA_ "Fehlerwert" SG_ 391 MO_Waehlpos 7;
BA_ "NWM-WakeupAllowed" SG_ 391 MO_Waehlpos 0;
BA_ "NWM-WakeupAllowed" SG_ 391 HV_Bordnetz_aktiv 0;
BA_ "NWM-WakeupAllowed" SG_ 391 MO_HVEM_Eskalation 0;
BA_ "GenSigSendType" SG_ 391 MO_HVEM_Eskalation 3;
BA_ "NWM-WakeupAllowed" SG_ 1662 LAD_02_CHK 0;
BA_ "GenSigFuncType" SG_ 1662 LAD_02_CHK 4;
BA_ "NWM-WakeupAllowed" SG_ 1662 LAD_02_BZ 0;
BA_ "GenSigFuncType" SG_ 1662 LAD_02_BZ 1;
BA_ "NWM-WakeupAllowed" SG_ 1662 LAD_Abregelung_Temperatur 0;
BA_ "NWM-WakeupAllowed" SG_ 1662 LAD_Abregelung_IU_Ein_Aus 0;
BA_ "NWM-WakeupAllowed" SG_ 1662 LAD_Abregelung_BuchseTemp 0;
BA_ "Fehlerwert" SG_ 1662 LAD_MaxLadLeistung_HV 511;
BA_ "GenSigStartValue" SG_ 1662 LAD_MaxLadLeistung_HV 510;
BA_ "NWM-WakeupAllowed" SG_ 1662 LAD_MaxLadLeistung_HV 0;
BA_ "Fehlerwert" SG_ 1662 LAD_CP_Stromlimit 127;
BA_ "GenSigStartValue" SG_ 1662 LAD_CP_Stromlimit 126;
BA_ "NWM-WakeupAllowed" SG_ 1662 LAD_CP_Stromlimit 0;
BA_ "Fehlerwert" SG_ 1662 LAD_PRX_Stromlimit 7;
BA_ "GenSigStartValue" SG_ 1662 LAD_PRX_Stromlimit 6;
BA_ "NWM-WakeupAllowed" SG_ 1662 LAD_PRX_Stromlimit 0;
BA_ "NWM-WakeupAllowed" SG_ 1662 LAD_CP_Erkennung 0;
BA_ "GenSigSendType" SG_ 1662 LAD_CP_Erkennung 3;
BA_ "NWM-WakeupAllowed" SG_ 1662 LAD_Stecker_Verriegelt 0;
BA_ "NWM-WakeupAllowed" SG_ 1662 LAD_Stecker_Gesteckt 0;
BA_ "GenSigSendType" SG_ 1662 LAD_Stecker_Gesteckt 3;
BA_ "NWM-WakeupAllowed" SG_ 1662 LAD_Kuehlbedarf 0;
BA_ "NWM-WakeupAllowed" SG_ 1662 LAD_Warnzustand 0;
BA_ "NWM-WakeupAllowed" SG_ 1662 LAD_Fehlerzustand 0;
BA_ "GenSigStartValue" SG_ 1662 LAD_Fehlerstatus 7;
BA_ "NWM-WakeupAllowed" SG_ 1662 LAD_Fehlerstatus 0;
BA_ "NWM-WakeupAllowed" SG_ 1662 LAD_Warnlampe_Anf 0;
BA_ "NWM-WakeupAllowed" SG_ 1380 LAD_01_CHK 0;
BA_ "GenSigFuncType" SG_ 1380 LAD_01_CHK 4;
BA_ "NWM-WakeupAllowed" SG_ 1380 LAD_01_BZ 0;
BA_ "GenSigFuncType" SG_ 1380 LAD_01_BZ 1;
BA_ "GenSigStartValue" SG_ 1380 LAD_IstModus 7;
BA_ "NWM-WakeupAllowed" SG_ 1380 LAD_IstModus 0;
BA_ "GenSigSendType" SG_ 1380 LAD_IstModus 5;
BA_ "Fehlerwert" SG_ 1380 LAD_AC_Istspannung 511;
BA_ "GenSigStartValue" SG_ 1380 LAD_AC_Istspannung 510;
BA_ "NWM-WakeupAllowed" SG_ 1380 LAD_AC_Istspannung 0;
BA_ "Fehlerwert" SG_ 1380 LAD_IstSpannung_HV 1023;
BA_ "GenSigStartValue" SG_ 1380 LAD_IstSpannung_HV 1022;
BA_ "NWM-WakeupAllowed" SG_ 1380 LAD_IstSpannung_HV 0;
BA_ "Fehlerwert" SG_ 1380 LAD_IstStrom_HV 1023;
BA_ "GenSigStartValue" SG_ 1380 LAD_IstStrom_HV 1022;
BA_ "NWM-WakeupAllowed" SG_ 1380 LAD_IstStrom_HV 0;
BA_ "NWM-WakeupAllowed" SG_ 1380 LAD_Status_Spgfreiheit 0;
BA_ "GenSigSendType" SG_ 1380 LAD_Status_Spgfreiheit 4;
BA_ "Fehlerwert" SG_ 1380 LAD_Temperatur 255;
BA_ "GenSigStartValue" SG_ 1380 LAD_Temperatur 254;
BA_ "NWM-WakeupAllowed" SG_ 1380 LAD_Temperatur 0;
BA_ "Fehlerwert" SG_ 1380 LAD_Verlustleistung 255;
BA_ "GenSigStartValue" SG_ 1380 LAD_Verlustleistung 254;
BA_ "NWM-WakeupAllowed" SG_ 1380 LAD_Verlustleistung 0;
BA_ "GenSigStartValue" SG_ 1385 HVEM_Abschaltstatus 7;
BA_ "NWM-WakeupAllowed" SG_ 1385 HVEM_Abschaltstatus 0;
BA_ "GenSigAutoGenDsp" SG_ 1385 HVEM_Abschaltstatus 1;
BA_ "GenSigAutoGenSnd" SG_ 1385 HVEM_Abschaltstatus 1;
BA_ "GenSigSendType" SG_ 1385 HVEM_Abschaltstatus 3;
BA_ "NWM-WakeupAllowed" SG_ 1385 HVEM_NVLeistungEmpf 0;
BA_ "GenSigSendType" SG_ 1385 HVEM_NVLeistungEmpf 3;
BA_ "NWM-WakeupAllowed" SG_ 1385 HVEM_KlimaMaxHVStrom 0;
BA_ "GenSigSendType" SG_ 1385 HVEM_KlimaMaxHVStrom 3;
BA_ "Fehlerwert" SG_ 1385 HVEM_LeistunsAnf 3;
BA_ "NWM-WakeupAllowed" SG_ 1385 HVEM_LeistunsAnf 0;
BA_ "GenSigSendType" SG_ 1385 HVEM_LeistunsAnf 3;
BA_ "GenSigStartValue" SG_ 1385 HVEM_Nachlad_Status 3;
BA_ "NWM-WakeupAllowed" SG_ 1385 HVEM_Nachlad_Status 0;
BA_ "GenSigSendType" SG_ 1385 HVEM_Nachlad_Status 3;
BA_ "Fehlerwert" SG_ 1385 HVEM_Anf_ReichweiteNV 3;
BA_ "NWM-WakeupAllowed" SG_ 1385 HVEM_Anf_ReichweiteNV 0;
BA_ "GenSigSendType" SG_ 1385 HVEM_Anf_ReichweiteNV 3;
BA_ "NWM-WakeupAllowed" SG_ 1385 HVEM_HV_Anf 0;
BA_ "GenSigSendType" SG_ 1385 HVEM_HV_Anf 3;
BA_ "NWM-WakeupAllowed" SG_ 1385 HVEM_Text_1 0;
BA_ "GenSigSendType" SG_ 1385 HVEM_Text_1 3;
BA_ "NWM-WakeupAllowed" SG_ 1385 HVEM_Nachladen_Anf 0;
BA_ "GenSigSendType" SG_ 1385 HVEM_Nachladen_Anf 3;
BA_ "Fehlerwert" SG_ 1385 HVEM_FreigabeKlimatisierung 3;
BA_ "GenSigStartValue" SG_ 1385 HVEM_FreigabeKlimatisierung 2;
BA_ "NWM-WakeupAllowed" SG_ 1385 HVEM_FreigabeKlimatisierung 0;
BA_ "GenSigSendType" SG_ 1385 HVEM_FreigabeKlimatisierung 3;
BA_ "NWM-WakeupAllowed" SG_ 1482 BMS_07_CRC 0;
BA_ "GenSigFuncType" SG_ 1482 BMS_07_CRC 2;
BA_ "NWM-WakeupAllowed" SG_ 1482 BMS_07_BZ 0;
BA_ "GenSigFuncType" SG_ 1482 BMS_07_BZ 1;
BA_ "Fehlerwert" SG_ 1482 BMS_Energieinhalt 2047;
BA_ "GenSigStartValue" SG_ 1482 BMS_Energieinhalt 2046;
BA_ "NWM-WakeupAllowed" SG_ 1482 BMS_Energieinhalt 0;
BA_ "NWM-WakeupAllowed" SG_ 1482 BMS_Ladevorgang_aktiv 0;
BA_ "Fehlerwert" SG_ 1482 BMS_MaxEnergieinhalt 2047;
BA_ "GenSigStartValue" SG_ 1482 BMS_MaxEnergieinhalt 2046;
BA_ "NWM-WakeupAllowed" SG_ 1482 BMS_MaxEnergieinhalt 0;
BA_ "NWM-WakeupAllowed" SG_ 1482 BMS_Ausgleichsladung_Anf 0;
BA_ "NWM-WakeupAllowed" SG_ 1482 BMS_Gesamtst_Spgfreiheit 0;
BA_ "GenSigSendType" SG_ 1482 BMS_Gesamtst_Spgfreiheit 3;
BA_ "Fehlerwert" SG_ 1519 BMS_IstStrom 4095;
BA_ "GenSigStartValue" SG_ 1519 BMS_IstStrom 4094;
BA_ "NWM-WakeupAllowed" SG_ 1519 BMS_IstStrom 0;
BA_ "GenSigAutoGenDsp" SG_ 1519 BMS_IstStrom 1;
BA_ "GenSigAutoGenSnd" SG_ 1519 BMS_IstStrom 1;
BA_ "Fehlerwert" SG_ 1519 BMS_PTC_Stufe 15;
BA_ "GenSigStartValue" SG_ 1519 BMS_PTC_Stufe 14;
BA_ "NWM-WakeupAllowed" SG_ 1519 BMS_PTC_Stufe 0;
BA_ "GenSigAutoGenDsp" SG_ 1519 BMS_PTC_Stufe 1;
BA_ "GenSigAutoGenSnd" SG_ 1519 BMS_PTC_Stufe 1;
BA_ "Fehlerwert" SG_ 1519 BMS_PTC_IstStrom 255;
BA_ "GenSigStartValue" SG_ 1519 BMS_PTC_IstStrom 254;
BA_ "NWM-WakeupAllowed" SG_ 1519 BMS_PTC_IstStrom 0;
BA_ "GenSigAutoGenDsp" SG_ 1519 BMS_PTC_IstStrom 1;
BA_ "GenSigAutoGenSnd" SG_ 1519 BMS_PTC_IstStrom 1;
BA_ "Fehlerwert" SG_ 1519 BMS_Status_Kuehlung 15;
BA_ "GenSigStartValue" SG_ 1519 BMS_Status_Kuehlung 14;
BA_ "NWM-WakeupAllowed" SG_ 1519 BMS_Status_Kuehlung 0;
BA_ "Fehlerwert" SG_ 1519 BMS_Temp_Zelle_Min 255;
BA_ "GenSigStartValue" SG_ 1519 BMS_Temp_Zelle_Min 254;
BA_ "NWM-WakeupAllowed" SG_ 1519 BMS_Temp_Zelle_Min 0;
BA_ "Fehlerwert" SG_ 1519 BMS_Temp_Zelle_Max 255;
BA_ "GenSigStartValue" SG_ 1519 BMS_Temp_Zelle_Max 254;
BA_ "NWM-WakeupAllowed" SG_ 1519 BMS_Temp_Zelle_Max 0;
BA_ "Fehlerwert" SG_ 1519 BMS_Pumpendrehzahl 255;
BA_ "GenSigStartValue" SG_ 1519 BMS_Pumpendrehzahl 254;
BA_ "NWM-WakeupAllowed" SG_ 1519 BMS_Pumpendrehzahl 0;
BA_ "Fehlerwert" SG_ 1519 BMS_Status_3_2_Ventil1 7;
BA_ "GenSigStartValue" SG_ 1519 BMS_Status_3_2_Ventil1 6;
BA_ "NWM-WakeupAllowed" SG_ 1519 BMS_Status_3_2_Ventil1 0;
BA_ "Fehlerwert" SG_ 1519 BMS_Status_3_2_Ventil2 7;
BA_ "GenSigStartValue" SG_ 1519 BMS_Status_3_2_Ventil2 6;
BA_ "NWM-WakeupAllowed" SG_ 1519 BMS_Status_3_2_Ventil2 0;
BA_ "GenSigStartValue" SG_ 1438 BMS_Temperierung_Anf 3;
BA_ "NWM-WakeupAllowed" SG_ 1438 BMS_Temperierung_Anf 0;
BA_ "GenSigStartValue" SG_ 1438 BMS_Soll_PWM_Pumpe 15;
BA_ "NWM-WakeupAllowed" SG_ 1438 BMS_Soll_PWM_Pumpe 0;
BA_ "Fehlerwert" SG_ 1438 BMS_Temperatur 255;
BA_ "GenSigStartValue" SG_ 1438 BMS_Temperatur 254;
BA_ "NWM-WakeupAllowed" SG_ 1438 BMS_Temperatur 0;
BA_ "Fehlerwert" SG_ 1438 BMS_IstVorlaufTemperatur 255;
BA_ "GenSigStartValue" SG_ 1438 BMS_IstVorlaufTemperatur 254;
BA_ "NWM-WakeupAllowed" SG_ 1438 BMS_IstVorlaufTemperatur 0;
BA_ "Fehlerwert" SG_ 1438 BMS_SollVolumenstrom 63;
BA_ "GenSigStartValue" SG_ 1438 BMS_SollVolumenstrom 62;
BA_ "NWM-WakeupAllowed" SG_ 1438 BMS_SollVolumenstrom 0;
BA_ "Fehlerwert" SG_ 1438 BMS_SollVorlauftemperatur 255;
BA_ "GenSigStartValue" SG_ 1438 BMS_SollVorlauftemperatur 254;
BA_ "NWM-WakeupAllowed" SG_ 1438 BMS_SollVorlauftemperatur 0;
BA_ "Fehlerwert" SG_ 1438 BMS_IstRuecklaufTemperatur_02 255;
BA_ "GenSigStartValue" SG_ 1438 BMS_IstRuecklaufTemperatur_02 254;
BA_ "NWM-WakeupAllowed" SG_ 1438 BMS_IstRuecklaufTemperatur_02 0;
BA_ "GenSigStartValue" SG_ 1438 BMS_SollVorlaufTemp_Epsilon 15;
BA_ "NWM-WakeupAllowed" SG_ 1438 BMS_SollVorlaufTemp_Epsilon 0;
BA_ "NWM-WakeupAllowed" SG_ 1428 HVLM_HV_Anf 0;
BA_ "GenSigSendType" SG_ 1428 HVLM_HV_Anf 3;
BA_ "NWM-WakeupAllowed" SG_ 1428 HVLM_Stecker_Status 0;
BA_ "Fehlerwert" SG_ 1428 HVLM_Restladezeit_HV_Bat_02 511;
BA_ "GenSigStartValue" SG_ 1428 HVLM_Restladezeit_HV_Bat_02 510;
BA_ "NWM-WakeupAllowed" SG_ 1428 HVLM_Restladezeit_HV_Bat_02 0;
BA_ "NWM-WakeupAllowed" SG_ 1428 HVLM_Lademodus_HV_Bat 0;
BA_ "NWM-WakeupAllowed" SG_ 1428 HVLM_Bat_laden_aktiv 0;
BA_ "NWM-WakeupAllowed" SG_ 1428 HVLM_Ladeart 0;
BA_ "NWM-WakeupAllowed" SG_ 1428 HVLM_VK_Anf 0;
BA_ "NWM-WakeupAllowed" SG_ 1428 HVLM_Ladesystemhinweise 0;
BA_ "GenSigSendType" SG_ 1428 HVLM_Ladesystemhinweise 3;
BA_ "Fehlerwert" SG_ 1428 HVLM_Langzeit_Laden 3;
BA_ "NWM-WakeupAllowed" SG_ 1428 HVLM_Langzeit_Laden 0;
BA_ "Fehlerwert" SG_ 1428 HVLM_Klima_Temp 31;
BA_ "GenSigStartValue" SG_ 1428 HVLM_Klima_Temp 30;
BA_ "NWM-WakeupAllowed" SG_ 1428 HVLM_Klima_Temp 0;
BA_ "GenSigSendType" SG_ 1428 HVLM_Klima_Temp 3;
BA_ "Fehlerwert" SG_ 1428 HVLM_VK_Modus 3;
BA_ "NWM-WakeupAllowed" SG_ 1428 HVLM_VK_Modus 0;
BA_ "NWM-WakeupAllowed" SG_ 1428 HVLM_HSH_Anf 0;
BA_ "GenSigSendType" SG_ 24 WFS_MSG4_IMS 3;
BA_ "GenSigSendType" SG_ 25 WFS_IMS_MSG4 3;
BA_ "NWM-WakeupAllowed" SG_ 1603 KBI_Einheit_Verbrauch_elektr 0;
BA_ "GenSigSendType" SG_ 1603 KBI_Einheit_Verbrauch_elektr 3;
BA_ "GenSigSendType" SG_ 1603 KBI_Einheit_Datum 3;
BA_ "GenSigSendType" SG_ 1603 KBI_Einheit_Streckenanz 3;
BA_ "GenSigSendType" SG_ 1603 KBI_Einheit_Temp 3;
BA_ "Bemerkung" SG_ 1603 KBI_Einheit_Uhrzeit "Eingestelltes Zeitformat im Kombiinstrument.";
BA_ "GenSigSendType" SG_ 1603 KBI_Einheit_Uhrzeit 3;
BA_ "Fehlerwert" SG_ 1603 KBI_Einheit_Sprache 255;
BA_ "GenSigSendType" SG_ 1603 KBI_Einheit_Sprache 3;
BA_ "GenSigSendType" SG_ 1603 KBI_Einheit_Volumen 3;
BA_ "GenSigSendType" SG_ 1603 KBI_Einheit_Verbrauch 3;
BA_ "GenSigSendType" SG_ 1603 KBI_MFA_v_Einheit_02 3;
BA_ "GenSigSendType" SG_ 1603 KBI_Einheit_Druck 3;
BA_ "NWM-WakeupAllowed" SG_ 267 LS_Fehler 0;
BA_ "GenSigFuncType" SG_ 267 LS_01_CHK 3;
BA_ "GenSigFuncType" SG_ 267 LS_01_BZ 1;
BA_ "NWM-WakeupAllowed" SG_ 267 LS_Tip_Stufe_2 0;
BA_ "NWM-WakeupAllowed" SG_ 267 LS_GRA_ACC_2stufig 0;
BA_ "Fehlerwert" SG_ 260 EPB_Pedalweg_Kuppl 255;
BA_ "GenSigStartValue" SG_ 260 EPB_QBit_Schalterpos 1;
BA_ "Fehlerwert" SG_ 260 EPB_Spannkraft 31;
BA_ "GenSigStartValue" SG_ 260 EPB_Spannkraft 30;
BA_ "GenSigFuncType" SG_ 260 EPB_01_CHK 3;
BA_ "GenSigFuncType" SG_ 260 EPB_01_BZ 1;
BA_ "Bemerkung" SG_ 260 EPB_QBit_Laengsbeschleunigung "Signal wird im Panamera nicht unterstützt. Es wird konstant '1' (Ersatz-, Init- oder Fehlerwert) gesendet.";
BA_ "GenSigStartValue" SG_ 260 EPB_QBit_Laengsbeschleunigung 1;
BA_ "GenSigStartValue" SG_ 260 EPB_QBit_Pedalweg_Kuppl 1;
BA_ "Bemerkung" SG_ 260 EPB_BCM2_Motor_Wakeup "Signal wird im Panamera nicht unterstützt und konstant 0 (kein Nachwecken) gesendet.";
BA_ "GenSigStartValue" SG_ 260 EPB_Verzoeg_Anf 166;
BA_ "Bemerkung" SG_ 260 EPB_Laengsbeschleunigung "Signal wird im Panamera nicht unterstützt. Es wird konstant 255 (Fehlerwert) gesendet.";
BA_ "Fehlerwert" SG_ 260 EPB_Laengsbeschleunigung 255;
BA_ "NWM-WakeupAllowed" SG_ 64 AB_Deaktivierung_HV 0;
BA_ "GenSigStartValue" SG_ 64 AB_RGS_Anst 8;
BA_ "GenSigSendType" SG_ 64 AB_RGS_Anst 3;
BA_ "GenSigFuncType" SG_ 64 Airbag_01_CHK 3;
BA_ "GenSigFuncType" SG_ 64 Airbag_01_BZ 1;
BA_ "GenSigSendType" SG_ 64 AB_Front_Crash 3;
BA_ "GenSigSendType" SG_ 64 AB_Heck_Crash 3;
BA_ "GenSigSendType" SG_ 64 AB_SF_Crash 3;
BA_ "GenSigSendType" SG_ 64 AB_SB_Crash 3;
BA_ "GenSigSendType" SG_ 64 AB_Rollover_Crash 3;
BA_ "GenSigSendType" SG_ 64 AB_Crash_Int 3;
BA_ "GenSigStartValue" SG_ 64 AB_Lampe 1;
BA_ "GenSigStartValue" SG_ 64 AB_PAO_Leuchte_Anf 1;
BA_ "Bemerkung" SG_ 1312 AB_Gurtschloss_Reihe3_MI "Signal wird im Panamera nicht verwendet. Konstant mit '0' senden.";
BA_ "GenSigStartValue" SG_ 1312 AB_Gurtschloss_Reihe3_MI 1;
BA_ "GenSigSendType" SG_ 1312 AB_Gurtschloss_Reihe3_MI 3;
BA_ "Bemerkung" SG_ 1312 AB_Gurtschloss_Reihe3_FA "Signal wird im Panamera nicht verwendet. Konstant mit '0' senden.";
BA_ "GenSigStartValue" SG_ 1312 AB_Gurtschloss_Reihe3_FA 1;
BA_ "GenSigSendType" SG_ 1312 AB_Gurtschloss_Reihe3_FA 3;
BA_ "Bemerkung" SG_ 1312 AB_Gurtschloss_Reihe3_BF "Signal wird im Panamera nicht verwendet. Konstant mit '0' senden.";
BA_ "GenSigStartValue" SG_ 1312 AB_Gurtschloss_Reihe3_BF 1;
BA_ "GenSigSendType" SG_ 1312 AB_Gurtschloss_Reihe3_BF 3;
BA_ "GenSigStartValue" SG_ 1312 AB_Gurtschloss_Reihe2_BF 1;
BA_ "GenSigSendType" SG_ 1312 AB_Gurtschloss_Reihe2_BF 3;
BA_ "Bemerkung" SG_ 1312 AB_Gurtschloss_Reihe2_MI "Signal wird im Panamera nicht verwendet. Konstant mit '0' senden.";
BA_ "GenSigStartValue" SG_ 1312 AB_Gurtschloss_Reihe2_MI 1;
BA_ "GenSigSendType" SG_ 1312 AB_Gurtschloss_Reihe2_MI 3;
BA_ "GenSigStartValue" SG_ 1312 AB_Gurtschloss_Reihe2_FA 1;
BA_ "GenSigSendType" SG_ 1312 AB_Gurtschloss_Reihe2_FA 3;
BA_ "GenSigStartValue" SG_ 1312 AB_Gurtschloss_BF 1;
BA_ "GenSigSendType" SG_ 1312 AB_Gurtschloss_BF 3;
BA_ "GenSigStartValue" SG_ 1312 AB_Gurtschloss_FA 1;
BA_ "GenSigSendType" SG_ 1312 AB_Gurtschloss_FA 3;
BA_ "NWM-WakeupAllowed" SG_ 777 BEM_Segel_Info 0;
BA_ "GenSigFuncType" SG_ 777 BEM_01_CHK 3;
BA_ "GenSigFuncType" SG_ 777 BEM_01_BZ 1;
BA_ "GenSigStartValue" SG_ 1714 UH_Monat 1;
BA_ "GenSigStartValue" SG_ 1714 UH_Tag 1;
BA_ "GenSigStartValue" SG_ 1714 Kombi_02_alt 1;
BA_ "Fehlerwert" SG_ 1714 DGN_Verlernzaehler 255;
BA_ "Fehlerwert" SG_ 1714 KBI_Kilometerstand 1048575;
BA_ "GenSigStartValue" SG_ 1714 KBI_Kilometerstand 1048574;
BA_ "GenSigStartValue" SG_ 1714 Uhrzeit_01_alt 1;
BA_ "Bemerkung" SG_ 1313 STH_LED "0=keine Rueckmeldung; 1=Rueckmeldung Standheizung in Betrieb";
BA_ "Fehlerwert" SG_ 1313 STH_Wassertemp 255;
BA_ "GenSigStartValue" SG_ 1313 STH_Wassertemp 254;
BA_ "GenSigFuncType" SG_ 134 LWI_01_CHK 3;
BA_ "GenSigFuncType" SG_ 134 LWI_01_BZ 1;
BA_ "GenSigStartValue" SG_ 134 LWI_QBit_Lenkradwinkel 1;
BA_ "Fehlerwert" SG_ 134 LWI_Lenkradwinkel 8191;
BA_ "GenSigStartValue" SG_ 134 LWI_Lenkradwinkel 8188;
BA_ "GenSigStartValue" SG_ 134 LWI_Lenkradw_Geschw 510;
BA_ "GenSigFuncType" SG_ 134 LWI_01_CRC 2;
BA_ "GenSigFuncType" SG_ 1633 AAG_BZ 1;
BA_ "NWM-WakeupAllowed" SG_ 780 ACC_Wunschgeschw_erreicht 0;
BA_ "GenSigFuncType" SG_ 780 ACC_02_CHK 3;
BA_ "GenSigFuncType" SG_ 780 ACC_02_BZ 1;
BA_ "NWM-WakeupAllowed" SG_ 1743 NMH_EM_keine_HV_Entl 0;
BA_ "NWM-WakeupAllowed" SG_ 1743 NMH_EM_Start_1 0;
BA_ "GenSigSendType" SG_ 1743 NMH_EM_Start_1 7;
BA_ "NWM-WakeupAllowed" SG_ 1743 NMH_EM_Start_2 0;
BA_ "GenSigSendType" SG_ 1743 NMH_EM_Start_2 7;
BA_ "NWM-WakeupAllowed" SG_ 1743 NMH_EM_Normal_Mode_1 0;
BA_ "GenSigSendType" SG_ 1743 NMH_EM_Normal_Mode_1 7;
BA_ "NWM-WakeupAllowed" SG_ 1743 NMH_EM_Normal_Mode_2 0;
BA_ "GenSigSendType" SG_ 1743 NMH_EM_Normal_Mode_2 7;
BA_ "NWM-WakeupAllowed" SG_ 1743 NMH_EM_Car_WakeUp 0;
BA_ "GenSigSendType" SG_ 1743 NMH_EM_Car_WakeUp 7;
BA_ "GenSigSendType" SG_ 1743 NMH_EM_Per_WakeUp 7;
BA_ "GenSigSendType" SG_ 1743 NMH_EM_Fkt_WakeUp 7;
BA_ "NWM-WakeupAllowed" SG_ 1743 NMH_EM_Klemme_15 0;
BA_ "GenSigSendType" SG_ 1743 NMH_EM_Klemme_15 7;
BA_ "NWM-WakeupAllowed" SG_ 1743 NMH_EM_Diagnose 0;
BA_ "GenSigSendType" SG_ 1743 NMH_EM_Diagnose 7;
BA_ "NWM-WakeupAllowed" SG_ 1743 NMH_EM_MindestAktivZeit 0;
BA_ "GenSigSendType" SG_ 1743 NMH_EM_MindestAktivZeit 7;
BA_ "NWM-WakeupAllowed" SG_ 1743 NMH_EM_NL_Datem_EEPROM 0;
BA_ "GenSigSendType" SG_ 1743 NMH_EM_NL_Datem_EEPROM 7;
BA_ "NWM-WakeupAllowed" SG_ 1743 NMH_EM_Signalfehler 0;
BA_ "GenSigSendType" SG_ 1743 NMH_EM_Signalfehler 7;
BA_ "NWM-WakeupAllowed" SG_ 1743 NMH_EM_TimeOut_Fehler 0;
BA_ "GenSigSendType" SG_ 1743 NMH_EM_TimeOut_Fehler 7;
BA_ "NWM-WakeupAllowed" SG_ 1743 NMH_EM_CAN_Diag_deaktiv 0;
BA_ "GenSigSendType" SG_ 1743 NMH_EM_CAN_Diag_deaktiv 7;
BA_ "NWM-WakeupAllowed" SG_ 1743 NMH_EM_KompSchutz 0;
BA_ "GenSigSendType" SG_ 1743 NMH_EM_KompSchutz 7;
BA_ "NWM-WakeupAllowed" SG_ 1743 NMH_EM_Mute_Mode 0;
BA_ "GenSigSendType" SG_ 1743 NMH_EM_Mute_Mode 7;
BA_ "NWM-WakeupAllowed" SG_ 1743 NMH_EM_Transport_Mode 0;
BA_ "GenSigSendType" SG_ 1743 NMH_EM_Transport_Mode 7;
BA_ "NWM-WakeupAllowed" SG_ 1743 NMH_EM_Abschaltstufe_aktiv 0;
BA_ "GenSigSendType" SG_ 1743 NMH_EM_Abschaltstufe_aktiv 7;
BA_ "NWM-WakeupAllowed" SG_ 1743 NMH_EM_Busfehler 0;
BA_ "GenSigSendType" SG_ 1743 NMH_EM_Busfehler 7;
BA_ "NWM-WakeupAllowed" SG_ 1743 NMH_EM_Lokalaktiv 0;
BA_ "GenSigSendType" SG_ 1743 NMH_EM_Lokalaktiv 7;
BA_ "NWM-WakeupAllowed" SG_ 1743 NMH_EM_Subsystemaktiv 0;
BA_ "GenSigSendType" SG_ 1743 NMH_EM_Subsystemaktiv 7;
BA_ "GenSigFuncType" SG_ 786 TSK_03_CHK 4;
BA_ "GenSigFuncType" SG_ 786 TSK_03_BZ 1;
BA_ "GenSigSendType" SG_ 16 WFS_MSG1_IMS 3;
BA_REL_ "GenSigTimeoutTime" BU_SG_REL_ BMS_Hybrid SG_ 1445 OBC_CVN_VLD 5000;
BA_REL_ "GenSigTimeoutTime" BU_SG_REL_ BMS_Hybrid SG_ 1445 OBC_CALID_Index_01 5000;
BA_REL_ "GenSigTimeoutTime" BU_SG_REL_ BMS_Hybrid SG_ 1445 OBC_CALID_Index_05 5000;
BA_REL_ "GenSigTimeoutTime" BU_SG_REL_ BMS_Hybrid SG_ 1445 OBC_CALID_Index_09 5000;
BA_REL_ "GenSigTimeoutTime" BU_SG_REL_ BMS_Hybrid SG_ 1445 OBC_CALID_Index_13 5000;
BA_REL_ "GenSigTimeoutTime" BU_SG_REL_ BMS_Hybrid SG_ 1445 OBC_CALID_Index_02 5000;
BA_REL_ "GenSigTimeoutTime" BU_SG_REL_ BMS_Hybrid SG_ 1445 OBC_CALID_Index_06 5000;
BA_REL_ "GenSigTimeoutTime" BU_SG_REL_ BMS_Hybrid SG_ 1445 OBC_CALID_Index_10 5000;
BA_REL_ "GenSigTimeoutTime" BU_SG_REL_ BMS_Hybrid SG_ 1445 OBC_CALID_Index_14 5000;
BA_REL_ "GenSigTimeoutTime" BU_SG_REL_ BMS_Hybrid SG_ 1445 OBC_CALID_Index_03 5000;
BA_REL_ "GenSigTimeoutTime" BU_SG_REL_ BMS_Hybrid SG_ 1445 OBC_CALID_Index_07 5000;
BA_REL_ "GenSigTimeoutTime" BU_SG_REL_ BMS_Hybrid SG_ 1445 OBC_CALID_Index_11 5000;
BA_REL_ "GenSigTimeoutTime" BU_SG_REL_ BMS_Hybrid SG_ 1445 OBC_CALID_Index_15 5000;
BA_REL_ "GenSigTimeoutTime" BU_SG_REL_ BMS_Hybrid SG_ 1445 OBC_CALID_Index_04 5000;
BA_REL_ "GenSigTimeoutTime" BU_SG_REL_ BMS_Hybrid SG_ 1445 OBC_CALID_Index_08 5000;
BA_REL_ "GenSigTimeoutTime" BU_SG_REL_ BMS_Hybrid SG_ 1445 OBC_CALID_Index_12 5000;
BA_REL_ "GenSigTimeoutTime" BU_SG_REL_ BMS_Hybrid SG_ 1445 OBC_CALID_Index_16 5000;
BA_REL_ "GenSigTimeoutTime" BU_SG_REL_ BMS_Hybrid SG_ 1445 OBC_CVN_Byte_1 5000;
BA_REL_ "GenSigTimeoutTime" BU_SG_REL_ BMS_Hybrid SG_ 1445 OBC_CVN_Byte_2 5000;
BA_REL_ "GenSigTimeoutTime" BU_SG_REL_ BMS_Hybrid SG_ 1445 OBC_CVN_Byte_3 5000;
BA_REL_ "GenSigTimeoutTime" BU_SG_REL_ BMS_Hybrid SG_ 1445 OBC_CALID_CVN_MUX 5000;
BA_REL_ "GenSigTimeoutTime" BU_SG_REL_ BMS_Hybrid SG_ 1445 OBC_CVN_Byte_4 5000;
BA_REL_ "GenSigTimeoutTime" BU_SG_REL_ Tool SG_ 2617239041 CCP_LE_DTO_01_Data 500;
BA_REL_ "GenSigTimeoutTime" BU_SG_REL_ GW_Routing_Derivate SG_ 1527 RW_Sekundaer_Reichweite 5000;
BA_REL_ "GenSigTimeoutTime" BU_SG_REL_ GW_Routing_Derivate SG_ 1527 RW_Sek_Reichweitenv_Einheit 5000;
BA_REL_ "GenSigTimeoutTime" BU_SG_REL_ GW_Routing_Derivate SG_ 1527 RW_Sek_Reichweitenverbrauch 5000;
BA_REL_ "GenSigTimeoutTime" BU_SG_REL_ GW_Routing_Derivate SG_ 1525 RW_RWDS_Lastprofil 5000;
BA_REL_ "GenSigTimeoutTime" BU_SG_REL_ GW_Routing_Derivate SG_ 1525 RW_Gesamt_Reichweite 5000;
BA_REL_ "GenSigTimeoutTime" BU_SG_REL_ GW_Routing_Derivate SG_ 1525 RW_Prim_Reichweitenverbrauch 5000;
BA_REL_ "GenSigTimeoutTime" BU_SG_REL_ GW_Routing_Derivate SG_ 1525 RW_Prim_Reichweitenv_Einheit 5000;
BA_REL_ "GenSigTimeoutTime" BU_SG_REL_ GW_Routing_Derivate SG_ 1525 RW_Primaer_Reichweite 5000;
BA_REL_ "GenSigTimeoutTime" BU_SG_REL_ GW_Routing_Derivate SG_ 687 BMS_Rekuperation 500;
BA_REL_ "GenSigTimeoutTime" BU_SG_REL_ GW_Routing_Derivate SG_ 687 BMS_Rekuperation_Ueberlauf 500;
BA_REL_ "GenSigTimeoutTime" BU_SG_REL_ GW_Routing_Derivate SG_ 687 BMS_Verbrauch 500;
BA_REL_ "GenSigTimeoutTime" BU_SG_REL_ GW_Routing_Derivate SG_ 687 BMS_Verbrauch_Ueberlauf 500;
BA_REL_ "GenSigTimeoutTime" BU_SG_REL_ BMS_Hybrid SG_ 1532 KL_Autobetrieb_HL 5000;
BA_REL_ "GenSigTimeoutTime" BU_SG_REL_ BMS_Hybrid SG_ 1532 KL_Autobetrieb_HR 5000;
BA_REL_ "GenSigTimeoutTime" BU_SG_REL_ BMS_Hybrid SG_ 1532 KL_Autobetrieb_VL 5000;
BA_REL_ "GenSigTimeoutTime" BU_SG_REL_ BMS_Hybrid SG_ 1532 KL_Autobetrieb_VR 5000;
BA_REL_ "GenSigTimeoutTime" BU_SG_REL_ BMS_Hybrid SG_ 1532 KL_Zieltemperatur_HL 5000;
BA_REL_ "GenSigTimeoutTime" BU_SG_REL_ BMS_Hybrid SG_ 1532 KL_Zieltemperatur_HR 5000;
BA_REL_ "GenSigTimeoutTime" BU_SG_REL_ BMS_Hybrid SG_ 1532 KL_Zieltemperatur_VL 5000;
BA_REL_ "GenSigTimeoutTime" BU_SG_REL_ BMS_Hybrid SG_ 1532 KL_Zieltemperatur_VR 5000;
BA_REL_ "GenSigTimeoutTime" BU_SG_REL_ Motor_MED17_Hybrid SG_ 1788 NMH_Ladegeraet_Start_1 2000;
BA_REL_ "GenSigTimeoutTime" BU_SG_REL_ GW_Applikation_Derivate SG_ 1788 NMH_Ladegeraet_Start_1 2000;
BA_REL_ "GenSigTimeoutTime" BU_SG_REL_ Getriebe_Derivate SG_ 1788 NMH_Ladegeraet_Start_1 2000;
BA_REL_ "GenSigTimeoutTime" BU_SG_REL_ LEH_Hybrid SG_ 1788 NMH_Ladegeraet_Start_1 2000;
BA_REL_ "GenSigTimeoutTime" BU_SG_REL_ BMS_Hybrid SG_ 1788 NMH_Ladegeraet_Start_1 2000;
BA_REL_ "GenSigTimeoutTime" BU_SG_REL_ Ladegeraet_PAG_PF SG_ 1860 ISO_Ladegeraet_Req_Data 500;
BA_REL_ "GenSigTimeoutTime" BU_SG_REL_ BMS_Hybrid SG_ 1483 PTC_Wassereinlasstemp 5000;
BA_REL_ "GenSigTimeoutTime" BU_SG_REL_ BMS_Hybrid SG_ 1483 PTC_Wasserauslasstemp 5000;
BA_REL_ "GenSigTimeoutTime" BU_SG_REL_ BMS_Hybrid SG_ 1483 PTC_HV_I_ist 5000;
BA_REL_ "GenSigTimeoutTime" BU_SG_REL_ Ladegeraet_PAG_PF SG_ 1483 PTC_HV_I_ist 5000;
BA_REL_ "GenSigTimeoutTime" BU_SG_REL_ BMS_Hybrid SG_ 1483 KBT_Defrost_aktiv 5000;
BA_REL_ "GenSigTimeoutTime" BU_SG_REL_ BMS_Hybrid SG_ 1483 KL_BattKond_WaPu_DZMax 5000;
BA_REL_ "GenSigTimeoutTime" BU_SG_REL_ Ladegeraet_PAG_PF SG_ 1483 KL_Standklima_Status 5000;
BA_REL_ "GenSigTimeoutTime" BU_SG_REL_ Ladegeraet_PAG_PF SG_ 1518 KL_T_STH 5000;
BA_REL_ "GenSigTimeoutTime" BU_SG_REL_ Ladegeraet_PAG_PF SG_ 1518 Klima_08_PAG_alt 5000;
BA_REL_ "GenSigTimeoutTime" BU_SG_REL_ GW_Applikation_Derivate SG_ 391 MO_HVEM_MaxLeistung 500;
BA_REL_ "GenSigTimeoutTime" BU_SG_REL_ Ladegeraet_PAG_PF SG_ 391 HV_Bordnetz_aktiv 1000;
BA_REL_ "GenSigTimeoutTime" BU_SG_REL_ GW_Applikation_Derivate SG_ 391 HV_Bordnetz_aktiv 500;
BA_REL_ "GenSigTimeoutTime" BU_SG_REL_ GW_Applikation_Derivate SG_ 391 MO_HVEM_Eskalation 500;
BA_REL_ "GenSigTimeoutTime" BU_SG_REL_ GW_Routing_Derivate SG_ 1662 LAD_02_CHK 5000;
BA_REL_ "GenSigTimeoutTime" BU_SG_REL_ GW_Routing_Derivate SG_ 1662 LAD_02_BZ 5000;
BA_REL_ "GenSigTimeoutTime" BU_SG_REL_ GW_Routing_Derivate SG_ 1662 LAD_Abregelung_Temperatur 5000;
BA_REL_ "GenSigTimeoutTime" BU_SG_REL_ GW_Routing_Derivate SG_ 1662 LAD_Abregelung_IU_Ein_Aus 5000;
BA_REL_ "GenSigTimeoutTime" BU_SG_REL_ GW_Routing_Derivate SG_ 1662 LAD_Abregelung_BuchseTemp 5000;
BA_REL_ "GenSigTimeoutTime" BU_SG_REL_ GW_Routing_Derivate SG_ 1662 LAD_MaxLadLeistung_HV 5000;
BA_REL_ "GenSigTimeoutTime" BU_SG_REL_ GW_Applikation_Derivate SG_ 1662 LAD_MaxLadLeistung_HV 5000;
BA_REL_ "GenSigTimeoutTime" BU_SG_REL_ GW_Routing_Derivate SG_ 1662 LAD_CP_Stromlimit 5000;
BA_REL_ "GenSigTimeoutTime" BU_SG_REL_ GW_Routing_Derivate SG_ 1662 LAD_PRX_Stromlimit 5000;
BA_REL_ "GenSigTimeoutTime" BU_SG_REL_ GW_Routing_Derivate SG_ 1662 LAD_CP_Erkennung 5000;
BA_REL_ "GenSigTimeoutTime" BU_SG_REL_ GW_Routing_Derivate SG_ 1662 LAD_Stecker_Verriegelt 5000;
BA_REL_ "GenSigTimeoutTime" BU_SG_REL_ GW_Routing_Derivate SG_ 1662 LAD_Stecker_Gesteckt 5000;
BA_REL_ "GenSigTimeoutTime" BU_SG_REL_ GW_Routing_Derivate SG_ 1662 LAD_Kuehlbedarf 5000;
BA_REL_ "GenSigTimeoutTime" BU_SG_REL_ GW_Routing_Derivate SG_ 1662 LAD_Warnzustand 5000;
BA_REL_ "GenSigTimeoutTime" BU_SG_REL_ GW_Routing_Derivate SG_ 1662 LAD_Fehlerzustand 5000;
BA_REL_ "GenSigTimeoutTime" BU_SG_REL_ GW_Routing_Derivate SG_ 1662 LAD_Fehlerstatus 5000;
BA_REL_ "GenSigTimeoutTime" BU_SG_REL_ GW_Routing_Derivate SG_ 1662 LAD_Warnlampe_Anf 5000;
BA_REL_ "GenSigTimeoutTime" BU_SG_REL_ GW_Routing_Derivate SG_ 1380 LAD_01_CHK 5000;
BA_REL_ "GenSigTimeoutTime" BU_SG_REL_ GW_Routing_Derivate SG_ 1380 LAD_01_BZ 5000;
BA_REL_ "GenSigTimeoutTime" BU_SG_REL_ GW_Applikation_Derivate SG_ 1380 LAD_IstModus 5000;
BA_REL_ "GenSigTimeoutTime" BU_SG_REL_ GW_Routing_Derivate SG_ 1380 LAD_IstModus 5000;
BA_REL_ "GenSigTimeoutTime" BU_SG_REL_ GW_Routing_Derivate SG_ 1380 LAD_AC_Istspannung 5000;
BA_REL_ "GenSigTimeoutTime" BU_SG_REL_ GW_Applikation_Derivate SG_ 1380 LAD_AC_Istspannung 5000;
BA_REL_ "GenSigTimeoutTime" BU_SG_REL_ GW_Routing_Derivate SG_ 1380 LAD_IstSpannung_HV 5000;
BA_REL_ "GenSigTimeoutTime" BU_SG_REL_ GW_Applikation_Derivate SG_ 1380 LAD_IstStrom_HV 5000;
BA_REL_ "GenSigTimeoutTime" BU_SG_REL_ GW_Routing_Derivate SG_ 1380 LAD_IstStrom_HV 5000;
BA_REL_ "GenSigTimeoutTime" BU_SG_REL_ GW_Routing_Derivate SG_ 1380 LAD_Status_Spgfreiheit 5000;
BA_REL_ "GenSigTimeoutTime" BU_SG_REL_ GW_Routing_Derivate SG_ 1380 LAD_Temperatur 5000;
BA_REL_ "GenSigTimeoutTime" BU_SG_REL_ GW_Routing_Derivate SG_ 1380 LAD_Verlustleistung 5000;
BA_REL_ "GenSigTimeoutTime" BU_SG_REL_ Ladegeraet_PAG_PF SG_ 1385 HVEM_Abschaltstatus 5000;
BA_REL_ "GenSigTimeoutTime" BU_SG_REL_ Motor_MED17_Hybrid SG_ 1385 HVEM_HV_Anf 5000;
BA_REL_ "GenSigTimeoutTime" BU_SG_REL_ Ladegeraet_PAG_PF SG_ 1385 HVEM_Nachladen_Anf 5000;
BA_REL_ "GenSigTimeoutTime" BU_SG_REL_ BMS_Hybrid SG_ 1385 HVEM_FreigabeKlimatisierung 5000;
BA_REL_ "GenSigTimeoutTime" BU_SG_REL_ GW_Routing_Derivate SG_ 1482 BMS_07_CRC 5000;
BA_REL_ "GenSigTimeoutTime" BU_SG_REL_ GW_Routing_Derivate SG_ 1482 BMS_07_BZ 5000;
BA_REL_ "GenSigTimeoutTime" BU_SG_REL_ GW_Routing_Derivate SG_ 1482 BMS_Energieinhalt 5000;
BA_REL_ "GenSigTimeoutTime" BU_SG_REL_ GW_Routing_Derivate SG_ 1482 BMS_Ladevorgang_aktiv 5000;
BA_REL_ "GenSigTimeoutTime" BU_SG_REL_ GW_Routing_Derivate SG_ 1482 BMS_MaxEnergieinhalt 5000;
BA_REL_ "GenSigTimeoutTime" BU_SG_REL_ GW_Routing_Derivate SG_ 1482 BMS_Ausgleichsladung_Anf 5000;
BA_REL_ "GenSigTimeoutTime" BU_SG_REL_ GW_Routing_Derivate SG_ 1482 BMS_Gesamtst_Spgfreiheit 5000;
BA_REL_ "GenSigTimeoutTime" BU_SG_REL_ GW_Applikation_Derivate SG_ 1519 BMS_IstStrom 5000;
BA_REL_ "GenSigTimeoutTime" BU_SG_REL_ GW_Routing_Derivate SG_ 1519 BMS_IstStrom 5000;
BA_REL_ "GenSigTimeoutTime" BU_SG_REL_ GW_Routing_Derivate SG_ 1519 BMS_PTC_Stufe 5000;
BA_REL_ "GenSigTimeoutTime" BU_SG_REL_ GW_Applikation_Derivate SG_ 1519 BMS_PTC_IstStrom 5000;
BA_REL_ "GenSigTimeoutTime" BU_SG_REL_ GW_Routing_Derivate SG_ 1519 BMS_PTC_IstStrom 5000;
BA_REL_ "GenSigTimeoutTime" BU_SG_REL_ GW_Routing_Derivate SG_ 1519 BMS_Status_Kuehlung 5000;
BA_REL_ "GenSigTimeoutTime" BU_SG_REL_ GW_Applikation_Derivate SG_ 1519 BMS_Status_Kuehlung 5000;
BA_REL_ "GenSigTimeoutTime" BU_SG_REL_ GW_Routing_Derivate SG_ 1519 BMS_Temp_Zelle_Min 5000;
BA_REL_ "GenSigTimeoutTime" BU_SG_REL_ GW_Routing_Derivate SG_ 1519 BMS_Temp_Zelle_Max 5000;
BA_REL_ "GenSigTimeoutTime" BU_SG_REL_ GW_Routing_Derivate SG_ 1519 BMS_Pumpendrehzahl 5000;
BA_REL_ "GenSigTimeoutTime" BU_SG_REL_ GW_Routing_Derivate SG_ 1519 BMS_Status_3_2_Ventil1 5000;
BA_REL_ "GenSigTimeoutTime" BU_SG_REL_ GW_Routing_Derivate SG_ 1519 BMS_Status_3_2_Ventil2 5000;
BA_REL_ "GenSigTimeoutTime" BU_SG_REL_ GW_Routing_Derivate SG_ 1438 BMS_Temperierung_Anf 5000;
BA_REL_ "GenSigTimeoutTime" BU_SG_REL_ GW_Routing_Derivate SG_ 1438 BMS_Soll_PWM_Pumpe 5000;
BA_REL_ "GenSigTimeoutTime" BU_SG_REL_ GW_Routing_Derivate SG_ 1438 BMS_Temperatur 5000;
BA_REL_ "GenSigTimeoutTime" BU_SG_REL_ GW_Routing_Derivate SG_ 1438 BMS_IstVorlaufTemperatur 5000;
BA_REL_ "GenSigTimeoutTime" BU_SG_REL_ GW_Routing_Derivate SG_ 1438 BMS_SollVolumenstrom 5000;
BA_REL_ "GenSigTimeoutTime" BU_SG_REL_ GW_Routing_Derivate SG_ 1438 BMS_SollVorlauftemperatur 5000;
BA_REL_ "GenSigTimeoutTime" BU_SG_REL_ GW_Routing_Derivate SG_ 1438 BMS_IstRuecklaufTemperatur_02 5000;
BA_REL_ "GenSigTimeoutTime" BU_SG_REL_ GW_Routing_Derivate SG_ 1438 BMS_SollVorlaufTemp_Epsilon 5000;
BA_REL_ "GenSigTimeoutTime" BU_SG_REL_ GW_Applikation_Derivate SG_ 1428 HVLM_HV_Anf 5000;
BA_REL_ "GenSigTimeoutTime" BU_SG_REL_ GW_Routing_Derivate SG_ 1428 HVLM_HV_Anf 5000;
BA_REL_ "GenSigTimeoutTime" BU_SG_REL_ GW_Applikation_Derivate SG_ 1428 HVLM_Stecker_Status 5000;
BA_REL_ "GenSigTimeoutTime" BU_SG_REL_ BMS_Hybrid SG_ 1428 HVLM_Stecker_Status 500;
BA_REL_ "GenSigTimeoutTime" BU_SG_REL_ GW_Routing_Derivate SG_ 1428 HVLM_Stecker_Status 5000;
BA_REL_ "GenSigTimeoutTime" BU_SG_REL_ GW_Routing_Derivate SG_ 1428 HVLM_Restladezeit_HV_Bat_02 5000;
BA_REL_ "GenSigTimeoutTime" BU_SG_REL_ GW_Routing_Derivate SG_ 1428 HVLM_Lademodus_HV_Bat 5000;
BA_REL_ "GenSigTimeoutTime" BU_SG_REL_ GW_Applikation_Derivate SG_ 1428 HVLM_Bat_laden_aktiv 5000;
BA_REL_ "GenSigTimeoutTime" BU_SG_REL_ GW_Routing_Derivate SG_ 1428 HVLM_Bat_laden_aktiv 5000;
BA_REL_ "GenSigTimeoutTime" BU_SG_REL_ GW_Routing_Derivate SG_ 1428 HVLM_Ladeart 5000;
BA_REL_ "GenSigTimeoutTime" BU_SG_REL_ GW_Applikation_Derivate SG_ 1428 HVLM_VK_Anf 5000;
BA_REL_ "GenSigTimeoutTime" BU_SG_REL_ GW_Routing_Derivate SG_ 1428 HVLM_VK_Anf 5000;
BA_REL_ "GenSigTimeoutTime" BU_SG_REL_ GW_Routing_Derivate SG_ 1428 HVLM_Ladesystemhinweise 5000;
BA_REL_ "GenSigTimeoutTime" BU_SG_REL_ GW_Routing_Derivate SG_ 1428 HVLM_Langzeit_Laden 5000;
BA_REL_ "GenSigTimeoutTime" BU_SG_REL_ BMS_Hybrid SG_ 1428 HVLM_Langzeit_Laden 500;
BA_REL_ "GenSigTimeoutTime" BU_SG_REL_ GW_Routing_Derivate SG_ 1428 HVLM_Klima_Temp 5000;
BA_REL_ "GenSigTimeoutTime" BU_SG_REL_ GW_Routing_Derivate SG_ 1428 HVLM_VK_Modus 5000;
BA_REL_ "GenSigTimeoutTime" BU_SG_REL_ GW_Routing_Derivate SG_ 1428 HVLM_HSH_Anf 5000;
BA_REL_ "GenSigTimeoutTime" BU_SG_REL_ GW_Routing_Derivate SG_ 24 WFS_MSG4_IMS 500;
BA_REL_ "GenSigTimeoutTime" BU_SG_REL_ LEH_Hybrid SG_ 25 WFS_IMS_MSG4 500;
BA_REL_ "GenSigTimeoutTime" BU_SG_REL_ Motor_EDC17_Pirol SG_ 1603 KBI_Einheit_Streckenanz 5000;
BA_REL_ "GenSigTimeoutTime" BU_SG_REL_ Getriebe_Derivate SG_ 267 MFL_Tip_Up 1000;
BA_REL_ "GenSigTimeoutTime" BU_SG_REL_ Getriebe_Derivate SG_ 267 MFL_Tip_Down 1000;
BA_REL_ "GenSigTimeoutTime" BU_SG_REL_ Motor_EDC17_Pirol SG_ 267 LS_Typ_Hauptschalter 1000;
BA_REL_ "GenSigTimeoutTime" BU_SG_REL_ Motor_MED17_Hybrid SG_ 267 LS_Typ_Hauptschalter 1000;
BA_REL_ "GenSigTimeoutTime" BU_SG_REL_ Getriebe_Derivate SG_ 267 LS_Tiptronic_Fehler 1000;
BA_REL_ "GenSigTimeoutTime" BU_SG_REL_ Motor_EDC17_Pirol SG_ 267 LS_Tip_Wiederaufnahme 1000;
BA_REL_ "GenSigTimeoutTime" BU_SG_REL_ Motor_MED17_Hybrid SG_ 267 LS_Tip_Wiederaufnahme 1000;
BA_REL_ "GenSigTimeoutTime" BU_SG_REL_ Motor_EDC17_Pirol SG_ 267 LS_Tip_Setzen 1000;
BA_REL_ "GenSigTimeoutTime" BU_SG_REL_ Motor_MED17_Hybrid SG_ 267 LS_Tip_Setzen 1000;
BA_REL_ "GenSigTimeoutTime" BU_SG_REL_ Motor_EDC17_Pirol SG_ 267 LS_Tip_Runter 1000;
BA_REL_ "GenSigTimeoutTime" BU_SG_REL_ Motor_MED17_Hybrid SG_ 267 LS_Tip_Runter 1000;
BA_REL_ "GenSigTimeoutTime" BU_SG_REL_ Motor_EDC17_Pirol SG_ 267 LS_Tip_Hoch 1000;
BA_REL_ "GenSigTimeoutTime" BU_SG_REL_ Motor_MED17_Hybrid SG_ 267 LS_Tip_Hoch 1000;
BA_REL_ "GenSigTimeoutTime" BU_SG_REL_ Motor_EDC17_Pirol SG_ 267 LS_Limiter 1000;
BA_REL_ "GenSigTimeoutTime" BU_SG_REL_ Motor_MED17_Hybrid SG_ 267 LS_Limiter 1000;
BA_REL_ "GenSigTimeoutTime" BU_SG_REL_ Motor_EDC17_Pirol SG_ 267 LS_Hauptschalter 1000;
BA_REL_ "GenSigTimeoutTime" BU_SG_REL_ Motor_MED17_Hybrid SG_ 267 LS_Hauptschalter 1000;
BA_REL_ "GenSigTimeoutTime" BU_SG_REL_ Motor_EDC17_Pirol SG_ 267 LS_Fehler 1000;
BA_REL_ "GenSigTimeoutTime" BU_SG_REL_ Motor_MED17_Hybrid SG_ 267 LS_Fehler 1000;
BA_REL_ "GenSigTimeoutTime" BU_SG_REL_ Motor_EDC17_Pirol SG_ 267 LS_Codierung 1000;
BA_REL_ "GenSigTimeoutTime" BU_SG_REL_ Motor_MED17_Hybrid SG_ 267 LS_Codierung 1000;
BA_REL_ "GenSigTimeoutTime" BU_SG_REL_ Motor_EDC17_Pirol SG_ 267 LS_Abbrechen 1000;
BA_REL_ "GenSigTimeoutTime" BU_SG_REL_ Motor_MED17_Hybrid SG_ 267 LS_Abbrechen 1000;
BA_REL_ "GenSigTimeoutTime" BU_SG_REL_ Motor_EDC17_Pirol SG_ 267 LS_01_CHK 1000;
BA_REL_ "GenSigTimeoutTime" BU_SG_REL_ Motor_MED17_Hybrid SG_ 267 LS_01_CHK 1000;
BA_REL_ "GenSigTimeoutTime" BU_SG_REL_ Getriebe_Derivate SG_ 267 LS_01_CHK 1000;
BA_REL_ "GenSigTimeoutTime" BU_SG_REL_ Motor_EDC17_Pirol SG_ 267 LS_01_BZ 1000;
BA_REL_ "GenSigTimeoutTime" BU_SG_REL_ Motor_MED17_Hybrid SG_ 267 LS_01_BZ 1000;
BA_REL_ "GenSigTimeoutTime" BU_SG_REL_ Getriebe_Derivate SG_ 267 LS_01_BZ 1000;
BA_REL_ "GenSigTimeoutTime" BU_SG_REL_ Getriebe_Derivate SG_ 267 MFL_M_Taste 1000;
BA_REL_ "GenSigTimeoutTime" BU_SG_REL_ Motor_EDC17_Pirol SG_ 267 LS_Tip_Stufe_2 1000;
BA_REL_ "GenSigTimeoutTime" BU_SG_REL_ Motor_MED17_Hybrid SG_ 267 LS_Tip_Stufe_2 1000;
BA_REL_ "GenSigTimeoutTime" BU_SG_REL_ Motor_EDC17_Pirol SG_ 267 LS_GRA_ACC_2stufig 1000;
BA_REL_ "GenSigTimeoutTime" BU_SG_REL_ Motor_MED17_Hybrid SG_ 267 LS_GRA_ACC_2stufig 1000;
BA_REL_ "GenSigTimeoutTime" BU_SG_REL_ Motor_EDC17_Pirol SG_ 260 EPB_Pedalweg_Kuppl 500;
BA_REL_ "GenSigTimeoutTime" BU_SG_REL_ Motor_MED17_Hybrid SG_ 260 EPB_Pedalweg_Kuppl 500;
BA_REL_ "GenSigTimeoutTime" BU_SG_REL_ Motor_MED17_Hybrid SG_ 260 EPB_Fehlerstatus 500;
BA_REL_ "GenSigTimeoutTime" BU_SG_REL_ Motor_EDC17_Pirol SG_ 260 EPB_Schalterposition 500;
BA_REL_ "GenSigTimeoutTime" BU_SG_REL_ Motor_MED17_Hybrid SG_ 260 EPB_Schalterposition 500;
BA_REL_ "GenSigTimeoutTime" BU_SG_REL_ Motor_EDC17_Pirol SG_ 260 EPB_QBit_Schalterpos 500;
BA_REL_ "GenSigTimeoutTime" BU_SG_REL_ Motor_MED17_Hybrid SG_ 260 EPB_QBit_Schalterpos 500;
BA_REL_ "GenSigTimeoutTime" BU_SG_REL_ Motor_EDC17_Pirol SG_ 260 EPB_Status 500;
BA_REL_ "GenSigTimeoutTime" BU_SG_REL_ Getriebe_Derivate SG_ 260 EPB_Status 500;
BA_REL_ "GenSigTimeoutTime" BU_SG_REL_ Motor_MED17_Hybrid SG_ 260 EPB_Status 500;
BA_REL_ "GenSigTimeoutTime" BU_SG_REL_ Getriebe_Derivate SG_ 260 EPB_01_CHK 500;
BA_REL_ "GenSigTimeoutTime" BU_SG_REL_ Motor_EDC17_Pirol SG_ 260 EPB_01_CHK 500;
BA_REL_ "GenSigTimeoutTime" BU_SG_REL_ Motor_MED17_Hybrid SG_ 260 EPB_01_CHK 500;
BA_REL_ "GenSigTimeoutTime" BU_SG_REL_ Getriebe_Derivate SG_ 260 EPB_01_BZ 500;
BA_REL_ "GenSigTimeoutTime" BU_SG_REL_ Motor_EDC17_Pirol SG_ 260 EPB_01_BZ 500;
BA_REL_ "GenSigTimeoutTime" BU_SG_REL_ Motor_MED17_Hybrid SG_ 260 EPB_01_BZ 500;
BA_REL_ "GenSigTimeoutTime" BU_SG_REL_ Motor_EDC17_Pirol SG_ 260 EPB_QBit_Pedalweg_Kuppl 500;
BA_REL_ "GenSigTimeoutTime" BU_SG_REL_ Motor_MED17_Hybrid SG_ 260 EPB_QBit_Pedalweg_Kuppl 500;
BA_REL_ "GenSigTimeoutTime" BU_SG_REL_ Motor_EDC17_Pirol SG_ 260 EPB_Freig_Verzoeg_Anf 500;
BA_REL_ "GenSigTimeoutTime" BU_SG_REL_ Motor_MED17_Hybrid SG_ 260 EPB_Freig_Verzoeg_Anf 500;
BA_REL_ "GenSigTimeoutTime" BU_SG_REL_ GW_Routing_Derivate SG_ 64 AB_Deaktivierung_HV 500;
BA_REL_ "GenSigTimeoutTime" BU_SG_REL_ GW_Routing_Derivate SG_ 64 AB_RGS_Anst 500;
BA_REL_ "GenSigTimeoutTime" BU_SG_REL_ GW_Routing_Derivate SG_ 64 AB_Texte_AKS 500;
BA_REL_ "GenSigTimeoutTime" BU_SG_REL_ GW_Routing_Derivate SG_ 64 Airbag_01_CHK 500;
BA_REL_ "GenSigTimeoutTime" BU_SG_REL_ Motor_EDC17_Pirol SG_ 64 Airbag_01_CHK 500;
BA_REL_ "GenSigTimeoutTime" BU_SG_REL_ Getriebe_Derivate SG_ 64 Airbag_01_CHK 500;
BA_REL_ "GenSigTimeoutTime" BU_SG_REL_ Motor_MED17_Hybrid SG_ 64 Airbag_01_CHK 500;
BA_REL_ "GenSigTimeoutTime" BU_SG_REL_ LEH_Hybrid SG_ 64 Airbag_01_CHK 500;
BA_REL_ "GenSigTimeoutTime" BU_SG_REL_ BMS_Hybrid SG_ 64 Airbag_01_CHK 500;
BA_REL_ "GenSigTimeoutTime" BU_SG_REL_ GW_Routing_Derivate SG_ 64 Airbag_01_BZ 500;
BA_REL_ "GenSigTimeoutTime" BU_SG_REL_ Motor_EDC17_Pirol SG_ 64 Airbag_01_BZ 500;
BA_REL_ "GenSigTimeoutTime" BU_SG_REL_ Getriebe_Derivate SG_ 64 Airbag_01_BZ 500;
BA_REL_ "GenSigTimeoutTime" BU_SG_REL_ Motor_MED17_Hybrid SG_ 64 Airbag_01_BZ 500;
BA_REL_ "GenSigTimeoutTime" BU_SG_REL_ LEH_Hybrid SG_ 64 Airbag_01_BZ 500;
BA_REL_ "GenSigTimeoutTime" BU_SG_REL_ BMS_Hybrid SG_ 64 Airbag_01_BZ 500;
BA_REL_ "GenSigTimeoutTime" BU_SG_REL_ GW_Routing_Derivate SG_ 64 AB_Front_Crash 500;
BA_REL_ "GenSigTimeoutTime" BU_SG_REL_ GW_Applikation_Derivate SG_ 64 AB_Front_Crash 500;
BA_REL_ "GenSigTimeoutTime" BU_SG_REL_ GW_Routing_Derivate SG_ 64 AB_Heck_Crash 500;
BA_REL_ "GenSigTimeoutTime" BU_SG_REL_ GW_Applikation_Derivate SG_ 64 AB_Heck_Crash 500;
BA_REL_ "GenSigTimeoutTime" BU_SG_REL_ GW_Routing_Derivate SG_ 64 AB_SF_Crash 500;
BA_REL_ "GenSigTimeoutTime" BU_SG_REL_ GW_Applikation_Derivate SG_ 64 AB_SF_Crash 500;
BA_REL_ "GenSigTimeoutTime" BU_SG_REL_ GW_Routing_Derivate SG_ 64 AB_SB_Crash 500;
BA_REL_ "GenSigTimeoutTime" BU_SG_REL_ GW_Applikation_Derivate SG_ 64 AB_SB_Crash 500;
BA_REL_ "GenSigTimeoutTime" BU_SG_REL_ GW_Routing_Derivate SG_ 64 AB_Rollover_Crash 500;
BA_REL_ "GenSigTimeoutTime" BU_SG_REL_ GW_Applikation_Derivate SG_ 64 AB_Rollover_Crash 500;
BA_REL_ "GenSigTimeoutTime" BU_SG_REL_ GW_Routing_Derivate SG_ 64 AB_Crash_Int 500;
BA_REL_ "GenSigTimeoutTime" BU_SG_REL_ Motor_EDC17_Pirol SG_ 64 AB_Crash_Int 500;
BA_REL_ "GenSigTimeoutTime" BU_SG_REL_ Getriebe_Derivate SG_ 64 AB_Crash_Int 500;
BA_REL_ "GenSigTimeoutTime" BU_SG_REL_ Motor_MED17_Hybrid SG_ 64 AB_Crash_Int 500;
BA_REL_ "GenSigTimeoutTime" BU_SG_REL_ LEH_Hybrid SG_ 64 AB_Crash_Int 500;
BA_REL_ "GenSigTimeoutTime" BU_SG_REL_ BMS_Hybrid SG_ 64 AB_Crash_Int 500;
BA_REL_ "GenSigTimeoutTime" BU_SG_REL_ GW_Routing_Derivate SG_ 64 AB_Lampe 500;
BA_REL_ "GenSigTimeoutTime" BU_SG_REL_ GW_Routing_Derivate SG_ 64 AB_Deaktiviert 500;
BA_REL_ "GenSigTimeoutTime" BU_SG_REL_ GW_Routing_Derivate SG_ 64 AB_VB_deaktiviert 500;
BA_REL_ "GenSigTimeoutTime" BU_SG_REL_ GW_Routing_Derivate SG_ 64 AB_Systemfehler 500;
BA_REL_ "GenSigTimeoutTime" BU_SG_REL_ LEH_Hybrid SG_ 64 AB_Systemfehler 500;
BA_REL_ "GenSigTimeoutTime" BU_SG_REL_ BMS_Hybrid SG_ 64 AB_Systemfehler 500;
BA_REL_ "GenSigTimeoutTime" BU_SG_REL_ GW_Routing_Derivate SG_ 64 AB_Diagnose 500;
BA_REL_ "GenSigTimeoutTime" BU_SG_REL_ GW_Routing_Derivate SG_ 64 AB_Anzeige_Fussg 500;
BA_REL_ "GenSigTimeoutTime" BU_SG_REL_ GW_Routing_Derivate SG_ 64 AB_PAO_Leuchte_Anf 500;
BA_REL_ "GenSigTimeoutTime" BU_SG_REL_ LEH_Hybrid SG_ 64 AB_Stellgliedtest 500;
BA_REL_ "GenSigTimeoutTime" BU_SG_REL_ GW_Routing_Derivate SG_ 64 AB_Stellgliedtest 500;
BA_REL_ "GenSigTimeoutTime" BU_SG_REL_ Motor_EDC17_Pirol SG_ 64 AB_Stellgliedtest 500;
BA_REL_ "GenSigTimeoutTime" BU_SG_REL_ BMS_Hybrid SG_ 64 AB_Stellgliedtest 500;
BA_REL_ "GenSigTimeoutTime" BU_SG_REL_ Motor_MED17_Hybrid SG_ 64 AB_Stellgliedtest 500;
BA_REL_ "GenSigTimeoutTime" BU_SG_REL_ GW_Routing_Derivate SG_ 64 AB_Erh_Auf_VB 500;
BA_REL_ "GenSigTimeoutTime" BU_SG_REL_ GW_Routing_Derivate SG_ 64 AB_Gurtwarn_VF 500;
BA_REL_ "GenSigTimeoutTime" BU_SG_REL_ GW_Routing_Derivate SG_ 64 AB_Gurtwarn_VB 500;
BA_REL_ "GenSigTimeoutTime" BU_SG_REL_ GW_Routing_Derivate SG_ 64 void_Byte_02 500;
BA_REL_ "GenSigTimeoutTime" BU_SG_REL_ GW_Routing_Derivate SG_ 64 void_Byte_03 500;
BA_REL_ "GenSigTimeoutTime" BU_SG_REL_ GW_Routing_Derivate SG_ 64 AB_KD_Fehler 500;
BA_REL_ "GenSigTimeoutTime" BU_SG_REL_ GW_Applikation_Derivate SG_ 64 AB_KD_Fehler 500;
BA_REL_ "GenSigTimeoutTime" BU_SG_REL_ GW_Routing_Derivate SG_ 1312 AB_Gurtschloss_FA 2000;
BA_REL_ "GenSigTimeoutTime" BU_SG_REL_ Motor_EDC17_Pirol SG_ 1312 AB_Gurtschloss_FA 2000;
BA_REL_ "GenSigTimeoutTime" BU_SG_REL_ Motor_MED17_Hybrid SG_ 1312 AB_Gurtschloss_FA 2000;
BA_REL_ "GenSigTimeoutTime" BU_SG_REL_ Motor_EDC17_Pirol SG_ 777 BEM_01_CHK 500;
BA_REL_ "GenSigTimeoutTime" BU_SG_REL_ Motor_MED17_Hybrid SG_ 777 BEM_01_CHK 500;
BA_REL_ "GenSigTimeoutTime" BU_SG_REL_ Motor_EDC17_Pirol SG_ 777 BEM_01_BZ 500;
BA_REL_ "GenSigTimeoutTime" BU_SG_REL_ Motor_MED17_Hybrid SG_ 777 BEM_01_BZ 500;
BA_REL_ "GenSigTimeoutTime" BU_SG_REL_ Motor_EDC17_Pirol SG_ 777 BEM_P_Generator 500;
BA_REL_ "GenSigTimeoutTime" BU_SG_REL_ Motor_EDC17_Pirol SG_ 777 BEM_n_LLA 500;
BA_REL_ "GenSigTimeoutTime" BU_SG_REL_ Motor_EDC17_Pirol SG_ 777 BEM_Anf_KL 500;
BA_REL_ "GenSigTimeoutTime" BU_SG_REL_ Motor_MED17_Hybrid SG_ 777 BEM_Anf_KL 500;
BA_REL_ "GenSigTimeoutTime" BU_SG_REL_ Motor_EDC17_Pirol SG_ 777 BEM_StartStopp_Info 500;
BA_REL_ "GenSigTimeoutTime" BU_SG_REL_ Motor_MED17_Hybrid SG_ 777 BEM_StartStopp_Info 500;
BA_REL_ "GenSigTimeoutTime" BU_SG_REL_ Ladegeraet_PAG_PF SG_ 1714 UH_Jahr 5000;
BA_REL_ "GenSigTimeoutTime" BU_SG_REL_ Motor_EDC17_Pirol SG_ 1714 UH_Jahr 5000;
BA_REL_ "GenSigTimeoutTime" BU_SG_REL_ PSM_Ant_Derivate SG_ 1714 UH_Jahr 5000;
BA_REL_ "GenSigTimeoutTime" BU_SG_REL_ Waehlhebel SG_ 1714 UH_Jahr 5000;
BA_REL_ "GenSigTimeoutTime" BU_SG_REL_ Motor_MED17_Hybrid SG_ 1714 UH_Jahr 5000;
BA_REL_ "GenSigTimeoutTime" BU_SG_REL_ LEH_Hybrid SG_ 1714 UH_Jahr 5000;
BA_REL_ "GenSigTimeoutTime" BU_SG_REL_ Getriebe_Derivate SG_ 1714 UH_Jahr 5000;
BA_REL_ "GenSigTimeoutTime" BU_SG_REL_ BMS_Hybrid SG_ 1714 UH_Jahr 5000;
BA_REL_ "GenSigTimeoutTime" BU_SG_REL_ Airbag SG_ 1714 UH_Jahr 5000;
BA_REL_ "GenSigTimeoutTime" BU_SG_REL_ Ladegeraet_PAG_PF SG_ 1714 UH_Monat 5000;
BA_REL_ "GenSigTimeoutTime" BU_SG_REL_ Motor_EDC17_Pirol SG_ 1714 UH_Monat 5000;
BA_REL_ "GenSigTimeoutTime" BU_SG_REL_ PSM_Ant_Derivate SG_ 1714 UH_Monat 5000;
BA_REL_ "GenSigTimeoutTime" BU_SG_REL_ Waehlhebel SG_ 1714 UH_Monat 5000;
BA_REL_ "GenSigTimeoutTime" BU_SG_REL_ Getriebe_Derivate SG_ 1714 UH_Monat 5000;
BA_REL_ "GenSigTimeoutTime" BU_SG_REL_ Motor_MED17_Hybrid SG_ 1714 UH_Monat 5000;
BA_REL_ "GenSigTimeoutTime" BU_SG_REL_ LEH_Hybrid SG_ 1714 UH_Monat 5000;
BA_REL_ "GenSigTimeoutTime" BU_SG_REL_ BMS_Hybrid SG_ 1714 UH_Monat 5000;
BA_REL_ "GenSigTimeoutTime" BU_SG_REL_ Airbag SG_ 1714 UH_Monat 5000;
BA_REL_ "GenSigTimeoutTime" BU_SG_REL_ Ladegeraet_PAG_PF SG_ 1714 UH_Tag 5000;
BA_REL_ "GenSigTimeoutTime" BU_SG_REL_ Motor_EDC17_Pirol SG_ 1714 UH_Tag 5000;
BA_REL_ "GenSigTimeoutTime" BU_SG_REL_ PSM_Ant_Derivate SG_ 1714 UH_Tag 5000;
BA_REL_ "GenSigTimeoutTime" BU_SG_REL_ Waehlhebel SG_ 1714 UH_Tag 5000;
BA_REL_ "GenSigTimeoutTime" BU_SG_REL_ Getriebe_Derivate SG_ 1714 UH_Tag 5000;
BA_REL_ "GenSigTimeoutTime" BU_SG_REL_ Motor_MED17_Hybrid SG_ 1714 UH_Tag 5000;
BA_REL_ "GenSigTimeoutTime" BU_SG_REL_ LEH_Hybrid SG_ 1714 UH_Tag 5000;
BA_REL_ "GenSigTimeoutTime" BU_SG_REL_ BMS_Hybrid SG_ 1714 UH_Tag 5000;
BA_REL_ "GenSigTimeoutTime" BU_SG_REL_ Airbag SG_ 1714 UH_Tag 5000;
BA_REL_ "GenSigTimeoutTime" BU_SG_REL_ Ladegeraet_PAG_PF SG_ 1714 UH_Stunde 5000;
BA_REL_ "GenSigTimeoutTime" BU_SG_REL_ Motor_EDC17_Pirol SG_ 1714 UH_Stunde 5000;
BA_REL_ "GenSigTimeoutTime" BU_SG_REL_ PSM_Ant_Derivate SG_ 1714 UH_Stunde 5000;
BA_REL_ "GenSigTimeoutTime" BU_SG_REL_ Waehlhebel SG_ 1714 UH_Stunde 5000;
BA_REL_ "GenSigTimeoutTime" BU_SG_REL_ Getriebe_Derivate SG_ 1714 UH_Stunde 5000;
BA_REL_ "GenSigTimeoutTime" BU_SG_REL_ Motor_MED17_Hybrid SG_ 1714 UH_Stunde 5000;
BA_REL_ "GenSigTimeoutTime" BU_SG_REL_ LEH_Hybrid SG_ 1714 UH_Stunde 5000;
BA_REL_ "GenSigTimeoutTime" BU_SG_REL_ BMS_Hybrid SG_ 1714 UH_Stunde 5000;
BA_REL_ "GenSigTimeoutTime" BU_SG_REL_ Airbag SG_ 1714 UH_Stunde 5000;
BA_REL_ "GenSigTimeoutTime" BU_SG_REL_ Ladegeraet_PAG_PF SG_ 1714 UH_Minute 5000;
BA_REL_ "GenSigTimeoutTime" BU_SG_REL_ Motor_EDC17_Pirol SG_ 1714 UH_Minute 5000;
BA_REL_ "GenSigTimeoutTime" BU_SG_REL_ PSM_Ant_Derivate SG_ 1714 UH_Minute 5000;
BA_REL_ "GenSigTimeoutTime" BU_SG_REL_ Waehlhebel SG_ 1714 UH_Minute 5000;
BA_REL_ "GenSigTimeoutTime" BU_SG_REL_ Getriebe_Derivate SG_ 1714 UH_Minute 5000;
BA_REL_ "GenSigTimeoutTime" BU_SG_REL_ Motor_MED17_Hybrid SG_ 1714 UH_Minute 5000;
BA_REL_ "GenSigTimeoutTime" BU_SG_REL_ LEH_Hybrid SG_ 1714 UH_Minute 5000;
BA_REL_ "GenSigTimeoutTime" BU_SG_REL_ BMS_Hybrid SG_ 1714 UH_Minute 5000;
BA_REL_ "GenSigTimeoutTime" BU_SG_REL_ Airbag SG_ 1714 UH_Minute 5000;
BA_REL_ "GenSigTimeoutTime" BU_SG_REL_ Airbag SG_ 1714 Kombi_02_alt 5000;
BA_REL_ "GenSigTimeoutTime" BU_SG_REL_ BMS_Hybrid SG_ 1714 Kombi_02_alt 5000;
BA_REL_ "GenSigTimeoutTime" BU_SG_REL_ LEH_Hybrid SG_ 1714 Kombi_02_alt 5000;
BA_REL_ "GenSigTimeoutTime" BU_SG_REL_ Waehlhebel SG_ 1714 Kombi_02_alt 5000;
BA_REL_ "GenSigTimeoutTime" BU_SG_REL_ Ladegeraet_PAG_PF SG_ 1714 UH_Sekunde 5000;
BA_REL_ "GenSigTimeoutTime" BU_SG_REL_ Motor_EDC17_Pirol SG_ 1714 UH_Sekunde 5000;
BA_REL_ "GenSigTimeoutTime" BU_SG_REL_ PSM_Ant_Derivate SG_ 1714 UH_Sekunde 5000;
BA_REL_ "GenSigTimeoutTime" BU_SG_REL_ Waehlhebel SG_ 1714 UH_Sekunde 5000;
BA_REL_ "GenSigTimeoutTime" BU_SG_REL_ Getriebe_Derivate SG_ 1714 UH_Sekunde 5000;
BA_REL_ "GenSigTimeoutTime" BU_SG_REL_ Motor_MED17_Hybrid SG_ 1714 UH_Sekunde 5000;
BA_REL_ "GenSigTimeoutTime" BU_SG_REL_ LEH_Hybrid SG_ 1714 UH_Sekunde 5000;
BA_REL_ "GenSigTimeoutTime" BU_SG_REL_ BMS_Hybrid SG_ 1714 UH_Sekunde 5000;
BA_REL_ "GenSigTimeoutTime" BU_SG_REL_ Airbag SG_ 1714 UH_Sekunde 5000;
BA_REL_ "GenSigTimeoutTime" BU_SG_REL_ Ladegeraet_PAG_PF SG_ 1714 DGN_Verlernzaehler 5000;
BA_REL_ "GenSigTimeoutTime" BU_SG_REL_ Waehlhebel SG_ 1714 DGN_Verlernzaehler 5000;
BA_REL_ "GenSigTimeoutTime" BU_SG_REL_ LEH_Hybrid SG_ 1714 DGN_Verlernzaehler 5000;
BA_REL_ "GenSigTimeoutTime" BU_SG_REL_ BMS_Hybrid SG_ 1714 DGN_Verlernzaehler 5000;
BA_REL_ "GenSigTimeoutTime" BU_SG_REL_ Airbag SG_ 1714 DGN_Verlernzaehler 5000;
BA_REL_ "GenSigTimeoutTime" BU_SG_REL_ Ladegeraet_PAG_PF SG_ 1714 KBI_Kilometerstand 5000;
BA_REL_ "GenSigTimeoutTime" BU_SG_REL_ Motor_EDC17_Pirol SG_ 1714 KBI_Kilometerstand 5000;
BA_REL_ "GenSigTimeoutTime" BU_SG_REL_ PSM_Ant_Derivate SG_ 1714 KBI_Kilometerstand 5000;
BA_REL_ "GenSigTimeoutTime" BU_SG_REL_ Waehlhebel SG_ 1714 KBI_Kilometerstand 5000;
BA_REL_ "GenSigTimeoutTime" BU_SG_REL_ Motor_MED17_Hybrid SG_ 1714 KBI_Kilometerstand 5000;
BA_REL_ "GenSigTimeoutTime" BU_SG_REL_ LEH_Hybrid SG_ 1714 KBI_Kilometerstand 5000;
BA_REL_ "GenSigTimeoutTime" BU_SG_REL_ BMS_Hybrid SG_ 1714 KBI_Kilometerstand 5000;
BA_REL_ "GenSigTimeoutTime" BU_SG_REL_ Getriebe_Derivate SG_ 1714 KBI_Kilometerstand 5000;
BA_REL_ "GenSigTimeoutTime" BU_SG_REL_ Airbag SG_ 1714 KBI_Kilometerstand 5000;
BA_REL_ "GenSigTimeoutTime" BU_SG_REL_ PSM_Ant_Derivate SG_ 1714 Uhrzeit_01_alt 5000;
BA_REL_ "GenSigTimeoutTime" BU_SG_REL_ Airbag SG_ 1714 Uhrzeit_01_alt 5000;
BA_REL_ "GenSigTimeoutTime" BU_SG_REL_ BMS_Hybrid SG_ 1714 Uhrzeit_01_alt 5000;
BA_REL_ "GenSigTimeoutTime" BU_SG_REL_ LEH_Hybrid SG_ 1714 Uhrzeit_01_alt 5000;
BA_REL_ "GenSigTimeoutTime" BU_SG_REL_ Waehlhebel SG_ 1714 Uhrzeit_01_alt 5000;
BA_REL_ "GenSigTimeoutTime" BU_SG_REL_ Ladegeraet_PAG_PF SG_ 1714 Uhrzeit_01_alt 5000;
BA_REL_ "GenSigTimeoutTime" BU_SG_REL_ Motor_EDC17_Pirol SG_ 1313 STH_LED 2000;
BA_REL_ "GenSigTimeoutTime" BU_SG_REL_ Motor_EDC17_Pirol SG_ 1313 STH_EKP_Anst 2000;
BA_REL_ "GenSigTimeoutTime" BU_SG_REL_ Motor_EDC17_Pirol SG_ 1313 STH_Motorvorwaermung 2000;
BA_REL_ "GenSigTimeoutTime" BU_SG_REL_ Motor_EDC17_Pirol SG_ 1313 STH_war_aktiv 2000;
BA_REL_ "GenSigTimeoutTime" BU_SG_REL_ Motor_EDC17_Pirol SG_ 134 LWI_01_CHK 500;
BA_REL_ "GenSigTimeoutTime" BU_SG_REL_ Motor_MED17_Hybrid SG_ 134 LWI_01_CHK 500;
BA_REL_ "GenSigTimeoutTime" BU_SG_REL_ Motor_EDC17_Pirol SG_ 134 LWI_01_BZ 500;
BA_REL_ "GenSigTimeoutTime" BU_SG_REL_ Motor_MED17_Hybrid SG_ 134 LWI_01_BZ 500;
BA_REL_ "GenSigTimeoutTime" BU_SG_REL_ Motor_EDC17_Pirol SG_ 134 LWI_Sensorstatus 500;
BA_REL_ "GenSigTimeoutTime" BU_SG_REL_ Motor_MED17_Hybrid SG_ 134 LWI_Sensorstatus 500;
BA_REL_ "GenSigTimeoutTime" BU_SG_REL_ Motor_EDC17_Pirol SG_ 134 LWI_QBit_Lenkradwinkel 500;
BA_REL_ "GenSigTimeoutTime" BU_SG_REL_ Motor_MED17_Hybrid SG_ 134 LWI_QBit_Lenkradwinkel 500;
BA_REL_ "GenSigTimeoutTime" BU_SG_REL_ Motor_EDC17_Pirol SG_ 134 LWI_Lenkradwinkel 500;
BA_REL_ "GenSigTimeoutTime" BU_SG_REL_ Motor_MED17_Hybrid SG_ 134 LWI_Lenkradwinkel 500;
BA_REL_ "GenSigTimeoutTime" BU_SG_REL_ Motor_EDC17_Pirol SG_ 134 LWI_VZ_Lenkradwinkel 500;
BA_REL_ "GenSigTimeoutTime" BU_SG_REL_ Motor_MED17_Hybrid SG_ 134 LWI_VZ_Lenkradwinkel 500;
BA_REL_ "GenSigTimeoutTime" BU_SG_REL_ Motor_EDC17_Pirol SG_ 1633 AAG_BZ 1000;
BA_REL_ "GenSigTimeoutTime" BU_SG_REL_ Motor_MED17_Hybrid SG_ 1633 AAG_BZ 1000;
BA_REL_ "GenSigTimeoutTime" BU_SG_REL_ Motor_EDC17_Pirol SG_ 1633 AAG_Bremsl_durch_ECD 1000;
BA_REL_ "GenSigTimeoutTime" BU_SG_REL_ Motor_MED17_Hybrid SG_ 1633 AAG_Bremsl_durch_ECD 1000;
BA_REL_ "GenSigTimeoutTime" BU_SG_REL_ Motor_EDC17_Pirol SG_ 1633 AAG_Anhaenger_erkannt 1000;
BA_REL_ "GenSigTimeoutTime" BU_SG_REL_ Motor_MED17_Hybrid SG_ 1633 AAG_Anhaenger_erkannt 1000;
BA_REL_ "GenSigTimeoutTime" BU_SG_REL_ Motor_EDC17_Pirol SG_ 1633 AAG_Bremslicht_H_def 1000;
BA_REL_ "GenSigTimeoutTime" BU_SG_REL_ Motor_MED17_Hybrid SG_ 1633 AAG_Bremslicht_H_def 1000;
BA_REL_ "GenSigTimeoutTime" BU_SG_REL_ Getriebe_Derivate SG_ 780 ACC_02_CHK 500;
BA_REL_ "GenSigTimeoutTime" BU_SG_REL_ Getriebe_Derivate SG_ 780 ACC_02_BZ 500;
BA_REL_ "GenSigTimeoutTime" BU_SG_REL_ Getriebe_Derivate SG_ 780 ACC_Wunschgeschw 500;
BA_REL_ "GenSigTimeoutTime" BU_SG_REL_ Getriebe_Derivate SG_ 1743 NMH_EM_Start_1 2000;
BA_REL_ "GenSigTimeoutTime" BU_SG_REL_ BMS_Hybrid SG_ 1743 NMH_EM_Start_1 2000;
BA_REL_ "GenSigTimeoutTime" BU_SG_REL_ Motor_MED17_Hybrid SG_ 1743 NMH_EM_Start_1 2000;
BA_REL_ "GenSigTimeoutTime" BU_SG_REL_ Ladegeraet_PAG_PF SG_ 1743 NMH_EM_Start_1 2000;
BA_REL_ "GenSigTimeoutTime" BU_SG_REL_ GW_Routing_Derivate SG_ 786 TSK_03_CHK 500;
BA_REL_ "GenSigTimeoutTime" BU_SG_REL_ Getriebe_Derivate SG_ 786 TSK_03_CHK 500;
BA_REL_ "GenSigTimeoutTime" BU_SG_REL_ GW_Routing_Derivate SG_ 786 TSK_03_BZ 500;
BA_REL_ "GenSigTimeoutTime" BU_SG_REL_ Getriebe_Derivate SG_ 786 TSK_03_BZ 500;
BA_REL_ "GenSigTimeoutTime" BU_SG_REL_ GW_Routing_Derivate SG_ 786 FAS_Wunschgeschw 500;
BA_REL_ "GenSigTimeoutTime" BU_SG_REL_ Getriebe_Derivate SG_ 786 FAS_Wunschgeschw 500;
BA_REL_ "GenSigTimeoutTime" BU_SG_REL_ GW_Routing_Derivate SG_ 786 FAS_Texte_Primaeranz 500;
BA_REL_ "GenSigTimeoutTime" BU_SG_REL_ GW_Routing_Derivate SG_ 786 FAS_Status_Prim_Anz 500;
BA_REL_ "GenSigTimeoutTime" BU_SG_REL_ GW_Routing_Derivate SG_ 786 FAS_Status_Anzeige 500;
BA_REL_ "GenSigTimeoutTime" BU_SG_REL_ GW_Routing_Derivate SG_ 16 WFS_MSG1_IMS 500;
BA_REL_ "HYB_Tx_Baureihe" BU_BO_REL_ GW_Routing_Derivate 1532 2;
BA_REL_ "HYB_Tx_Baureihe" BU_BO_REL_ GW_Routing_Derivate 1860 2;
BA_REL_ "HYB_Tx_Baureihe" BU_BO_REL_ GW_Routing_Derivate 1483 2;
BA_REL_ "HYB_Tx_Baureihe" BU_BO_REL_ GW_Routing_Derivate 899 2;
BA_REL_ "HYB_Tx_Baureihe" BU_BO_REL_ GW_Routing_Derivate 1518 2;
BA_REL_ "HYB_Tx_Baureihe" BU_BO_REL_ GW_Routing_Derivate 25 2;
BA_REL_ "HYB_Tx_Baureihe" BU_BO_REL_ GW_Routing_Derivate 1603 2;
BA_REL_ "HYB_Tx_Baureihe" BU_BO_REL_ GW_Routing_Derivate 267 2;
BA_REL_ "HYB_Tx_Verwendung" BU_BO_REL_ GW_Routing_Derivate 267 1;
BA_REL_ "HYB_Tx_Baureihe" BU_BO_REL_ GW_Routing_Derivate 260 2;
BA_REL_ "HYB_Tx_Baureihe" BU_BO_REL_ GW_Routing_Derivate 1313 2;
BA_REL_ "HYB_Tx_Baureihe" BU_BO_REL_ GW_Routing_Derivate 134 2;
BA_REL_ "HYB_Tx_Baureihe" BU_BO_REL_ GW_Routing_Derivate 1633 2;
BA_REL_ "HYB_Tx_Baureihe" BU_BO_REL_ GW_Routing_Derivate 780 2;
VAL_ 1445 OBC_CVN_VLD 0 "ungueltig" 1 "gueltig" ;
VAL_ 1527 RW_Sekundaer_Reichweite 2045 "nicht_verbaut" 2046 "Init" 2047 "Fehler" ;
VAL_ 1527 RW_Sek_Reichweitenv_Einheit 0 "Liter_pro_100km" 1 "kWh_pro_100km" 2 "Kg_pro_100km" 3 "nicht_verbaut" ;
VAL_ 1527 RW_Sek_Reichweitenverbrauch 2047 "Init" ;
VAL_ 1525 RW_RWDS_Lastprofil 2046 "Init" 2047 "Fehler" ;
VAL_ 1525 RW_Gesamt_Reichweite 2045 "nicht_verbaut" 2046 "Init" 2047 "Fehler" ;
VAL_ 1525 RW_Prim_Reichweitenverbrauch 2047 "Init" ;
VAL_ 1525 RW_Prim_Reichweitenv_Einheit 0 "Liter_pro_100km" 1 "kWh_pro_100km" 2 "Kg_pro_100km" 3 "nicht_verbaut" ;
VAL_ 1525 RW_Primaer_Reichweite 2045 "nicht_verbaut" 2046 "Init" 2047 "Fehler" ;
VAL_ 687 BMS_Rekuperation_Ueberlauf 0 "kein_Ueberlauf" 1 "Ueberlauf" ;
VAL_ 687 BMS_Verbrauch_Ueberlauf 0 "kein_Ueberlauf" 1 "Ueberlauf" ;
VAL_ 1532 KL_Autobetrieb_HL 0 "kein_Autobetrieb" 1 "Autobetrieb" ;
VAL_ 1532 KL_Autobetrieb_HR 0 "kein_Autobetrieb" 1 "Autobetrieb" ;
VAL_ 1532 KL_Autobetrieb_VL 0 "kein_Autobetrieb" 1 "Autobetrieb" ;
VAL_ 1532 KL_Autobetrieb_VR 0 "kein_Autobetrieb" 1 "Autobetrieb" ;
VAL_ 1532 KL_Zieltemperatur_HL 0 "Lo" 29 "Hi" 30 "Init" 31 "Fehler" ;
VAL_ 1532 KL_Zieltemperatur_HR 0 "Lo" 29 "Hi" 30 "Init" 31 "Fehler" ;
VAL_ 1532 KL_Zieltemperatur_VL 0 "Lo" 29 "Hi" 30 "Init" 31 "Fehler" ;
VAL_ 1532 KL_Zieltemperatur_VR 0 "Lo" 29 "Hi" 30 "Init" 31 "Fehler" ;
VAL_ 1788 NMH_Ladegeraet_Start_1 1 "Zustand Start (<--Sleep)" ;
VAL_ 1788 NMH_Ladegeraet_Start_2 1 "Zustand Start (<--Prepare to Sleep)" ;
VAL_ 1788 NMH_Ladegeraet_Normal_Mode_1 1 "Zustand Normal Mode (<-- Start)" ;
VAL_ 1788 NMH_Ladegeraet_Normal_Mode_2 1 "Zustand Normal Mode (<-- Ready to Sleep)" ;
VAL_ 1788 NMH_Ladegeraet_Per_WakeUp 0 "wenn_Funktionswakeup" 1 "CAN" 2 "P_Wakeup__Ursache_nicht_bekannt" 3 "Kl_15_Hardware_falls_vorhanden" ;
VAL_ 1788 NMH_Ladegeraet_Fkt_WakeUp 0 "wenn Peripheriewakeup" 1 "niedriger_SOC_12V_Bat" 2 "zeitversetztes_Laden" ;
VAL_ 1788 NMH_Ladegeraet_Klemme_15 1 "Klemme 15 ein" ;
VAL_ 1788 NMH_Ladegeraet_Diagnose 1 "Diagnose bei Kl.15 AUS" ;
VAL_ 1788 NMH_Ladegeraet_MindestAktivZeit 1 "aktiv" ;
VAL_ 1788 NMH_Ladegeraet_Signalfehler 1 "Aktiver_Signalfehler_eingetragen" ;
VAL_ 1788 NMH_Ladegeraet_TimeOut_Fehler 1 "Aktiver Timeout Fehlerspeichereintrag" ;
VAL_ 1788 NMH_Ladegeraet_CAN_Diag_deaktiv 1 "CAN Bus bezogene Eigendiagnose deaktiviert " ;
VAL_ 1788 NMH_Ladegeraet_KompSchutz 1 "KS aktiv" ;
VAL_ 1788 NMH_Ladegeraet_Mute_Mode 1 "Mute Mode aktiv" ;
VAL_ 1788 NMH_Ladegeraet_Transport_Mode 1 "Transportmodus aktiv" ;
VAL_ 1788 NMH_Ladegeraet_Abschaltstufe_000 1 "Funktionsabschaltung wegen Abschaltschaltstufe" ;
VAL_ 1788 NMH_Ladegeraet_Eindraht_Fehler 1 "Eindrahtbetrieb erkannt" ;
VAL_ 1788 NMH_Ladegeraet_Lokalaktiv 0 "war_nicht_lokal_aktiv" 1 "war_lokal_aktiv" ;
VAL_ 1788 NMH_Ladegeraet_Subsystemaktiv 0 "Subsystem war nicht lokalaktiv" 1 "war Lokalaktiv" ;
VAL_ 1483 PTC_Wassereinlasstemp 254 "Init" 255 "Fehler" ;
VAL_ 1483 PTC_Wasserauslasstemp 254 "Init" 255 "Fehler" ;
VAL_ 1483 PTC_HV_I_ist 254 "Init" 255 "Fehler" ;
VAL_ 1483 KL_T_Charge 0 "Taster nicht betaetigt" 1 "Taster betaetigt" ;
VAL_ 1483 KBT_Defrost_aktiv 0 "inaktiv" 1 "aktiv" ;
VAL_ 1483 KL_WunschStrom_HV 254 "Init" 255 "Fehler" ;
VAL_ 1483 KL_BattKond_WaPu_DZMax 62 "Init" 63 "Fehler" ;
VAL_ 1483 KL_Standklima_Status 0 "Standklimatisierung_aus" 1 "Standklimatisierung_ein" 2 "Nicht_moeglich_Aussenhuelle_offen" 3 "Abbruch_Aussenhuelle_geoeffnet" 4 "Nicht_moeglich_Keine_Aktivierung_HV_Bordnetz" 5 "Abbruch_HV_Bordnetz_deaktiviert" 6 "Nicht_moeglich_Batterie_Prio" 7 "On_hold_Keine_Freigabe_HV_Komponenten" ;
VAL_ 899 CHA_Ziel_FahrPr_BMS 0 "nicht_belegt" 1 "FahrPr_1" 2 "FahrPr_2" 3 "FahrPr_3" 4 "FahrPr_4" 5 "FahrPr_5" 6 "FahrPr_6" 7 "FahrPr_7" ;
VAL_ 1518 KL_T_STH 1 "Taster betätigt" 0 "Taster nicht betätigt" ;
VAL_ 1518 Klima_08_PAG_alt 0 "aktuell" 1 "veraltet" ;
VAL_ 391 MO_Tankbereitschaft_Status 0 "keine_Aktion_Init" 1 "Tankbereitschaft_wird_hergestellt" 2 "Tankbereitschaft_ist_hergestellt" 3 "Tankbereitschaft_kann_nicht_hergestellt_werden" 4 "Tanksystem_Systemfehler" 5 "Tankklappe_pruefen_schliessen" 6 "Tankvorgang_abgebrochen" ;
VAL_ 391 MO_Tankklappensteuerung 0 "Init_nicht_verbaut" 1 "Tankklappe_soll_entriegeln" 2 "Tankklappe_soll_verriegeln" 3 "keine_Aktion" ;
VAL_ 391 MO_HVEM_MaxLeistung 510 "Init" 511 "Fehler" ;
VAL_ 391 EV_Rekuperationsstufe 0 "keine_Anzeige" 1 "1" 2 "2" 3 "3" 4 "4" 5 "5" ;
VAL_ 391 MO_Waehlpos 0 "Init_nicht_unterstuetzt" 1 "reserviert" 2 "P" 3 "R" 4 "N" 5 "D" 6 "B" 7 "Fehler" ;
VAL_ 391 HV_Bordnetz_aktiv 0 "inaktiv" 1 "aktiv" ;
VAL_ 391 MO_HVEM_Eskalation 0 "keine_Eskalation_HVEM" 1 "Eskalation_HVEM" ;
VAL_ 1662 LAD_Abregelung_Temperatur 0 "keine_Begrenzung" 1 "Abregelung_Temp" ;
VAL_ 1662 LAD_Abregelung_IU_Ein_Aus 0 "keine_Abregelung" 1 "Abregelung_UI" ;
VAL_ 1662 LAD_Abregelung_BuchseTemp 0 "keine_Abregelung" 1 "Abregelung_Buchsentemp" ;
VAL_ 1662 LAD_MaxLadLeistung_HV 510 "Init" 511 "Fehler" ;
VAL_ 1662 LAD_CP_Stromlimit 126 "Init" 127 "Fehler" ;
VAL_ 1662 LAD_PRX_Stromlimit 0 "13_Ampere" 1 "20_Ampere" 2 "32_Ampere" 3 "63_Ampere" 6 "Init" 7 "Fehler" ;
VAL_ 1662 LAD_CP_Erkennung 0 "CP_nicht_erkannt" 1 "CP_erkannt" ;
VAL_ 1662 LAD_Stecker_Verriegelt 0 "nicht_verriegelt" 1 "verriegelt" ;
VAL_ 1662 LAD_Stecker_Gesteckt 0 "kein_Stecker_erkannt" 1 "Stecker_erkannt" ;
VAL_ 1662 LAD_Kuehlbedarf 0 "kein_Kuehlbedarf" 1 "geringer_Kuehlbedarf" 2 "mittlerer_Kuehlbedarf" 3 "hoher_Kuehlbedarf" ;
VAL_ 1662 LAD_Warnzustand 0 "keine_Warnung" 1 "Warnung_aktiv" ;
VAL_ 1662 LAD_Fehlerzustand 0 "kein_Fehler_aktiv" 1 "Fehler_aktiv_Laden_beendet" ;
VAL_ 1662 LAD_Fehlerstatus 0 "Komponente_IO" 1 "Eingeschr_KompFkt_DC_Lad_NIO" 2 "Eingeschr_KompFkt_AC_Lad_NIO" 3 "Eingeschr_KompFkt_Interlock" 4 "Eingeschr_KompFkt_reserve" 5 "Eingeschr_KompFkt_reserve" 6 "Keine_Komponentenfunktion" 7 "Init" ;
VAL_ 1662 LAD_Warnlampe_Anf 0 "Init" 1 "Fehlerlampe_gelb" ;
VAL_ 1380 LAD_IstModus 0 "Standby" 1 "Netzladung" 2 "ext_Steuerung" 5 "int_Fehler" 7 "Init" ;
VAL_ 1380 LAD_AC_Istspannung 510 "Init" 511 "Fehler" ;
VAL_ 1380 LAD_IstSpannung_HV 1022 "Init" 1023 "Fehler" ;
VAL_ 1380 LAD_IstStrom_HV 1022 "Init" 1023 "Fehler" ;
VAL_ 1380 LAD_Status_Spgfreiheit 0 "Init" 1 "HV_Komponente_spannungsfrei" 2 "HV_Komp_nicht_spannungsfrei" 3 "Fehler_nicht_spannungsfrei" ;
VAL_ 1380 LAD_Temperatur 254 "Init" 255 "Fehler" ;
VAL_ 1380 LAD_Verlustleistung 254 "Init" 255 "Fehler" ;
VAL_ 1385 HVEM_Abschaltstatus 0 "100" 1 "75" 2 "50" 3 "25" 7 "Init" ;
VAL_ 1385 HVEM_LeistunsAnf 0 "nicht_angefordert" 1 "angefordert" ;
VAL_ 1385 HVEM_Nachlad_Status 0 "nicht_moeglich__Fehler" 1 "moeglich__begonnen" 2 "Beendet" 3 "Init" ;
VAL_ 1385 HVEM_Anf_ReichweiteNV 0 "keine_Massnahme_notwendig" 1 "Reduktion_Stufe_1" 2 "Reduktion_Stufe_2" 3 "Fehler" ;
VAL_ 1385 HVEM_HV_Anf 0 "keine_Anforderung" 1 "HV_angefordert" ;
VAL_ 1385 HVEM_Text_1 0 "kein_Text" 1 "Text" ;
VAL_ 1385 HVEM_Nachladen_Anf 0 "keine_Anforderung" 1 "Nachladen_angefordert" ;
VAL_ 1385 HVEM_FreigabeKlimatisierung 0 "keine_Freigabe" 1 "Freigabe" 2 "Init" 3 "Fehler" ;
VAL_ 1482 BMS_Energieinhalt 2046 "Init" 2047 "Fehler" ;
VAL_ 1482 BMS_Ladevorgang_aktiv 0 "inaktiv" 1 "aktiv" ;
VAL_ 1482 BMS_MaxEnergieinhalt 2046 "Init" 2047 "Fehler" ;
VAL_ 1482 BMS_Ausgleichsladung_Anf 1 "Balancing_Request" ;
VAL_ 1482 BMS_Gesamtst_Spgfreiheit 0 "Funktion_nicht_aktiviert" 1 "HV_System_spannungsfrei" 2 "HV_System_nicht_spannungsfrei" 3 "Fehler_nicht_spannungsfrei" ;
VAL_ 1519 BMS_IstStrom 4094 "Init" 4095 "Fehler" ;
VAL_ 1519 BMS_PTC_Stufe 14 "Init" 15 "Fehler" ;
VAL_ 1519 BMS_PTC_IstStrom 254 "Init" 255 "Fehler" ;
VAL_ 1519 BMS_Status_Kuehlung 0 "Off" 1 "Umwaelzen zum Heizen" 2 "Umwaelzen zum Kuehlen" 3 "passive Kuehlung (NT-Kuehler und Chiller)" 4 "passive Kuehlung" 5 "passive Kuehlung mit Luefter" 6 "aktive Kuehlung (NT-Kuehlerund Chiller)" 7 "aktive Kuehlung (nur Chiller, Voll-Last)" 14 "Init" 15 "Fehler" ;
VAL_ 1519 BMS_Temp_Zelle_Min 254 "Init" 255 "Fehler" ;
VAL_ 1519 BMS_Temp_Zelle_Max 254 "Init" 255 "Fehler" ;
VAL_ 1519 BMS_Pumpendrehzahl 254 "Init" 255 "Fehler" ;
VAL_ 1519 BMS_Status_3_2_Ventil1 0 "Leitung NT-Kuehler und Chiller offen" 1 "Leitung NT-Kuehler offen, Chiller geschlossen" 2 "Leitung NT-Kuehler geschlossen, Chiller offen" 6 "Init" 7 "Fehler" ;
VAL_ 1519 BMS_Status_3_2_Ventil2 0 "Leitung NT-Kuehler und Chiller offen" 1 "Leitung NT-Kuehler offen, Chiller geschlossen" 2 "Leitung NT-Kuehler geschlossen, Chiller offen" 6 "Init" 7 "Fehler" ;
VAL_ 1438 BMS_Temperierung_Anf 0 "hoher_Kuehlbedarf" 1 "mittlerer_Kuehlbedarf" 2 "niedriger_Kuehlbedarf" 3 "kein_Temperierungsbedarf_Init" 4 "niedriger_Heizbedarf" 5 "mittlerer_Heizbedarf" 6 "hoher_Heizbedarf" 7 "Umwaelzungsbedarf" ;
VAL_ 1438 BMS_Soll_PWM_Pumpe 15 "Init" ;
VAL_ 1438 BMS_Temperatur 254 "Init" 255 "Fehler" ;
VAL_ 1438 BMS_IstVorlaufTemperatur 254 "Init" 255 "Fehler" ;
VAL_ 1438 BMS_SollVolumenstrom 62 "Init" 63 "Fehler" ;
VAL_ 1438 BMS_SollVorlauftemperatur 254 "Init" 255 "Fehler" ;
VAL_ 1438 BMS_IstRuecklaufTemperatur_02 254 "Init" 255 "Fehler" ;
VAL_ 1428 HVLM_HV_Anf 0 "keine_Anforderung" 1 "Laden_angefordert" 2 "Batteriekonditionierung_angefordert" 3 "Standklimatisierung_angefordert" ;
VAL_ 1428 HVLM_Stecker_Status 0 "Init" 1 "kein_Stecker_gesteckt" 2 "Stecker_erkannt_nicht_verriegelt" 3 "Stecker_erkannt_und_verriegelt" ;
VAL_ 1428 HVLM_Restladezeit_HV_Bat_02 510 "Init" 511 "Fehler" ;
VAL_ 1428 HVLM_Lademodus_HV_Bat 0 "Sofortlademodus" 1 "zeitversetztes_Laden" ;
VAL_ 1428 HVLM_Bat_laden_aktiv 0 "inaktiv" 1 "aktiv" ;
VAL_ 1428 HVLM_Ladeart 0 "keine_Anf" 1 "AC_Laden" 2 "DC_Laden" 3 "Konditionierung" ;
VAL_ 1428 HVLM_VK_Anf 0 "nicht_angefordert" 1 "angefordert" ;
VAL_ 1428 HVLM_Ladesystemhinweise 0 "kein_Hinweis" 1 "Ladesystem_defekt" 2 "Ladesaeule_inkompatibel" 3 "DC_Laden_nicht_moeglich" ;
VAL_ 1428 HVLM_Langzeit_Laden 0 "keine_Anforderung" 1 "Anforderung_Reduzierung_Batterie_SOC_auf_Stufe_1" 2 "Anforderung_Reduzierung_Batterie_SOC_auf_Stufe_2" 3 "Fehler" ;
VAL_ 1428 HVLM_Klima_Temp 29 "VW_high_30C" 30 "Init" 31 "Fehler" ;
VAL_ 1428 HVLM_VK_Modus 0 "keine Vorkonditionierung" 1 "Sofort-Konditionierung" 2 "zeitversetzte Konditionierung" 3 "Fehler" ;
VAL_ 1428 HVLM_HSH_Anf 0 "keine_Anforderung" 1 "Heckscheibenheizung_Anf" ;
VAL_ 1603 KBI_Einheit_Verbrauch_elektr 0 "kWh_pro_100km" 1 "kWh_pro_100mls" 2 "km_pro_kWh" 3 "mls_pro_kWh" 4 "MPGe" ;
VAL_ 1603 KBI_Einheit_Datum 3 "reserviert" 2 "Jahr/Monat/Tag" 1 "Monat/Tag/Jahr" 0 "Tag/Monat/Jahr" ;
VAL_ 1603 KBI_Einheit_Streckenanz 0 "Kilometer" 1 "Meilen" ;
VAL_ 1603 KBI_Einheit_Temp 1 "Grad Fahrenheit °F" 0 "Grad Celsius °C" ;
VAL_ 1603 KBI_Einheit_Uhrzeit 1 "12h AM/PM" 0 "24h" ;
VAL_ 1603 KBI_Einheit_Sprache 255 "Fehler" 13 "Russisch" 12 "Portugiesisch" 11 "Türkisch" 10 "Schwedisch" 9 "Dänisch" 8 "Holländisch" 7 "Chinesisch (Simplified Chinese)" 6 "Japanisch (Katakana)" 5 "Italienisch" 4 "Spanisch" 3 "Französisch" 2 "US-Englisch" 1 "Englisch" 0 "Deutsch" ;
VAL_ 1603 KBI_Einheit_Volumen 3 "reserviert" 0 "Liter" 1 "Gallonen_UK" 2 "Gallonen_USA" ;
VAL_ 1603 KBI_Einheit_Verbrauch 1 "mpg USA" 2 "Liter/100km" 0 "mpg UK" 3 "km/Liter" ;
VAL_ 1603 KBI_MFA_v_Einheit_02 1 "mph" 0 "kmh" ;
VAL_ 1603 KBI_Einheit_Druck 3 "tbd" 2 "Druckangabe in kPa" 1 "Druckangabe in psi" 0 "Druckangabe in bar" ;
VAL_ 267 MFL_Tip_Up 1 "betätigt" 0 "nicht betätigt" ;
VAL_ 267 MFL_Tip_Down 1 "betätigt" 0 "nicht betätigt" ;
VAL_ 267 LS_Tiptronic_Fehler 1 "Fehler" 0 "kein Fehler" ;
VAL_ 267 LS_Tip_Wiederaufnahme 1 "Tippschalter betaetigt" 0 "Tippschalter nicht betaetigt" ;
VAL_ 267 LS_Tip_Setzen 1 "Tippschalter betaetigt" 0 "Tippschalter nicht betaetigt" ;
VAL_ 267 LS_Tip_Runter 1 "Tippschalter betaetigt" 0 "Tippschalter nicht betaetigt" ;
VAL_ 267 LS_Tip_Hoch 1 "Tippschalter betaetigt" 0 "Tippschalter nicht betaetigt" ;
VAL_ 267 LS_Limiter 1 "ein" 0 "aus" ;
VAL_ 267 LS_Hauptschalter 1 "Ein" 0 "Gerastet Aus" ;
VAL_ 267 LS_Fehler 1 "Fehler Bedienteil" 0 "in Ordnung" ;
VAL_ 267 LS_Codierung 7 "nicht verwendet" 6 "nicht verwendet" 5 "ACC Hebel, Tiptronic am Lenkrad" 4 "ACC Hebel, keine Tiptronic am Lenkrad" 3 "GRA Hebel, Tiptronic am Lenkrad" 2 "GRA Hebel, keine Tiptronic am Lenkrad" 1 "kein Hebel, Tiptronic am Lenkrad" 0 "kein Hebel, keine Tiptronic am Lenkrad" ;
VAL_ 267 LS_Abbrechen 1 "Tippschalter betätigt" 0 "Tippschalter nicht betätigt" ;
VAL_ 267 MFL_M_Taste 1 "Taster betätigt" 0 "Taster nicht betätigt" ;
VAL_ 267 LS_Tip_Stufe_2 0 "Hebelbetaetigung_in_erster_Tipstufe__Keine_Hebelbetaetigung" 1 "Hebelbetaetigung_in_der_zweiten_Tipstufe" ;
VAL_ 267 LS_GRA_ACC_2stufig 0 "kein_zweistufiger_Hebel_verbaut" 1 "zweistufiger_Hebel_verbaut" ;
VAL_ 260 EPB_Konsistenz_ACC 1 "Fehler" 0 "kein Fehler" ;
VAL_ 260 EPB_Anfahrwunsch_erkannt 1 "Anfahrwunsch erkannt" 0 "kein Anfahrwunsch erkannt" ;
VAL_ 260 EPB_Pedalweg_Kuppl 0 "Init" 255 "Fehler" ;
VAL_ 260 EPB_Fehlerstatus 2 "EPB temporär nicht verfügbar - Spannen nicht möglich da Fzg. in Fahrt" 1 "EPB temporär nicht verfügbar - AVH darf nicht aktiv werden, sondern muss bei AVH-Anforderung warnen" 3 "Fehler in EPB - AVH darf von ESP nicht ausgeführt werden" 0 "kein Fehler in EPB - AVH darf von ESP ausgeführt werden" ;
VAL_ 260 EPB_Schalterposition 2 "Fahreranforderung_Schliessen" 0 "keine_Fahreranforderung" 1 "Fahreranforderung_Oeffnen" 3 "Schalterfehler" ;
VAL_ 260 EPB_QBit_Schalterpos 1 "Ersatz-, Init- oder Fehlerwert (Schalter ausser Funktion)" 0 "gültiger Wert (volle Funktion)" ;
VAL_ 260 EPB_Spannkraft 30 "Init" 31 "Fehler" ;
VAL_ 260 EPB_Status 3 "unbekannt" 2 "Aktuator im Lauf" 0 "Bremse_geoeffnet" 1 "Bremse_geschlossen" ;
VAL_ 260 EPB_KD_Fehler 1 "mind. ein KD-Fehler vorhanden" 0 "kein KD-Fehler" ;
VAL_ 260 EPB_QBit_Laengsbeschleunigung 1 "Ersatz-, Init- oder Fehlerwert" 0 "gueltiger_Wert" ;
VAL_ 260 EPB_QBit_Pedalweg_Kuppl 1 "Ersatz_Init_Fehlerwert" 0 "gueltiger_Wert" ;
VAL_ 260 EPB_BCM2_Motor_Wakeup 1 "Anforderung an BCM2 Wakeupleitung zum Motor hochzuziehen aufgrund von Car-Wakeup" 0 "keine Anforderung" ;
VAL_ 260 EPB_Freig_Verzoeg_Anf 0 "Verzögerungsanforderung nicht freigegeben" 1 "Verzögerungsanforderung freigegeben" ;
VAL_ 260 EPB_Laengsbeschleunigung 255 "Fehler" 0 "Init" ;
VAL_ 64 AB_Deaktivierung_HV 0 "keine_Deaktivierung" 1 "Deaktivierung_1" 2 "Deaktivierung_2" 3 "Deaktivierung_3" 4 "Deaktivierung_4" 5 "Deaktivierung_5" 6 "Deaktivierung_6" 7 "Deaktivierung_7" ;
VAL_ 64 AB_RGS_Anst 8 "deaktiviert" 7 "aktiv_Niveau_4" 6 "aktiv_Niveau_3" 5 "aktiv_Niveau_2" 4 "aktiv_Niveau_1" ;
VAL_ 64 AB_Texte_AKS 2 "AKS_Systemfehler" 1 "AKS_ausgeloest" 0 "keine_AKS_Ausloesung" ;
VAL_ 64 AB_Front_Crash 1 "Front_Crash" 0 "kein_Front_Crash" ;
VAL_ 64 AB_Heck_Crash 1 "Heck_Crash" 0 "kein_Heck_Crash" ;
VAL_ 64 AB_SF_Crash 0 "kein_Seiten_Crash_Fahrer" 1 "Seiten_Crash_Fahrer" ;
VAL_ 64 AB_SB_Crash 0 "kein_Seiten_Crash_Beifahrer" 1 "Seiten_Crash_Beifahrer" ;
VAL_ 64 AB_Rollover_Crash 0 "kein_Rollover" 1 "Rollover" ;
VAL_ 64 AB_Crash_Int 5 "Crash_Intensität_3 (nur historisch PAG)" 3 "Crash_Intensität_2 (nur D4, C7, Colorado_NF, PAG; Crash B8, Q5)" 0 "kein Crash" 4 "Crash_Intensität_3 (nur Stellgliedtest B8, Q5; historisch VW/Audi)" 2 "Crash_Intensität_2 (nur Stellgliedtest B8, Q5)" 1 "Crash_Intensität_1" 7 "Crash_Intensität_3" ;
VAL_ 64 AB_Lampe 1 "Lampe_an" 0 "Lampe_aus" ;
VAL_ 64 AB_Deaktiviert 0 "Airbag_aktiv" 1 "Airbag_deaktiviert" ;
VAL_ 64 AB_VB_deaktiviert 1 "Beifahrerairbag_deaktiviert" 0 "Beifahrerairbag_aktiv" ;
VAL_ 64 AB_Systemfehler 0 "kein_Fehler" 1 "Systemfehler" ;
VAL_ 64 AB_Diagnose 1 "Airbag_in_Diagnose" 0 "Airbag_nicht_in_Diagnose" ;
VAL_ 64 AB_Anzeige_Fussg 2 "Systemfehler" 1 "Motorhaube_offen" 0 "keine_Anzeige" ;
VAL_ 64 AB_PAO_Leuchte_Anf 1 "an" 0 "aus" ;
VAL_ 64 AB_Stellgliedtest 0 "Airbag_nicht_im_Stellgliedtest" 1 "Airbag_im_Stellgliedtest" ;
VAL_ 64 AB_Erh_Auf_VB 2 "BF_Airbag_aktiviert" 1 "BF_Airbag_deaktiviert" 3 "nicht_benutzt" 0 "keine_Beschreibung" ;
VAL_ 64 AB_Gurtwarn_VF 1 "Warnung_ausloesen" 0 "keine_Warnung" ;
VAL_ 64 AB_Gurtwarn_VB 1 "Warnung_ausloesen" 0 "keine_Warnung" ;
VAL_ 64 AB_KD_Fehler 1 "mind. ein KD-Fehler vorhanden" 0 "kein KD-Fehler" ;
VAL_ 1312 AB_Sitzpos_Sens_BF 3 "Sitz vorne" 2 "Sitz nicht vorne" 1 "Fehler" 0 "nicht verfügbar" ;
VAL_ 1312 AB_Sitzpos_Sens_FA 3 "Sitz vorne" 2 "Sitz nicht vorne" 1 "Fehler" 0 "nicht verfügbar" ;
VAL_ 1312 AB_Gurtschloss_Reihe3_MI 3 "gesteckt" 2 "nicht_gesteckt" 1 "nicht_verfügbar (Fehler oder Init)" 0 "nicht_verbaut" ;
VAL_ 1312 AB_Gurtschloss_Reihe3_FA 3 "gesteckt" 2 "nicht_gesteckt" 1 "nicht_verfügbar (Fehler oder Init)" 0 "nicht_verbaut" ;
VAL_ 1312 AB_Gurtschloss_Reihe3_BF 3 "gesteckt" 2 "nicht_gesteckt" 1 "nicht_verfügbar (Fehler oder Init)" 0 "nicht_verbaut" ;
VAL_ 1312 AB_Gurtschloss_Reihe2_BF 3 "gesteckt" 2 "nicht_gesteckt" 1 "nicht_verfügbar (Fehler oder Init)" 0 "nicht_verbaut" ;
VAL_ 1312 AB_Gurtschloss_Reihe2_MI 3 "gesteckt" 2 "nicht_gesteckt" 1 "nicht_verfügbar (Fehler oder Init)" 0 "nicht_verbaut" ;
VAL_ 1312 AB_Gurtschloss_Reihe2_FA 3 "gesteckt" 2 "nicht_gesteckt" 1 "nicht_verfügbar (Fehler oder Init)" 0 "nicht_verbaut" ;
VAL_ 1312 AB_Gurtschloss_BF 3 "gesteckt" 2 "nicht_gesteckt" 1 "nicht_verfügbar (Fehler oder Init)" 0 "nicht_verbaut" ;
VAL_ 1312 AB_Gurtschloss_FA 3 "gesteckt" 2 "nicht_gesteckt" 1 "nicht_verfügbar (Fehler oder Init)" 0 "nicht_verbaut" ;
VAL_ 1312 AB_Belegung_VB 1 "Fehler" 0 "Nicht_verfuegbar" 3 "Belegt" 2 "Nicht_belegt" ;
VAL_ 777 BEM_Segel_Info 0 "keine_Anforderung" 1 "Mindestdrehzahl_1" 2 "Mindestdrehzahl_2" 3 "Segelveto" ;
VAL_ 777 BEM_n_LLA 3 "Stufe 3" 2 "Stufe 2" 1 "Stufe 1" 0 "keine Erhöhung" ;
VAL_ 777 BEM_Anf_KL 1 "KL_Anf" 0 "keine_Anf" ;
VAL_ 777 BEM_StartStopp_Info 3 "Systemfehler" 2 "Motoranlauf zwingend notwendig (Startanforderung)" 1 "Motoranlauf nicht zwingend notwendig (Stoppverbot, keine Startanforderung, evtl. Komforteinbussen)" 0 "Motorlauf langfristig nicht notwendig (Stoppfreigabe)" ;
VAL_ 1714 Kombi_02_alt 1 "veraltet" 0 "aktuell" ;
VAL_ 1714 DGN_Verlernzaehler 255 "ungültiger Zählerstand oder kein gültiger Fahrzyklus" ;
VAL_ 1714 KBI_Kilometerstand 1048575 "Fehlerwert" 1048574 "Initwert" ;
VAL_ 1714 Uhrzeit_01_alt 0 "aktuell" 1 "veraltet" ;
VAL_ 1313 STH_Zusatzheizung 1 "Zuheizer ein" 0 "Zuheizer aus" ;
VAL_ 1313 STH_EKP_Anst 1 "EKP ansteuern" 0 "EKP nicht ansteuern" ;
VAL_ 1313 STH_Fehlerstatus 2 "Fuel_Low" 0 "kein_Fehler" 1 "Batterie_Low" 3 "Hardware_defekt" 4 "Heizgeraet_verriegelt" ;
VAL_ 1313 STH_Wassertemp 255 "Fehler" 254 "Init" ;
VAL_ 1313 STH_war_aktiv 0 "war_inaktiv" 1 "war_aktiv" ;
VAL_ 134 LWI_QBit_Sub_Daten 0 "Subinfo_real" 1 "Subinfo_simuliert" ;
VAL_ 134 LWI_QBit_Lenkradwinkel 1 "ausserhalb_Spezifikation" 0 "gueltiger_Wert" ;
VAL_ 134 LWI_Lenkradwinkel 8191 "Fehlerwert" 8190 "Initwert" ;
VAL_ 134 LWI_VZ_Lenkradwinkel 0 "positiv_links_von_der_Nullstellung" 1 "negativ" ;
VAL_ 1633 AAG_Bremsl_durch_ECD 1 "Bremslicht durch ECD aktiv" 0 "Bremslicht ist aus" ;
VAL_ 1633 AAG_Anhaenger_abgesteckt 1 "Anhaenger wurde bei Kl. 15 aus abgesteckt" ;
VAL_ 1633 AAG_NSL_aktiv 1 "Anhaenger Nebelschlusslicht aktiv" ;
VAL_ 1633 AAG_Anhaenger_erkannt 0 "kein Anhänger erkannt" 1 "AAG Anhänger erkannt" ;
VAL_ 1633 AAG_Blinker_H_aktiv 1 "Anhaenger Blinker aktiv" ;
VAL_ 1633 AAG_Blinker_HL_def 1 "Anhaenger Blinker links defekt" ;
VAL_ 1633 AAG_Blinker_HR_def 1 "Anhaenger Blinker rechts defekt" ;
VAL_ 1633 AAG_Bremslicht_H_def 1 "Anhaenger Bremslicht defekt" ;
VAL_ 1633 AAG_Schlusslicht_HL_def 1 "Anhaenger Schlußlicht links defekt" ;
VAL_ 1633 AAG_Schlusslicht_HR_def 1 "Anhaenger Schlußlicht rechts defekt" ;
VAL_ 1633 AAG_KD_Fehler 1 "mind. ein KD-Fehler vorhanden" 0 "kein KD-Fehler" ;
VAL_ 1633 AAG_AVS_Fehler 2 "n.i.O. + Fahrzeugstopp erforderlich" 3 "t.b.d." 0 "i.O." 1 "n.i.O." ;
VAL_ 1633 AAG_AVS_Stati 1 "Endlage Ausgefahren erreicht" 3 "Einfahren Automatik" 2 "Ausfahren Automatik" 5 "Einfahren Manuell" 6 "Zwischenposition" 7 "nicht initialisiert" 0 "Endlage Eingefahren erreicht" 4 "Ausfahren Manuell" ;
VAL_ 780 ACC_Wunschgeschw_erreicht 0 "Wunschgeschwindigkeit_nicht_erreicht" 1 "Wunschgeschwindigkeit_erreicht" ;
VAL_ 780 ACC_Abstandsindex 1023 "Sonderanzeige_Fahrbahn_mit_gruenem_roten_Bereich" 1022 "Sonderanzeige_graue_Fahrbahn" 0 "Sonderanzeige_graue_Fahrbahn" ;
VAL_ 780 ACC_Display_Prio 1 "mittlere_Prio" 0 "hoechste_Prio" 3 "keine_Prio" 2 "geringe_Prio" ;
VAL_ 780 ACC_Relevantes_Objekt 0 "Symbol_nicht_beleuchtet" 1 "Farbe_1" 3 "Farbe_3" 2 "Farbe_2 - nur bei Porsche gilt fuer '2' Warnaufforderung (Kritikalitaet > Schwelle )" ;
VAL_ 780 ACC_Texte_Primaeranz 21 "VDA ACC-Symbol YYY km/h / mph" 7 "Auto_ _Auto_ _ Gong (durchgestrichen)" 2 "Auto_Auto_ _ _" 17 "Herunterschalten" 13 "ACC nicht verfuegbar" 5 "Auto_ _ _ _Auto" 9 "Auto_ _ _ _Auto Gong (durchgestrichen)" 44 "HDC aktiv" 3 "Auto_ _Auto_ _" 1 "ACC nicht verfuegbar !" 8 "Auto_ _ _Auto_ Gong (durchgestrichen)" 6 "Auto_Auto_ _ _ Gong (durchgestrichen)" 18 "Parkbremse !" 20 "Waehlhebelposition !" 14 "o  o  o" 16 "ESP Eingriff" 4 "Auto_ _ _Auto_" 10 "ACC bereit" 12 "ACC Sensor Sicht !" 15 "Hochschalten" 19 "Geschwindigkeitsgrenze" 0 "keine Anzeige " 11 "keine Abstandsregelung" 27 "--- km/h / mph" 38 "Kurvenassistent aus" 39 "Tempolimit aus" 42 "Ortsende XXX km/h / mph" 25 "Symbol 'Eieruhr'" 45 "braking guard Bremsruck" 35 "Fahrer Gurtschloss offen !" 24 "ACC Abschaltung" 28 "XXX km/h / mph (Schriftart 2)" 36 "Schalthebelposition !" 23 "Kurve XXX km/h / mph" 34 "Tuer offen !" 40 "Abbiegeassistent" 31 "Fahrzeug verloren" 29 "Lenkradwinkel" 33 "Ungueltiger Anfahrbefehl" 46 "braking guard aus " 47 "braking guard aus" 41 "Ortsanfang XXX km/h / mph" 26 "!" 32 "Im Stand nicht moeglich" 43 "Tempolimit Ende XXX km/h / mph" 22 "Tempolimit XXX km/h / mph" 30 "Anfahren bestaetigen" 57 "ACC haelt an !" 52 "SET / 'GRA Symbol' xxx km/h / mph" 66 "ESP PASSIV !" 61 "LIM AKTIV " 60 "LIM AUS" 50 "Stehendes Objekt voraus" 58 "Bremse betaetigen !" 62 "LIM PASSIV" 65 "Bremse haelt !" 51 "SET / 'GRA Symbol'___xxx km/h / mph" 63 "LIM FEHLER" 49 "Steigung zu gross" 48 "Uebernehmen !" 54 "ACC startet" 37 "Drehzahl !" 59 "Kupplung betaetigt" 64 "Bremse ueberhitzt !" 53 "ACC aus" 56 "ACC Fehler" 55 "ACC reinigen" ;
VAL_ 780 ACC_Status_Anzeige 0 "ACC_OFF" 2 "ACC_STANDBY" 1 "ACC_INIT" 7 "ACC_FEHLER_IRREVERS" 3 "ACC_AKTIV" 4 "ACC_OVERRIDE" 6 "ACC_FEHLER_REVERS" ;
VAL_ 1743 NMH_EM_keine_HV_Entl 0 "kein_Nachlauf" 1 "HV_Entladung_nicht_moeglich" ;
VAL_ 1743 NMH_EM_Start_1 1 "Zustand Start (<--Sleep)" ;
VAL_ 1743 NMH_EM_Start_2 1 "Zustand Start (<--Prepare to Sleep)" ;
VAL_ 1743 NMH_EM_Normal_Mode_1 1 "Zustand Normal Mode (<-- Start)" ;
VAL_ 1743 NMH_EM_Normal_Mode_2 1 "Zustand Normal Mode (<-- Ready to Sleep)" ;
VAL_ 1743 NMH_EM_Car_WakeUp 1 "Car Wake Up" ;
VAL_ 1743 NMH_EM_Per_WakeUp 3 "KL_15_Hardware_falls_vorhanden" 2 "P_WakeUp_Ursache_unbekannt" 0 "Funktions-WakeUp" 1 "CAN" ;
VAL_ 1743 NMH_EM_Fkt_WakeUp 0 "Peripheriewakeup" ;
VAL_ 1743 NMH_EM_Klemme_15 1 "Klemme 15 ein" ;
VAL_ 1743 NMH_EM_Diagnose 1 "Diagnose bei Kl 15 aus" ;
VAL_ 1743 NMH_EM_MindestAktivZeit 1 "aktiv" ;
VAL_ 1743 NMH_EM_NL_Datem_EEPROM 0 "kein_Nachlauf" 1 "EEPROM_schreibzugriff" ;
VAL_ 1743 NMH_EM_Signalfehler 1 "Aktiver_Signalfehler_eingetragen" ;
VAL_ 1743 NMH_EM_TimeOut_Fehler 1 "Aktiver Timeout Fehlerspeichereintrag" ;
VAL_ 1743 NMH_EM_CAN_Diag_deaktiv 1 "CAN Bus bezogene Eigendiagnose deaktiviert" ;
VAL_ 1743 NMH_EM_KompSchutz 1 "KS aktiv" ;
VAL_ 1743 NMH_EM_Mute_Mode 1 "Mute Mode aktiv" ;
VAL_ 1743 NMH_EM_Transport_Mode 1 "Transportmodus aktiv" ;
VAL_ 1743 NMH_EM_Abschaltstufe_aktiv 1 "Funktionsabschaltung wegen Abschaltschaltstufe" ;
VAL_ 1743 NMH_EM_Busfehler 1 "Busfehler" ;
VAL_ 1743 NMH_EM_Lokalaktiv 0 "war_nicht_lokal_aktiv" 1 "war_lokal_aktiv" ;
VAL_ 1743 NMH_EM_Subsystemaktiv 1 "war Lokalaktiv" 0 "Subsystem war nicht lokalaktiv" ;
VAL_ 786 FAS_Wunschgeschw 1023 "nicht definiert" 1022 "keine Anzeige" ;
VAL_ 786 FAS_Texte_Primaeranz 66 "ESP PASSIV !" 65 "Bremse haelt !" 64 "Bremse ueberhitzt !" 63 "LIM FEHLER" 62 "LIM PASSIV" 61 "LIM AKTIV " 60 "LIM AUS" 59 "Kupplung betaetigt" 58 "Bremse betaetigen !" 57 "ACC haelt an !" 56 "ACC Fehler" 55 "ACC reinigen" 54 "ACC startet" 53 "ACC aus" 52 "SET / 'GRA Symbol' xxx km/h / mph" 51 "SET / 'GRA Symbol'___xxx km/h / mph" 50 "Stehendes Objekt voraus" 49 "Steigung zu gross" 48 "Uebernehmen !" 47 "braking guard aus" 46 "braking guard aus " 45 "braking guard Bremsruck" 44 "HDC aktiv" 43 "Tempolimit Ende XXX km/h / mph" 42 "Ortsende XXX km/h / mph" 41 "Ortsanfang XXX km/h / mph" 40 "Abbiegeassistent" 39 "Tempolimit aus" 38 "Kurvenassistent aus" 37 "Drehzahl !" 36 "Schalthebelposition !" 35 "Fahrer Gurtschloss offen !" 34 "Tuer offen !" 33 "Ungueltiger Anfahrbefehl" 32 "Im Stand nicht moeglich" 31 "Fahrzeug verloren" 30 "Anfahren bestaetigen" 29 "Lenkradwinkel" 28 "XXX km/h / mph (Schriftart 2)" 27 "--- km/h / mph" 26 "!" 25 "Symbol 'Eieruhr'" 24 "ACC Abschaltung" 23 "Kurve XXX km/h / mph" 22 "Tempolimit XXX km/h / mph" 21 "VDA ACC-Symbol YYY km/h / mph" 20 "Waehlhebelposition !" 19 "Geschwindigkeitsgrenze" 18 "Parkbremse !" 17 "Herunterschalten" 16 "ESP Eingriff" 15 "Hochschalten" 14 "o  o  o" 13 "ACC nicht verfuegbar" 12 "ACC Sensor Sicht !" 11 "keine Abstandsregelung" 10 "ACC bereit" 9 "Auto_ _ _ _Auto Gong (durchgestrichen)" 8 "Auto_ _ _Auto_ Gong (durchgestrichen)" 7 "Auto_ _Auto_ _ Gong (durchgestrichen)" 6 "Auto_Auto_ _ _ Gong (durchgestrichen)" 5 "Auto_ _ _ _Auto" 4 "Auto_ _ _Auto_" 3 "Auto_ _Auto_ _" 2 "Auto_Auto_ _ _" 1 "ACC nicht verfuegbar !" 0 "keine Anzeige " ;
VAL_ 786 FAS_Status_Prim_Anz 3 "Farbe 3 (typisch 'gelb')" 2 "Farbe 2 (typisch 'rot')" 1 "Farbe 1 (typisch 'grün')" 0 "Symbol nicht beleuchtet" ;
VAL_ 786 FAS_Status_Anzeige 7 "ACC/GRA irreversibel aus" 6 "ACC reversibel aus (nicht bei GRA)" 5 "frei" 4 "ACC/GRA im Hintergrund (übertreten)" 3 "ACCGRA aktiv" 2 "ACC/GRA passiv" 1 "ACC in Init (nicht bei GRA)" 0 "ACC/GRA Hauptschalter aus" ;
